VERSION ""

NS_ :

BS_:

BU_: SCM BC1 BC2 ECM PSC ABS Brakes__Drive_Axle_1 EPS IC GPS WCM VCM Seat_Control_1 ISC1 HCU IDT GMRS XM RH AUTON LHC CIM IMU BC3 IC2 EPC1 EPC2 EPC3 EPC4 BMC1 BMC2 APU2 APU1 SRVTOOL RHC RCM

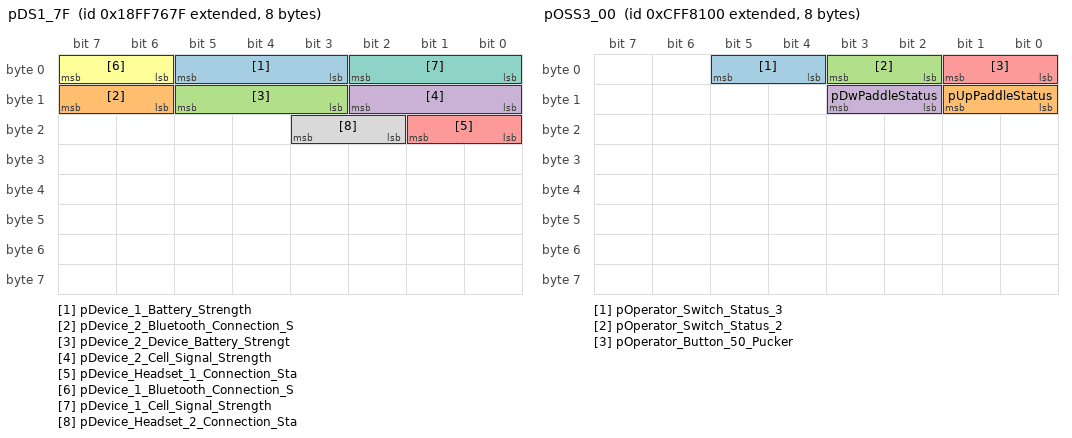
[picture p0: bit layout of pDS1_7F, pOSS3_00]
BO_ 2566878847 pDS1_7F: 8 RH
 SG_ pDevice_1_Battery_Strength : 3|3@1+ (1,0) [0|7] "state" Vector__XXX
 SG_ pDevice_2_Bluetooth_Connection_S : 14|2@1+ (1,0) [0|3] "state" Vector__XXX
 SG_ pDevice_2_Device_Battery_Strengt : 11|3@1+ (1,0) [0|7] "state" Vector__XXX
 SG_ pDevice_2_Cell_Signal_Strength : 8|3@1+ (1,0) [0|7] "state" Vector__XXX
 SG_ pDevice_Headset_1_Connection_Sta : 16|2@1+ (1,0) [0|3] "state" Vector__XXX
 SG_ pDevice_1_Bluetooth_Connection_S : 6|2@1+ (1,0) [0|3] "state" Vector__XXX
 SG_ pDevice_1_Cell_Signal_Strength : 0|3@1+ (1,0) [0|7] "state" Vector__XXX
 SG_ pDevice_Headset_2_Connection_Sta : 18|2@1+ (1,0) [0|3] "state" Vector__XXX

BO_ 2566834815 DM1_7F: 42 RH
 SG_ Flash_Malfunction_Indicator_Lamp : 14|2@1+ (1,0) [0|3] "" Vector__XXX
 SG_ Malfunction_Indicator_Lamp_Statu : 6|2@1+ (1,0) [0|3] "" Vector__XXX
 SG_ Red_Stop_Lamp_Status : 4|2@1+ (1,0) [0|3] "" Vector__XXX
 SG_ Amber_Warning_Lamp_Status : 2|2@1+ (1,0) [0|3] "" Vector__XXX
 SG_ Flash_Red_Stop_Lamp_RSL : 12|2@1+ (1,0) [0|3] "" Vector__XXX
 SG_ Flash_Amber_Warning_Lamp_AWL : 10|2@1+ (1,0) [0|3] "" Vector__XXX
 SG_ Flash_Protect_Lamp : 8|2@1+ (1,0) [0|3] "" Vector__XXX
 SG_ Protect_Lamp_Status : 0|2@1+ (1,0) [0|3] "" Vector__XXX
 SG_ DTC_1 : 16|32@1+ (1,0) [0|4294967295] "value" Vector__XXX
 SG_ DTC_2 : 48|32@1+ (1,0) [0|4294967295] "value" Vector__XXX
 SG_ DTC_3 : 80|32@1+ (1,0) [0|4294967295] "value" Vector__XXX
 SG_ DTC_4 : 112|32@1+ (1,0) [0|4294967295] "value" Vector__XXX
 SG_ DTC_5 : 144|32@1+ (1,0) [0|4294967295] "value" Vector__XXX
 SG_ DTC_6 : 176|32@1+ (1,0) [0|4294967295] "value" Vector__XXX
 SG_ DTC_7 : 208|32@1+ (1,0) [0|4294967295] "value" Vector__XXX
 SG_ DTC_8 : 240|32@1+ (1,0) [0|4294967295] "value" Vector__XXX
 SG_ DTC_9 : 272|32@1+ (1,0) [0|4294967295] "value" Vector__XXX
 SG_ DTC_10 : 304|32@1+ (1,0) [0|4294967295] "value" Vector__XXX

BO_ 2566842495 VDS_7F: 8 RH
 SG_ Compass_Bearing : 0|16@1+ (0.0078125,0) [0|511] "deg" Vector__XXX

BO_ 2561212287 DISP1_7F: 0 RH
 SG_ Text_Display_Character : 24|1@1+ (0,0) [0|-1] "ASCII" Vector__XXX
 SG_ Text_Display_Index : 16|8@1+ (1,0) [0|255] "count" Vector__XXX
 SG_ Text_Display_Instructions : 0|4@1+ (1,0) [0|15] "bit" Vector__XXX

BO_ 2365531268 pVMC_84: 8 AUTON
 SG_ pEPSReqMod : 8|8@1+ (1,0) [0|255] "state" Vector__XXX

BO_ 2365554944 pOSS3_00: 8 ECM
 SG_ pOperator_Switch_Status_3 : 4|2@1+ (1,0) [0|3] "state" RHC
 SG_ pUpPaddleStatus : 8|2@1+ (1,0) [0|3] "state" RHC
 SG_ pOperator_Switch_Status_2 : 2|2@1+ (1,0) [0|3] "state" RHC
 SG_ pDwPaddleStatus : 10|2@1+ (1,0) [0|3] "state" RHC
 SG_ pOperator_Button_50_Pucker : 0|2@1+ (1,0) [0|3] "state" RHC

BO_ 2566834823 DM1_87: 42 LHC
 SG_ Flash_Malfunction_Indicator_Lamp : 14|2@1+ (1,0) [0|3] "" Vector__XXX
 SG_ Malfunction_Indicator_Lamp_Statu : 6|2@1+ (1,0) [0|3] "" Vector__XXX
 SG_ Red_Stop_Lamp_Status : 4|2@1+ (1,0) [0|3] "" Vector__XXX
 SG_ Amber_Warning_Lamp_Status : 2|2@1+ (1,0) [0|3] "" Vector__XXX
 SG_ Flash_Red_Stop_Lamp_RSL : 12|2@1+ (1,0) [0|3] "" Vector__XXX
 SG_ Flash_Amber_Warning_Lamp_AWL : 10|2@1+ (1,0) [0|3] "" Vector__XXX
 SG_ Flash_Protect_Lamp : 8|2@1+ (1,0) [0|3] "" Vector__XXX
 SG_ Protect_Lamp_Status : 0|2@1+ (1,0) [0|3] "" Vector__XXX
 SG_ DTC_1 : 16|32@1+ (1,0) [0|4294967295] "value" Vector__XXX
 SG_ DTC_2 : 48|32@1+ (1,0) [0|4294967295] "value" Vector__XXX
 SG_ DTC_3 : 80|32@1+ (1,0) [0|4294967295] "value" Vector__XXX
 SG_ DTC_4 : 112|32@1+ (1,0) [0|4294967295] "value" Vector__XXX
 SG_ DTC_5 : 144|32@1+ (1,0) [0|4294967295] "value" Vector__XXX
 SG_ DTC_6 : 176|32@1+ (1,0) [0|4294967295] "value" Vector__XXX
 SG_ DTC_7 : 208|32@1+ (1,0) [0|4294967295] "value" Vector__XXX
 SG_ DTC_8 : 240|32@1+ (1,0) [0|4294967295] "value" Vector__XXX
 SG_ DTC_9 : 272|32@1+ (1,0) [0|4294967295] "value" Vector__XXX
 SG_ DTC_10 : 304|32@1+ (1,0) [0|4294967295] "value" Vector__XXX

BO_ 2432656519 pISC_87: 8 LHC
 SG_ Source : 8|2@1+ (1,0) [0|3] "state" Vector__XXX
 SG_ Squelch_SQ_Up : 18|2@1+ (1,0) [0|3] "state" Vector__XXX
 SG_ MutePreset : 10|2@1+ (1,0) [0|3] "state" Vector__XXX
 SG_ Volume_Down : 0|2@1+ (1,0) [0|3] "state" Vector__XXX
 SG_ Volume_Up : 2|2@1+ (1,0) [0|3] "state" Vector__XXX
 SG_ Tune_Up : 6|2@1+ (1,0) [0|3] "state" Vector__XXX
 SG_ Seek_Up : 42|2@1+ (1,0) [0|3] "state" Vector__XXX
 SG_ Tune_Down : 4|2@1+ (1,0) [0|3] "state" Vector__XXX
 SG_ Squelch_SQ_Down : 16|2@1+ (1,0) [0|3] "state" Vector__XXX
 SG_ pInfotainment_Joystick_1 : 24|4@1+ (1,0) [0|15] "state" Vector__XXX
 SG_ Preset : 22|2@1+ (1,0) [0|3] "state" Vector__XXX
 SG_ Seek_Down : 44|2@1+ (1,0) [0|3] "state" Vector__XXX
 SG_ pInfotainment_Joystick_2 : 32|4@1+ (1,0) [0|15] "state" Vector__XXX
 SG_ ICOM : 12|2@1+ (1,0) [0|3] "state" Vector__XXX
 SG_ Push_To_Talk_PTT : 20|2@1+ (1,0) [0|3] "state" Vector__XXX
 SG_ pMultifunction_Infotainment_Inte : 46|2@1+ (1,0) [0|3] "state" Vector__XXX
 SG_ COM : 14|2@1+ (1,0) [0|3] "state" Vector__XXX
 SG_ PlayPause : 40|2@1+ (1,0) [0|3] "state" Vector__XXX

BO_ 2566860167 pISM_87: 8 LHC
 SG_ pSpecial_Msg_12 : 22|2@1+ (1,0) [0|3] "state" Vector__XXX
 SG_ pSpecial_Msg_28 : 54|2@1+ (1,0) [0|3] "state" Vector__XXX
 SG_ pSpecial_Msg_11 : 20|2@1+ (1,0) [0|3] "state" Vector__XXX
 SG_ pSpecial_Msg_26 : 50|2@1+ (1,0) [0|3] "state" Vector__XXX
 SG_ pSpecial_Msg_24 : 46|2@1+ (1,0) [0|3] "state" Vector__XXX
 SG_ pSpecial_Msg_21 : 40|2@1+ (1,0) [0|3] "state" Vector__XXX
 SG_ pSpecial_Msg_18 : 34|2@1+ (1,0) [0|3] "state" Vector__XXX
 SG_ pSpecial_Msg_19 : 36|2@1+ (1,0) [0|3] "state" Vector__XXX
 SG_ pSpecial_Msg_1_Riding_with_Brake : 0|2@1+ (1,0) [0|3] "state" Vector__XXX
 SG_ pSpecial_Msg_2_Regulator_Overhea : 2|2@1+ (1,0) [0|3] "state" Vector__XXX
 SG_ pSpecial_Msg_3_Regulator_Overhea : 4|2@1+ (1,0) [0|3] "state" Vector__XXX
 SG_ pSpecial_Msg_4_Regulator_Overhea : 6|2@1+ (1,0) [0|3] "state" Vector__XXX
 SG_ pSpecial_Msg_5_Engine_Warmup_Com : 8|2@1+ (1,0) [0|3] "state" Vector__XXX
 SG_ pSpecial_Msg_6_Engine_Knock__Mod : 10|2@1+ (1,0) [0|3] "state" Vector__XXX
 SG_ pSpecial_Msg_8_Low_Coolant_Warni : 14|2@1+ (1,0) [0|3] "state" Vector__XXX
 SG_ pSpecial_Msg_7_Engine_Knock__Mos : 12|2@1+ (1,0) [0|3] "state" Vector__XXX
 SG_ pSpecial_Msg_9_Transmission_Temp : 16|2@1+ (1,0) [0|3] "state" Vector__XXX
 SG_ pSpecial_Msg_10_Reverse_Speed_Li : 18|2@1+ (1,0) [0|3] "state" Vector__XXX
 SG_ pSpecial_Msg_13_Belt_Burn_Warnin : 24|2@1+ (1,0) [0|3] "state" Vector__XXX
 SG_ pSpecial_Msg_14_Park_Brake_Warni : 26|2@1+ (1,0) [0|3] "state" Vector__XXX
 SG_ pSpecial_Msg_15_TCM_Comm_Loss : 28|2@1+ (1,0) [0|3] "state" Vector__XXX
 SG_ pSpecial_Msg_16_TCM_Pump_Priming : 30|2@1+ (1,0) [0|3] "state" Vector__XXX
 SG_ pSpecial_Msg_17_Request_User_to_ : 32|2@1+ (1,0) [0|3] "state" Vector__XXX
 SG_ pSpecial_MSG_20_Fuel_Door_Open_E : 38|2@1+ (1,0) [0|3] "state" Vector__XXX
 SG_ pSpecial_MSG_22_Clutch_Overtemp : 42|2@1+ (1,0) [0|3] "state" Vector__XXX
 SG_ pSpecial_MSG_23_Exhaust_Valve_Ch : 44|2@1+ (1,0) [0|3] "state" Vector__XXX
 SG_ pSpecial_MSG_25_Engine_Idle_Shut : 48|2@1+ (1,0) [0|3] "state" Vector__XXX
 SG_ pSpecial_MSG_27_Overboost_Condit : 52|2@1+ (1,0) [0|3] "state" Vector__XXX
 SG_ pSpecial_Msg_31_Engine_Tip_Over_ : 60|2@1+ (1,0) [0|3] "state" Vector__XXX
 SG_ pSpecial_Msg_32_Engine_Tip_Over_ : 62|2@1+ (1,0) [0|3] "state" Vector__XXX

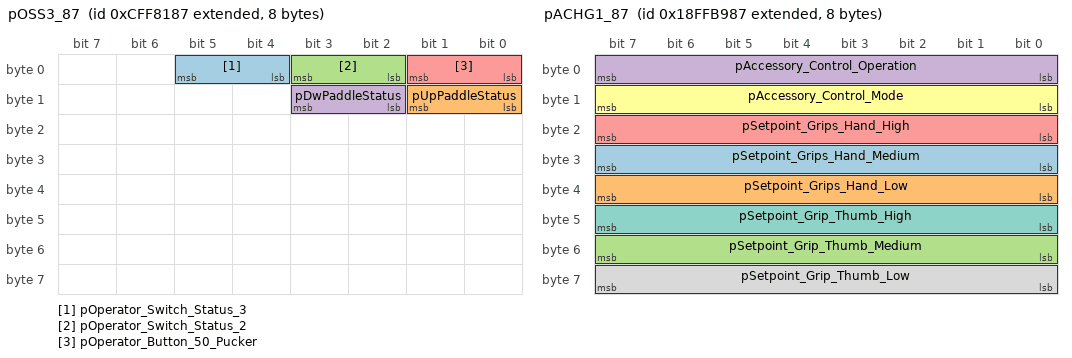
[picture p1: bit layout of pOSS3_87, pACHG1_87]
BO_ 2365555079 pOSS3_87: 8 LHC
 SG_ pOperator_Switch_Status_3 : 4|2@1+ (1,0) [0|3] "state" Vector__XXX
 SG_ pUpPaddleStatus : 8|2@1+ (1,0) [0|3] "state" Vector__XXX
 SG_ pOperator_Switch_Status_2 : 2|2@1+ (1,0) [0|3] "state" Vector__XXX
 SG_ pDwPaddleStatus : 10|2@1+ (1,0) [0|3] "state" Vector__XXX
 SG_ pOperator_Button_50_Pucker : 0|2@1+ (1,0) [0|3] "state" Vector__XXX

BO_ 2566896007 pACHG1_87: 8 LHC
 SG_ pSetpoint_Grips_Hand_Medium : 24|8@1+ (1,0) [0|255] "deg C" Vector__XXX
 SG_ pSetpoint_Grips_Hand_Low : 32|8@1+ (1,0) [0|255] "deg C" Vector__XXX
 SG_ pSetpoint_Grip_Thumb_Medium : 48|8@1+ (1,0) [0|255] "deg C" Vector__XXX
 SG_ pAccessory_Control_Operation : 0|8@1+ (1,0) [0|255] "state" Vector__XXX
 SG_ pSetpoint_Grips_Hand_High : 16|8@1+ (1,0) [0|255] "deg C" Vector__XXX
 SG_ pAccessory_Control_Mode : 8|8@1+ (1,0) [0|255] "state" Vector__XXX
 SG_ pSetpoint_Grip_Thumb_High : 40|8@1+ (1,0) [0|255] "deg C" Vector__XXX
 SG_ pSetpoint_Grip_Thumb_Low : 56|8@1+ (1,0) [0|255] "deg C" Vector__XXX

BO_ 2566844807 CCVS1_87: 8 LHC
 SG_ Cruise_Control_Set_Speed : 40|8@1+ (1,0) [0|255] "km/h" Vector__XXX
 SG_ Cruise_Control_Active : 24|2@1+ (1,0) [0|3] "bit" Vector__XXX
 SG_ Clutch_Switch : 30|2@1+ (1,0) [0|3] "bit" Vector__XXX
 SG_ Brake_Switch : 28|2@1+ (1,0) [0|3] "bit" Vector__XXX
 SG_ pCC_Message_Counter : 52|4@1+ (1,0) [0|15] "count" Vector__XXX
 SG_ Cruise_Control_Pause_Switch : 4|2@1+ (1,0) [0|3] "bit" Vector__XXX
 SG_ Cruise_Control_Set_Switch : 32|2@1+ (1,0) [0|3] "bit" Vector__XXX
 SG_ Two_Speed_Axle_Switch : 0|2@1+ (1,0) [0|3] "bit" Vector__XXX
 SG_ Cruise_Control_Enable_Switch : 26|2@1+ (1,0) [0|3] "bit" Vector__XXX
 SG_ pOdometer_Drive_Bit : 6|2@1+ (1,0) [0|3] "state" Vector__XXX
 SG_ pCC_Checksum : 56|8@1+ (1,0) [0|255] "" Vector__XXX
 SG_ WheelBased_Vehicle_Speed : 8|16@1+ (0.00390625,0) [0|255] "km/h" Vector__XXX
 SG_ Cruise_Control_Resume_Switch : 36|2@1+ (1,0) [0|3] "bit" Vector__XXX
 SG_ Cruise_Control_Accelerate_Switch : 38|2@1+ (1,0) [0|3] "bit" Vector__XXX
 SG_ pCruise_Enable_Status : 48|4@1+ (1,0) [0|15] "state" Vector__XXX
 SG_ Parking_Brake_Switch : 2|2@1+ (1,0) [0|3] "bit" Vector__XXX
 SG_ Cruise_Control_Coast_Decelerate_ : 34|2@1+ (1,0) [0|3] "bit" Vector__XXX

BO_ 2566835079 DM2_87: 42 LHC
 SG_ Protect_Lamp_Status : 0|2@1+ (1,0) [0|3] "" Vector__XXX
 SG_ Amber_Warning_Lamp_Status : 2|2@1+ (1,0) [0|3] "" Vector__XXX
 SG_ Red_Stop_Lamp_Status : 4|2@1+ (1,0) [0|3] "" Vector__XXX
 SG_ Malfunction_Indicator_Lamp_Statu : 6|2@1+ (1,0) [0|3] "" Vector__XXX
 SG_ Flash_Protect_Lamp : 8|2@1+ (1,0) [0|3] "" Vector__XXX
 SG_ Flash_Amber_Warning_Lamp_AWL : 10|2@1+ (1,0) [0|3] "" Vector__XXX
 SG_ Flash_Red_Stop_Lamp_RSL : 12|2@1+ (1,0) [0|3] "" Vector__XXX
 SG_ Flash_Malfunction_Indicator_Lamp : 14|2@1+ (1,0) [0|3] "" Vector__XXX
 SG_ DTC_1 : 16|32@1+ (1,0) [0|4294967295] "value" Vector__XXX
 SG_ DTC_2 : 48|32@1+ (1,0) [0|4294967295] "value" Vector__XXX
 SG_ DTC_3 : 80|32@1+ (1,0) [0|4294967295] "value" Vector__XXX
 SG_ DTC_4 : 112|32@1+ (1,0) [0|4294967295] "value" Vector__XXX
 SG_ DTC_5 : 144|32@1+ (1,0) [0|4294967295] "value" Vector__XXX
 SG_ DTC_6 : 176|32@1+ (1,0) [0|4294967295] "value" Vector__XXX
 SG_ DTC_7 : 208|32@1+ (1,0) [0|4294967295] "value" Vector__XXX
 SG_ DTC_8 : 240|32@1+ (1,0) [0|4294967295] "value" Vector__XXX
 SG_ DTC_9 : 272|32@1+ (1,0) [0|4294967295] "value" Vector__XXX
 SG_ DTC_10 : 304|32@1+ (1,0) [0|4294967295] "value" Vector__XXX

BO_ 2432656775 pOSS1_87: 8 LHC
 SG_ Key_Fob_Unlock_Button_Status : 30|2@1+ (1,0) [0|3] "state" Vector__XXX
 SG_ Homelink_2 : 44|2@1+ (1,0) [0|3] "state" Vector__XXX
 SG_ Side_Stand_Switch : 56|2@1+ (1,0) [0|3] "state" Vector__XXX
 SG_ Key_Fob_Lock_Button_Status : 32|2@1+ (1,0) [0|3] "state" Vector__XXX
 SG_ Windshield__2_Down : 50|2@1+ (1,0) [0|3] "state" Vector__XXX
 SG_ Turn__3_Cancel : 14|2@1+ (1,0) [0|3] "state" Vector__XXX
 SG_ Reverse : 40|2@1+ (1,0) [0|3] "state" Vector__XXX
 SG_ Hazard : 16|2@1+ (1,0) [0|3] "state" Vector__XXX
 SG_ Homelink_1 : 42|2@1+ (1,0) [0|3] "state" Vector__XXX
 SG_ Windshield__1_Up : 48|2@1+ (1,0) [0|3] "state" Vector__XXX
 SG_ Front_Brake_Switch : 52|2@1+ (1,0) [0|3] "state" Vector__XXX
 SG_ Instrument_Cluster_Control__2 : 2|2@1+ (1,0) [0|3] "state" Vector__XXX
 SG_ Chassis_Unlock_Button_Status : 34|2@1+ (1,0) [0|3] "state" Vector__XXX
 SG_ Power_Button : 58|2@1+ (1,0) [0|3] "state" Vector__XXX
 SG_ RunStop_Switch : 38|2@1+ (1,0) [0|3] "state" Vector__XXX
 SG_ Headlamp__2_High : 6|2@1+ (1,0) [0|3] "state" Vector__XXX
 SG_ Instrument_Cluster_Control__1 : 0|2@1+ (1,0) [0|3] "state" Vector__XXX
 SG_ Clutch_Switch : 54|2@1+ (1,0) [0|3] "state" Vector__XXX
 SG_ Start : 26|2@1+ (1,0) [0|3] "state" Vector__XXX
 SG_ Headlamp__3_Driving : 8|2@1+ (1,0) [0|3] "state" Vector__XXX
 SG_ Cruise__2_Set : 20|2@1+ (1,0) [0|3] "state" Vector__XXX
 SG_ Windshield_Wiper : 36|2@1+ (1,0) [0|3] "state" Vector__XXX
 SG_ Fog : 28|2@1+ (1,0) [0|3] "state" Vector__XXX
 SG_ Cruise__3_Accel : 22|2@1+ (1,0) [0|3] "state" Vector__XXX
 SG_ Horn : 24|2@1+ (1,0) [0|3] "state" Vector__XXX
 SG_ Turn__2_Right : 12|2@1+ (1,0) [0|3] "state" Vector__XXX
 SG_ Cruise__1_On : 18|2@1+ (1,0) [0|3] "state" Vector__XXX
 SG_ Turn__1_Left : 10|2@1+ (1,0) [0|3] "state" Vector__XXX
 SG_ Throttle_Safety_Switch__1 : 46|2@1+ (1,0) [0|3] "state" Vector__XXX
 SG_ Headlamp__1_Low : 4|2@1+ (1,0) [0|3] "state" Vector__XXX
 SG_ Chassis_Lock_Switch_Status : 62|2@1+ (1,0) [0|3] "unknown" Vector__XXX
 SG_ Fuel_Door_Unlock_Button_Status : 60|2@1+ (1,0) [0|3] "state" Vector__XXX

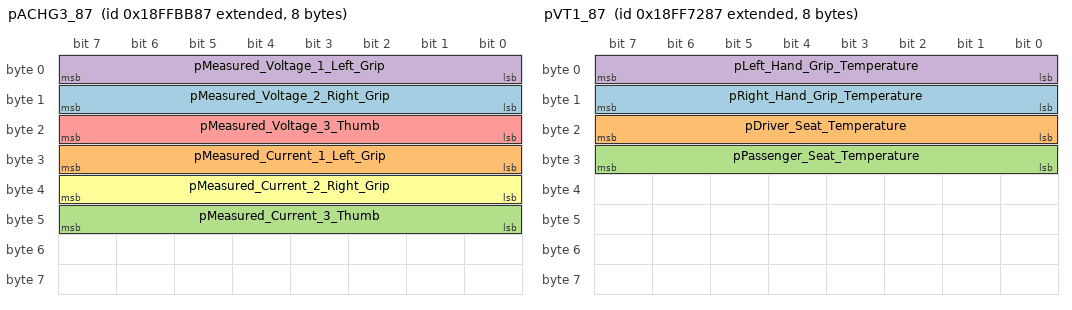
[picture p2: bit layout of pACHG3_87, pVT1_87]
BO_ 2566896519 pACHG3_87: 8 LHC
 SG_ pMeasured_Voltage_2_Right_Grip : 8|8@1+ (0.075,0) [0|18.2] "V" Vector__XXX
 SG_ pMeasured_Current_1_Left_Grip : 24|8@1+ (0.05,0) [0|11.8] "A" Vector__XXX
 SG_ pMeasured_Current_3_Thumb : 40|8@1+ (0.05,0) [0|11.8] "A" Vector__XXX
 SG_ pMeasured_Voltage_1_Left_Grip : 0|8@1+ (0.075,0) [0|18.2] "V" Vector__XXX
 SG_ pMeasured_Voltage_3_Thumb : 16|8@1+ (0.075,0) [0|18.2] "V" Vector__XXX
 SG_ pMeasured_Current_2_Right_Grip : 32|8@1+ (0.05,0) [0|11.8] "A" Vector__XXX

BO_ 2633984647 pDSS_87: 8 LHC
 SG_ pHeated_Grip_Enable : 48|2@1+ (1,0) [0|3] "state" Vector__XXX
 SG_ pUser_PIN_Access_Status : 26|2@1+ (1,0) [0|3] "state" Vector__XXX
 SG_ pActive_Descent_Control_ADC_Stat : 0|2@1+ (1,0) [0|3] "state" Vector__XXX
 SG_ pCruise_Control_Set_Status : 24|2@1+ (1,0) [0|3] "state" Vector__XXX
 SG_ pTether_Switch_Status : 46|2@1+ (1,0) [0|3] "state" Vector__XXX
 SG_ pHigh_Beam_Indicator_Status : 8|2@1+ (1,0) [0|3] "state" Vector__XXX
 SG_ pLow_Fuel_Indicator_Status : 10|2@1+ (1,0) [0|3] "state" Vector__XXX
 SG_ pHeated_Grips_Percentage : 16|8@1+ (0.4,0) [0|101.4] "%" Vector__XXX
 SG_ pSide_Stand_Status : 36|2@1+ (1,0) [0|3] "state" Vector__XXX
 SG_ pTurf_Mode_Requested : 28|2@1+ (1,0) [0|3] "state" Vector__XXX
 SG_ pEngine_Idle_Shutdown_Timer : 54|10@1+ (1,0) [0|1023] "state" Vector__XXX
 SG_ Operator_Not_in_Operating_Statio : 38|2@1+ (1,0) [0|3] "state" Vector__XXX
 SG_ pAWD_Mode_Requested : 32|2@1+ (1,0) [0|3] "state" Vector__XXX
 SG_ pHeated_Grips_Up_Switch_Status : 50|2@1+ (1,0) [0|3] "state" Vector__XXX
 SG_ pTreadle_Neutral_Status : 2|2@1+ (1,0) [0|3] "state" Vector__XXX
 SG_ pHeated_Grips_Down_Switch_Status : 52|2@1+ (1,0) [0|3] "state" Vector__XXX
 SG_ pPark_Brake_Indicator_Status : 40|3@1+ (1,0) [0|7] "state" Vector__XXX
 SG_ pRWD_Mode_Requested : 30|2@1+ (1,0) [0|3] "state" Vector__XXX
 SG_ pSeat_Belt_Indicator_Status : 12|3@1+ (1,0) [0|7] "state" Vector__XXX
 SG_ pSecurity_Light_Immobilizer_Stat : 6|2@1+ (1,0) [0|3] "state" Vector__XXX
 SG_ ECU_Security_Status : 43|3@1+ (1,0) [0|7] "state" Vector__XXX
 SG_ pActive_Decent_Control_ADC_Mode_ : 34|2@1+ (1,0) [0|3] "state" Vector__XXX
 SG_ pTreadle_Reverse_Status : 4|2@1+ (1,0) [0|3] "state" Vector__XXX

BO_ 2566877831 pVT1_87: 8 LHC
 SG_ pRight_Hand_Grip_Temperature : 8|8@1+ (1,-40) [-40|295] "deg C" Vector__XXX
 SG_ pDriver_Seat_Temperature : 16|8@1+ (1,-40) [-40|295] "deg C" Vector__XXX
 SG_ pPassenger_Seat_Temperature : 24|8@1+ (1,-40) [-40|295] "deg C" Vector__XXX
 SG_ pLeft_Hand_Grip_Temperature : 0|8@1+ (1,-40) [-40|295] "deg C" Vector__XXX

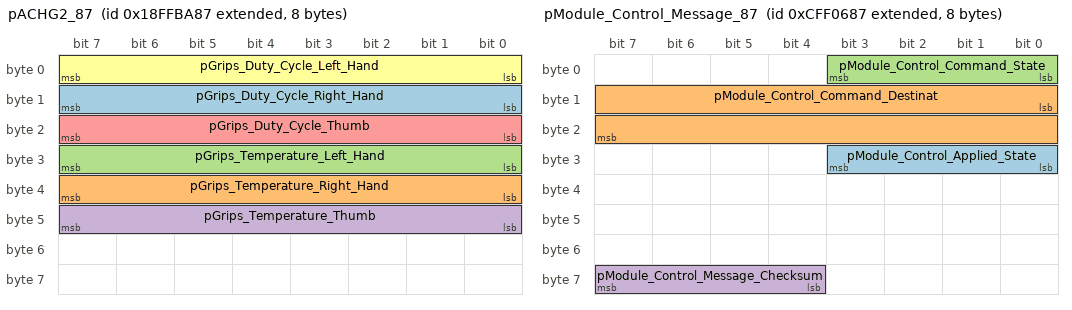
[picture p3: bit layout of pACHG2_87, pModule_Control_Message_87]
BO_ 2566896263 pACHG2_87: 8 LHC
 SG_ pGrips_Duty_Cycle_Right_Hand : 8|8@1+ (1,0) [0|255] "%" Vector__XXX
 SG_ pGrips_Temperature_Right_Hand : 32|8@1+ (1,-40) [-40|295] "deg C" Vector__XXX
 SG_ pGrips_Temperature_Left_Hand : 24|8@1+ (1,-40) [-40|295] "deg C" Vector__XXX
 SG_ pGrips_Temperature_Thumb : 40|8@1+ (1,-40) [-40|295] "deg C" Vector__XXX
 SG_ pGrips_Duty_Cycle_Thumb : 16|8@1+ (1,0) [0|255] "%" Vector__XXX
 SG_ pGrips_Duty_Cycle_Left_Hand : 0|8@1+ (1,0) [0|255] "%" Vector__XXX

BO_ 2365523591 pModule_Control_Message_87: 8 LHC
 SG_ pModule_Control_Applied_State : 24|4@1+ (1,0) [0|15] "state" Vector__XXX
 SG_ pModule_Control_Command_Destinat : 8|16@1+ (1,0) [0|65535] "count" Vector__XXX
 SG_ pModule_Control_Command_State : 0|4@1+ (1,0) [0|15] "state" Vector__XXX
 SG_ pModule_Control_Message_Checksum : 60|4@1+ (1,0) [0|15] "bit" Vector__XXX

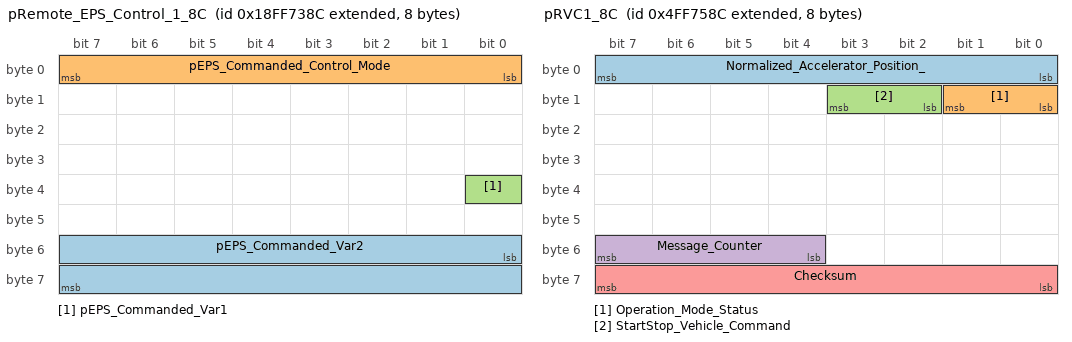
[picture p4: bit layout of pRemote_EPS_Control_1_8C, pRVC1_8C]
BO_ 2566878092 pRemote_EPS_Control_1_8C: 8 CIM
 SG_ pEPS_Commanded_Var2 : 48|16@1+ (1,0) [0|65535] "" Vector__XXX
 SG_ pEPS_Commanded_Control_Mode : 0|8@1+ (1,0) [0|255] "state" Vector__XXX
 SG_ pEPS_Commanded_Var1 : 32|1@1+ (1,0) [0|0] "" Vector__XXX

BO_ 2231334284 pRVC1_8C: 8 CIM
 SG_ Normalized_Accelerator_Position_ : 0|8@1+ (0.4,0) [0|101.4] "" Vector__XXX
 SG_ Operation_Mode_Status : 8|2@1+ (1,0) [0|3] "state" Vector__XXX
 SG_ StartStop_Vehicle_Command : 10|2@1+ (1,0) [0|3] "" Vector__XXX
 SG_ Message_Counter : 52|4@1+ (1,0) [0|15] "" Vector__XXX
 SG_ Checksum : 56|8@1+ (1,0) [0|255] "" Vector__XXX

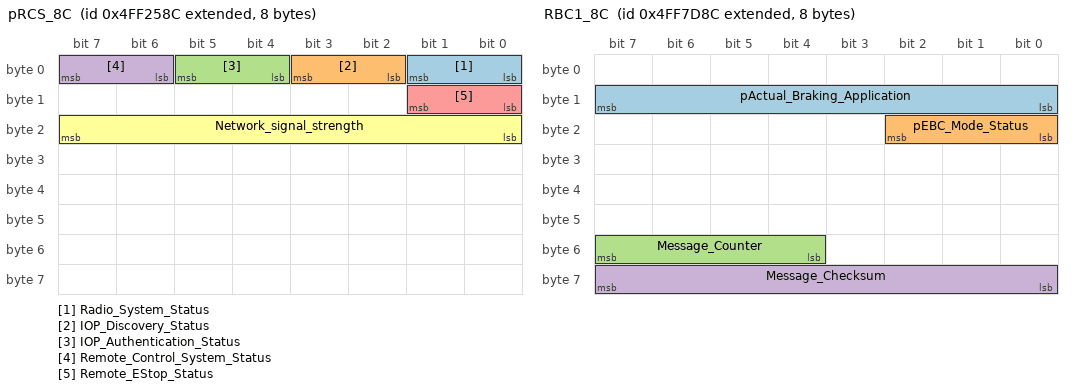
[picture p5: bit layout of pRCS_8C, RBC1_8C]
BO_ 2231313804 pRCS_8C: 8 CIM
 SG_ Radio_System_Status : 0|2@1+ (1,0) [0|3] "state" Vector__XXX
 SG_ IOP_Discovery_Status : 2|2@1+ (1,0) [0|3] "state" Vector__XXX
 SG_ IOP_Authentication_Status : 4|2@1+ (1,0) [0|3] "state" Vector__XXX
 SG_ Remote_Control_System_Status : 6|2@1+ (1,0) [0|3] "state" Vector__XXX
 SG_ Remote_EStop_Status : 8|2@1+ (1,0) [0|3] "state" Vector__XXX
 SG_ Network_signal_strength : 16|8@1+ (1,0) [0|255] "%" Vector__XXX

BO_ 2231336332 RBC1_8C: 8 CIM
 SG_ pActual_Braking_Application : 8|8@1+ (0.4,0) [0|101.4] "" Vector__XXX
 SG_ pEBC_Mode_Status : 16|3@1+ (1,0) [0|7] "state" Vector__XXX
 SG_ Message_Counter : 52|4@1+ (1,0) [0|15] "" Vector__XXX
 SG_ Message_Checksum : 56|8@1+ (1,0) [0|255] "" Vector__XXX

BO_ 2365531276 pVMC_8C: 8 CIM
 SG_ pEPSReqMod : 8|8@1+ (1,0) [0|255] "state" Vector__XXX

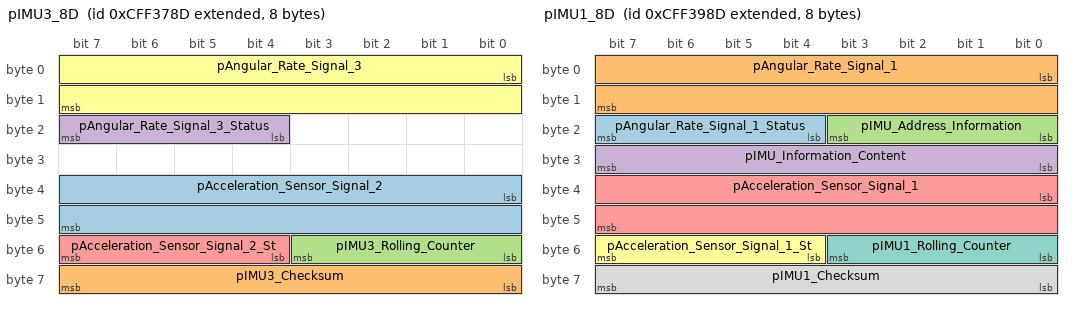
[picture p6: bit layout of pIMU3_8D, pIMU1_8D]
BO_ 2365536141 pIMU3_8D: 8 IMU
 SG_ pAcceleration_Sensor_Signal_2 : 32|16@1+ (0.0001275,-4.1768) [-4.1768|11.53264] "g" Vector__XXX
 SG_ pIMU3_Checksum : 56|8@1+ (1,0) [0|255] "count" Vector__XXX
 SG_ pIMU3_Rolling_Counter : 48|4@1+ (1,0) [0|15] "count" Vector__XXX
 SG_ pAngular_Rate_Signal_3_Status : 20|4@1+ (1,0) [0|15] "state" Vector__XXX
 SG_ pAcceleration_Sensor_Signal_2_St : 52|4@1+ (1,0) [0|15] "count" Vector__XXX
 SG_ pAngular_Rate_Signal_3 : 0|16@1+ (0.005,-163.64) [-163.64|490.32] "" Vector__XXX

BO_ 2365536653 pIMU1_8D: 8 IMU
 SG_ pAngular_Rate_Signal_1_Status : 20|4@1+ (1,0) [0|15] "bit" Vector__XXX
 SG_ pAngular_Rate_Signal_1 : 0|16@1+ (0.005,-163.84) [-163.84|490.52] "" Vector__XXX
 SG_ pIMU_Address_Information : 16|4@1+ (1,0) [0|15] "ASCII" Vector__XXX
 SG_ pIMU_Information_Content : 24|8@1+ (1,0) [0|255] "ASCII" Vector__XXX
 SG_ pAcceleration_Sensor_Signal_1 : 32|16@1+ (0.0001275,-4.1768) [-4.1768|11.53264] "g" Vector__XXX
 SG_ pAcceleration_Sensor_Signal_1_St : 52|4@1+ (1,0) [0|15] "count" Vector__XXX
 SG_ pIMU1_Rolling_Counter : 48|4@1+ (1,0) [0|15] "count" Vector__XXX
 SG_ pIMU1_Checksum : 56|8@1+ (1,0) [0|255] "count" Vector__XXX

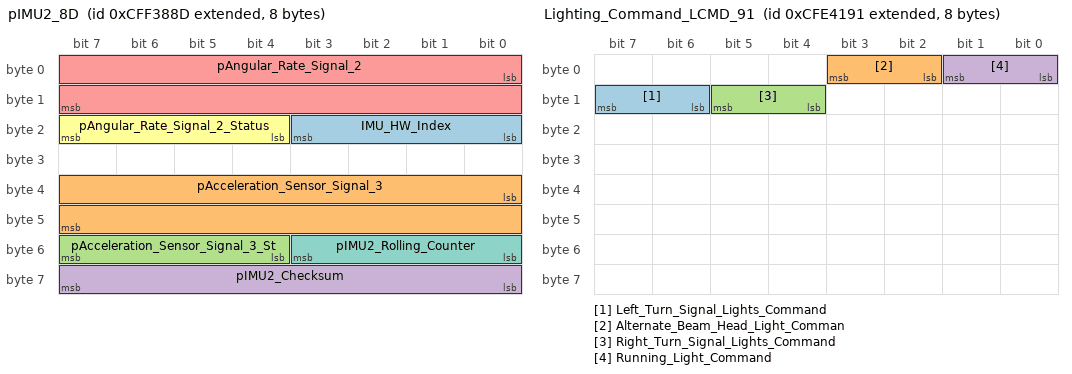
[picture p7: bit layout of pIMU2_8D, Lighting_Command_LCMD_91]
BO_ 2365536397 pIMU2_8D: 8 IMU
 SG_ IMU_HW_Index : 16|4@1+ (1,0) [0|15] "" Vector__XXX
 SG_ pAcceleration_Sensor_Signal_3 : 32|16@1+ (0.0001275,-4.1768) [-4.1768|11.53264] "g" Vector__XXX
 SG_ pAcceleration_Sensor_Signal_3_St : 52|4@1+ (1,0) [0|15] "state" Vector__XXX
 SG_ pIMU2_Checksum : 56|8@1+ (1,0) [0|255] "count" Vector__XXX
 SG_ pAngular_Rate_Signal_2 : 0|16@1+ (0.005,-163.84) [-163.84|490.52] "" Vector__XXX
 SG_ pAngular_Rate_Signal_2_Status : 20|4@1+ (1,0) [0|15] "bit" Vector__XXX
 SG_ pIMU2_Rolling_Counter : 48|4@1+ (1,0) [0|15] "count" Vector__XXX

BO_ 2432656784 pOSS1_90: 8 BC2
 SG_ Key_Fob_Unlock_Button_Status : 30|2@1+ (1,0) [0|3] "state" Vector__XXX
 SG_ Homelink_2 : 44|2@1+ (1,0) [0|3] "state" Vector__XXX
 SG_ Side_Stand_Switch : 56|2@1+ (1,0) [0|3] "state" Vector__XXX
 SG_ Key_Fob_Lock_Button_Status : 32|2@1+ (1,0) [0|3] "state" Vector__XXX
 SG_ Windshield__2_Down : 50|2@1+ (1,0) [0|3] "state" Vector__XXX
 SG_ Turn__3_Cancel : 14|2@1+ (1,0) [0|3] "state" Vector__XXX
 SG_ Reverse : 40|2@1+ (1,0) [0|3] "state" Vector__XXX
 SG_ Hazard : 16|2@1+ (1,0) [0|3] "state" Vector__XXX
 SG_ Homelink_1 : 42|2@1+ (1,0) [0|3] "state" Vector__XXX
 SG_ Windshield__1_Up : 48|2@1+ (1,0) [0|3] "state" Vector__XXX
 SG_ Front_Brake_Switch : 52|2@1+ (1,0) [0|3] "state" Vector__XXX
 SG_ Instrument_Cluster_Control__2 : 2|2@1+ (1,0) [0|3] "state" Vector__XXX
 SG_ Chassis_Unlock_Button_Status : 34|2@1+ (1,0) [0|3] "state" Vector__XXX
 SG_ Power_Button : 58|2@1+ (1,0) [0|3] "state" Vector__XXX
 SG_ RunStop_Switch : 38|2@1+ (1,0) [0|3] "state" Vector__XXX
 SG_ Headlamp__2_High : 6|2@1+ (1,0) [0|3] "state" Vector__XXX
 SG_ Instrument_Cluster_Control__1 : 0|2@1+ (1,0) [0|3] "state" Vector__XXX
 SG_ Clutch_Switch : 54|2@1+ (1,0) [0|3] "state" Vector__XXX
 SG_ Start : 26|2@1+ (1,0) [0|3] "state" Vector__XXX
 SG_ Headlamp__3_Driving : 8|2@1+ (1,0) [0|3] "state" Vector__XXX
 SG_ Cruise__2_Set : 20|2@1+ (1,0) [0|3] "state" Vector__XXX
 SG_ Windshield_Wiper : 36|2@1+ (1,0) [0|3] "state" Vector__XXX
 SG_ Fog : 28|2@1+ (1,0) [0|3] "state" Vector__XXX
 SG_ Cruise__3_Accel : 22|2@1+ (1,0) [0|3] "state" Vector__XXX
 SG_ Horn : 24|2@1+ (1,0) [0|3] "state" Vector__XXX
 SG_ Turn__2_Right : 12|2@1+ (1,0) [0|3] "state" Vector__XXX
 SG_ Cruise__1_On : 18|2@1+ (1,0) [0|3] "state" Vector__XXX
 SG_ Turn__1_Left : 10|2@1+ (1,0) [0|3] "state" Vector__XXX
 SG_ Throttle_Safety_Switch__1 : 46|2@1+ (1,0) [0|3] "state" Vector__XXX
 SG_ Headlamp__1_Low : 4|2@1+ (1,0) [0|3] "state" Vector__XXX
 SG_ Chassis_Lock_Switch_Status : 62|2@1+ (1,0) [0|3] "unknown" Vector__XXX
 SG_ Fuel_Door_Unlock_Button_Status : 60|2@1+ (1,0) [0|3] "state" Vector__XXX

BO_ 2365473169 Lighting_Command_LCMD_91: 8 BC3
 SG_ Left_Turn_Signal_Lights_Command : 14|2@1+ (1,0) [0|3] "bit" Vector__XXX
 SG_ Alternate_Beam_Head_Light_Comman : 2|2@1+ (1,0) [0|3] "bit" Vector__XXX
 SG_ Right_Turn_Signal_Lights_Command : 12|2@1+ (1,0) [0|3] "bit" Vector__XXX
 SG_ Running_Light_Command : 0|2@1+ (1,0) [0|3] "bit" Vector__XXX

BO_ 2563833767 CL_A7: 8 IC2
 SG_ Illumination_Brightness_Percent : 0|8@1+ (0.4,0) [0|101.4] "%" Vector__XXX

BO_ 2566847655 DD_A7: 8 IC2
 SG_ Fuel_Level_1 : 8|8@1+ (0.4,0) [0|101.4] "%" Vector__XXX

BO_ 2566834855 DM1_A7: 42 IC2
 SG_ Flash_Malfunction_Indicator_Lamp : 14|2@1+ (1,0) [0|3] "" Vector__XXX
 SG_ Malfunction_Indicator_Lamp_Statu : 6|2@1+ (1,0) [0|3] "" Vector__XXX
 SG_ Red_Stop_Lamp_Status : 4|2@1+ (1,0) [0|3] "" Vector__XXX
 SG_ Amber_Warning_Lamp_Status : 2|2@1+ (1,0) [0|3] "" Vector__XXX
 SG_ Flash_Red_Stop_Lamp_RSL : 12|2@1+ (1,0) [0|3] "" Vector__XXX
 SG_ Flash_Amber_Warning_Lamp_AWL : 10|2@1+ (1,0) [0|3] "" Vector__XXX
 SG_ Flash_Protect_Lamp : 8|2@1+ (1,0) [0|3] "" Vector__XXX
 SG_ Protect_Lamp_Status : 0|2@1+ (1,0) [0|3] "" Vector__XXX
 SG_ DTC_1 : 16|32@1+ (1,0) [0|4294967295] "value" Vector__XXX
 SG_ DTC_2 : 48|32@1+ (1,0) [0|4294967295] "value" Vector__XXX
 SG_ DTC_3 : 80|32@1+ (1,0) [0|4294967295] "value" Vector__XXX
 SG_ DTC_4 : 112|32@1+ (1,0) [0|4294967295] "value" Vector__XXX
 SG_ DTC_5 : 144|32@1+ (1,0) [0|4294967295] "value" Vector__XXX
 SG_ DTC_6 : 176|32@1+ (1,0) [0|4294967295] "value" Vector__XXX
 SG_ DTC_7 : 208|32@1+ (1,0) [0|4294967295] "value" Vector__XXX
 SG_ DTC_8 : 240|32@1+ (1,0) [0|4294967295] "value" Vector__XXX
 SG_ DTC_9 : 272|32@1+ (1,0) [0|4294967295] "value" Vector__XXX
 SG_ DTC_10 : 304|32@1+ (1,0) [0|4294967295] "value" Vector__XXX

BO_ 2566844839 CCVS1_A7: 8 IC2
 SG_ Cruise_Control_Set_Speed : 40|8@1+ (1,0) [0|255] "km/h" Vector__XXX
 SG_ Cruise_Control_Active : 24|2@1+ (1,0) [0|3] "bit" Vector__XXX
 SG_ Clutch_Switch : 30|2@1+ (1,0) [0|3] "bit" Vector__XXX
 SG_ Brake_Switch : 28|2@1+ (1,0) [0|3] "bit" Vector__XXX
 SG_ pCC_Message_Counter : 52|4@1+ (1,0) [0|15] "count" Vector__XXX
 SG_ Cruise_Control_Pause_Switch : 4|2@1+ (1,0) [0|3] "bit" Vector__XXX
 SG_ Cruise_Control_Set_Switch : 32|2@1+ (1,0) [0|3] "bit" Vector__XXX
 SG_ Two_Speed_Axle_Switch : 0|2@1+ (1,0) [0|3] "bit" Vector__XXX
 SG_ Cruise_Control_Enable_Switch : 26|2@1+ (1,0) [0|3] "bit" Vector__XXX
 SG_ pOdometer_Drive_Bit : 6|2@1+ (1,0) [0|3] "state" Vector__XXX
 SG_ pCC_Checksum : 56|8@1+ (1,0) [0|255] "" Vector__XXX
 SG_ WheelBased_Vehicle_Speed : 8|16@1+ (0.00390625,0) [0|255] "km/h" Vector__XXX
 SG_ Cruise_Control_Resume_Switch : 36|2@1+ (1,0) [0|3] "bit" Vector__XXX
 SG_ Cruise_Control_Accelerate_Switch : 38|2@1+ (1,0) [0|3] "bit" Vector__XXX
 SG_ pCruise_Enable_Status : 48|4@1+ (1,0) [0|15] "state" Vector__XXX
 SG_ Parking_Brake_Switch : 2|2@1+ (1,0) [0|3] "bit" Vector__XXX
 SG_ Cruise_Control_Coast_Decelerate_ : 34|2@1+ (1,0) [0|3] "bit" Vector__XXX

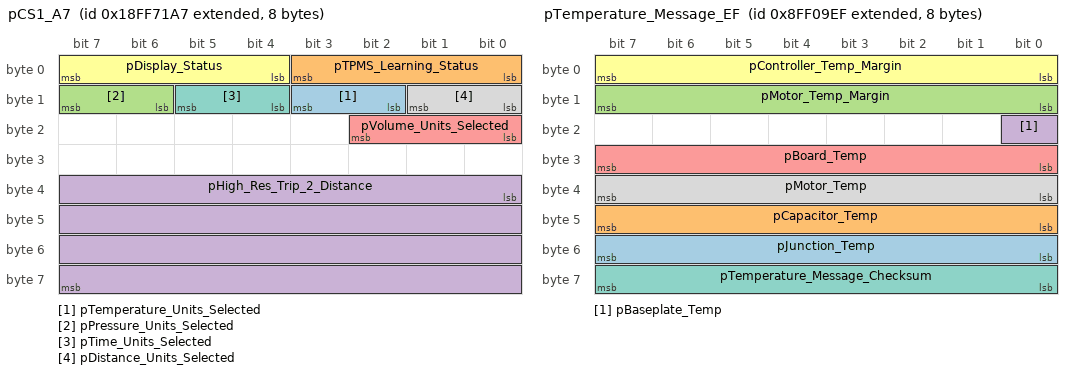
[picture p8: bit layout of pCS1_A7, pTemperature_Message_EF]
BO_ 2566877607 pCS1_A7: 8 IC2
 SG_ pTemperature_Units_Selected : 10|2@1+ (1,0) [0|3] "state" Vector__XXX
 SG_ pTPMS_Learning_Status : 0|4@1+ (1,0) [0|15] "state" Vector__XXX
 SG_ pPressure_Units_Selected : 14|2@1+ (1,0) [0|3] "state" Vector__XXX
 SG_ pHigh_Res_Trip_2_Distance : 32|32@1+ (5,0) [0|21474836479] "km" Vector__XXX
 SG_ pVolume_Units_Selected : 16|3@1+ (1,0) [0|7] "state" Vector__XXX
 SG_ pDisplay_Status : 4|4@1+ (1,0) [0|15] "state" Vector__XXX
 SG_ pTime_Units_Selected : 12|2@1+ (1,0) [0|3] "state" Vector__XXX
 SG_ pDistance_Units_Selected : 8|2@1+ (1,0) [0|3] "state" Vector__XXX

BO_ 2298415599 pTemperature_Message_EF: 8 EPC1
 SG_ pJunction_Temp : 48|8@1+ (1,-40) [-40|295] "deg C" Vector__XXX
 SG_ pCapacitor_Temp : 40|8@1+ (1,-40) [-40|295] "deg C" Vector__XXX
 SG_ pMotor_Temp_Margin : 8|8@1+ (1,0) [0|255] "deg C" Vector__XXX
 SG_ pBaseplate_Temp : 16|1@1+ (1,-40) [-40|40] "deg C" Vector__XXX
 SG_ pBoard_Temp : 24|8@1+ (1,-40) [-40|295] "deg C" Vector__XXX
 SG_ pController_Temp_Margin : 0|8@1+ (1,0) [0|255] "deg C" Vector__XXX
 SG_ pTemperature_Message_Checksum : 56|8@1+ (1,0) [0|255] "" Vector__XXX
 SG_ pMotor_Temp : 32|8@1+ (1,-40) [-40|295] "deg C" Vector__XXX

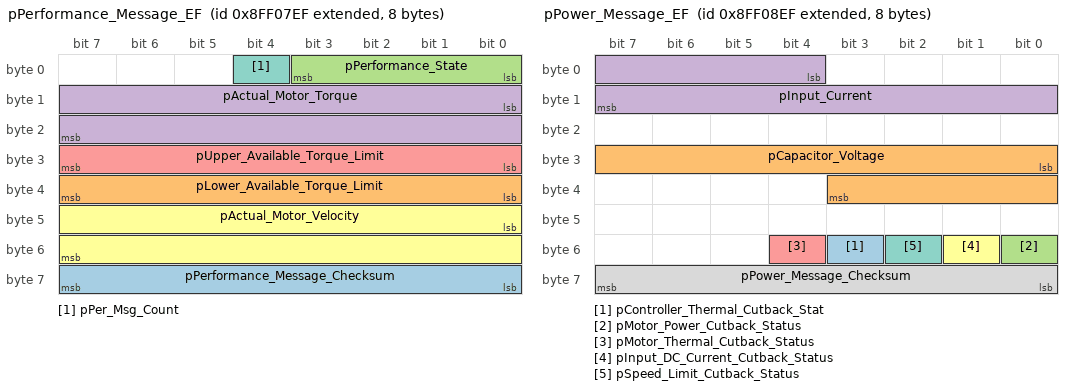
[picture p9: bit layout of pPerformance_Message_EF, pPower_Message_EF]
BO_ 2298415087 pPerformance_Message_EF: 8 EPC1
 SG_ pPerformance_Message_Checksum : 56|8@1+ (1,0) [0|255] "" Vector__XXX
 SG_ pLower_Available_Torque_Limit : 32|8@1+ (2.5,-312.5) [-312.5|951.5] "Nm" Vector__XXX
 SG_ pPerformance_State : 0|4@1+ (1,0) [0|15] "state" Vector__XXX
 SG_ pActual_Motor_Torque : 8|16@1+ (0.1,-3276.8) [-3276.8|9829.4] "Nm" Vector__XXX
 SG_ pUpper_Available_Torque_Limit : 24|8@1+ (2.5,-312.5) [-312.5|951.5] "Nm" Vector__XXX
 SG_ pActual_Motor_Velocity : 40|16@1+ (1,-32768) [-32768|98303] "rpm" Vector__XXX
 SG_ pPer_Msg_Count : 4|1@1+ (1,0) [0|0] "unknown" Vector__XXX

BO_ 2298415343 pPower_Message_EF: 8 EPC1
 SG_ pController_Thermal_Cutback_Stat : 51|1@1+ (1,0) [0|1] "state" Vector__XXX
 SG_ pCapacitor_Voltage : 24|12@1+ (1,0) [0|4095] "V" Vector__XXX
 SG_ pMotor_Power_Cutback_Status : 48|1@1+ (1,0) [0|1] "state" Vector__XXX
 SG_ pInput_Current : 4|12@1+ (1,-2048) [-2048|6143] "A" Vector__XXX
 SG_ pMotor_Thermal_Cutback_Status : 52|1@1+ (1,0) [0|1] "state" Vector__XXX
 SG_ pInput_DC_Current_Cutback_Status : 49|1@1+ (1,0) [0|1] "state" Vector__XXX
 SG_ pSpeed_Limit_Cutback_Status : 50|1@1+ (1,0) [0|1] "state" Vector__XXX
 SG_ pPower_Message_Checksum : 56|8@1+ (1,0) [0|255] "" Vector__XXX

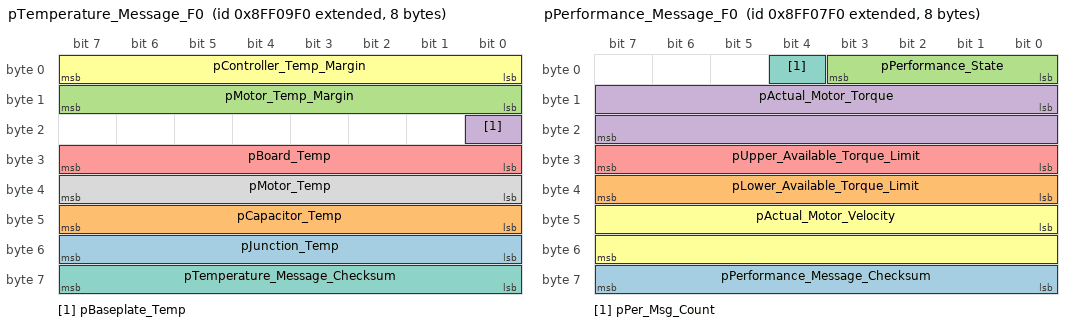
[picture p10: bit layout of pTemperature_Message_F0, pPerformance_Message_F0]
BO_ 2298415600 pTemperature_Message_F0: 8 EPC2
 SG_ pJunction_Temp : 48|8@1+ (1,-40) [-40|295] "deg C" Vector__XXX
 SG_ pCapacitor_Temp : 40|8@1+ (1,-40) [-40|295] "deg C" Vector__XXX
 SG_ pMotor_Temp_Margin : 8|8@1+ (1,0) [0|255] "deg C" Vector__XXX
 SG_ pBaseplate_Temp : 16|1@1+ (1,-40) [-40|40] "deg C" Vector__XXX
 SG_ pBoard_Temp : 24|8@1+ (1,-40) [-40|295] "deg C" Vector__XXX
 SG_ pController_Temp_Margin : 0|8@1+ (1,0) [0|255] "deg C" Vector__XXX
 SG_ pTemperature_Message_Checksum : 56|8@1+ (1,0) [0|255] "" Vector__XXX
 SG_ pMotor_Temp : 32|8@1+ (1,-40) [-40|295] "deg C" Vector__XXX

BO_ 2298415088 pPerformance_Message_F0: 8 EPC2
 SG_ pPerformance_Message_Checksum : 56|8@1+ (1,0) [0|255] "" Vector__XXX
 SG_ pLower_Available_Torque_Limit : 32|8@1+ (2.5,-312.5) [-312.5|951.5] "Nm" Vector__XXX
 SG_ pPerformance_State : 0|4@1+ (1,0) [0|15] "state" Vector__XXX
 SG_ pActual_Motor_Torque : 8|16@1+ (0.1,-3276.8) [-3276.8|9829.4] "Nm" Vector__XXX
 SG_ pUpper_Available_Torque_Limit : 24|8@1+ (2.5,-312.5) [-312.5|951.5] "Nm" Vector__XXX
 SG_ pActual_Motor_Velocity : 40|16@1+ (1,-32768) [-32768|98303] "rpm" Vector__XXX
 SG_ pPer_Msg_Count : 4|1@1+ (1,0) [0|0] "unknown" Vector__XXX

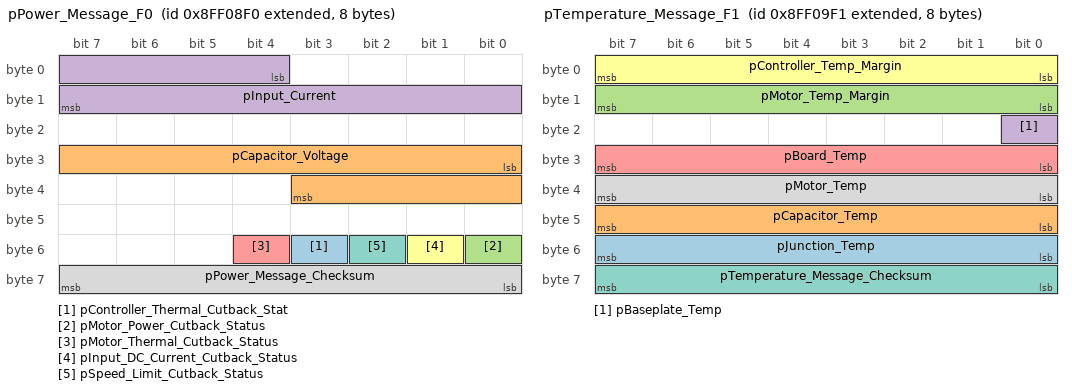
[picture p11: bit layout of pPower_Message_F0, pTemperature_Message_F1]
BO_ 2298415344 pPower_Message_F0: 8 EPC2
 SG_ pController_Thermal_Cutback_Stat : 51|1@1+ (1,0) [0|1] "state" Vector__XXX
 SG_ pCapacitor_Voltage : 24|12@1+ (1,0) [0|4095] "V" Vector__XXX
 SG_ pMotor_Power_Cutback_Status : 48|1@1+ (1,0) [0|1] "state" Vector__XXX
 SG_ pInput_Current : 4|12@1+ (1,-2048) [-2048|6143] "A" Vector__XXX
 SG_ pMotor_Thermal_Cutback_Status : 52|1@1+ (1,0) [0|1] "state" Vector__XXX
 SG_ pInput_DC_Current_Cutback_Status : 49|1@1+ (1,0) [0|1] "state" Vector__XXX
 SG_ pSpeed_Limit_Cutback_Status : 50|1@1+ (1,0) [0|1] "state" Vector__XXX
 SG_ pPower_Message_Checksum : 56|8@1+ (1,0) [0|255] "" Vector__XXX

BO_ 2298415601 pTemperature_Message_F1: 8 EPC3
 SG_ pJunction_Temp : 48|8@1+ (1,-40) [-40|295] "deg C" Vector__XXX
 SG_ pCapacitor_Temp : 40|8@1+ (1,-40) [-40|295] "deg C" Vector__XXX
 SG_ pMotor_Temp_Margin : 8|8@1+ (1,0) [0|255] "deg C" Vector__XXX
 SG_ pBaseplate_Temp : 16|1@1+ (1,-40) [-40|40] "deg C" Vector__XXX
 SG_ pBoard_Temp : 24|8@1+ (1,-40) [-40|295] "deg C" Vector__XXX
 SG_ pController_Temp_Margin : 0|8@1+ (1,0) [0|255] "deg C" Vector__XXX
 SG_ pTemperature_Message_Checksum : 56|8@1+ (1,0) [0|255] "" Vector__XXX
 SG_ pMotor_Temp : 32|8@1+ (1,-40) [-40|295] "deg C" Vector__XXX

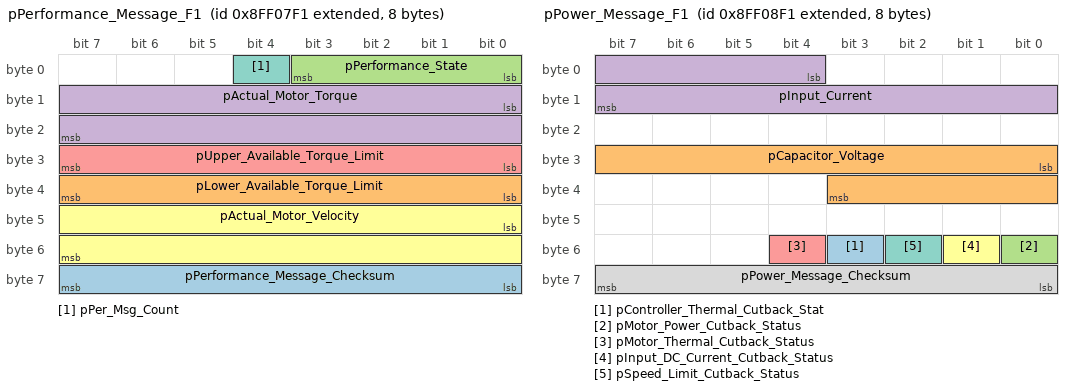
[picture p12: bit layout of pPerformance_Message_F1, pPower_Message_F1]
BO_ 2298415089 pPerformance_Message_F1: 8 EPC3
 SG_ pPerformance_Message_Checksum : 56|8@1+ (1,0) [0|255] "" Vector__XXX
 SG_ pLower_Available_Torque_Limit : 32|8@1+ (2.5,-312.5) [-312.5|951.5] "Nm" Vector__XXX
 SG_ pPerformance_State : 0|4@1+ (1,0) [0|15] "state" Vector__XXX
 SG_ pActual_Motor_Torque : 8|16@1+ (0.1,-3276.8) [-3276.8|9829.4] "Nm" Vector__XXX
 SG_ pUpper_Available_Torque_Limit : 24|8@1+ (2.5,-312.5) [-312.5|951.5] "Nm" Vector__XXX
 SG_ pActual_Motor_Velocity : 40|16@1+ (1,-32768) [-32768|98303] "rpm" Vector__XXX
 SG_ pPer_Msg_Count : 4|1@1+ (1,0) [0|0] "unknown" Vector__XXX

BO_ 2298415345 pPower_Message_F1: 8 EPC3
 SG_ pController_Thermal_Cutback_Stat : 51|1@1+ (1,0) [0|1] "state" Vector__XXX
 SG_ pCapacitor_Voltage : 24|12@1+ (1,0) [0|4095] "V" Vector__XXX
 SG_ pMotor_Power_Cutback_Status : 48|1@1+ (1,0) [0|1] "state" Vector__XXX
 SG_ pInput_Current : 4|12@1+ (1,-2048) [-2048|6143] "A" Vector__XXX
 SG_ pMotor_Thermal_Cutback_Status : 52|1@1+ (1,0) [0|1] "state" Vector__XXX
 SG_ pInput_DC_Current_Cutback_Status : 49|1@1+ (1,0) [0|1] "state" Vector__XXX
 SG_ pSpeed_Limit_Cutback_Status : 50|1@1+ (1,0) [0|1] "state" Vector__XXX
 SG_ pPower_Message_Checksum : 56|8@1+ (1,0) [0|255] "" Vector__XXX

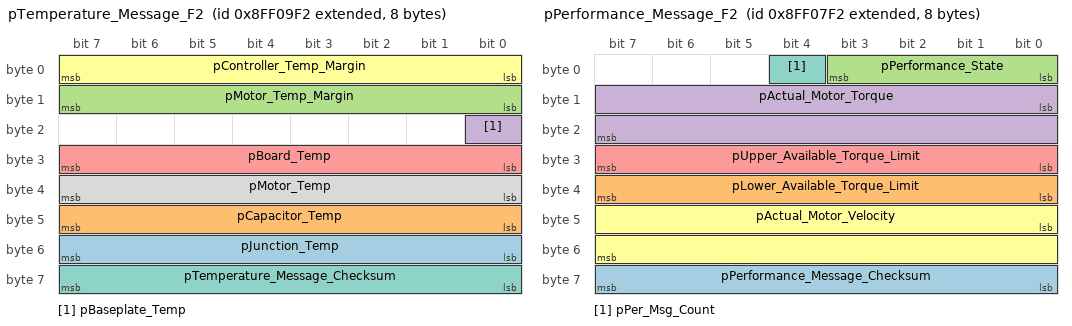
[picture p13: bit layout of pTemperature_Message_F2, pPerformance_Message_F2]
BO_ 2298415602 pTemperature_Message_F2: 8 EPC4
 SG_ pJunction_Temp : 48|8@1+ (1,-40) [-40|295] "deg C" Vector__XXX
 SG_ pCapacitor_Temp : 40|8@1+ (1,-40) [-40|295] "deg C" Vector__XXX
 SG_ pMotor_Temp_Margin : 8|8@1+ (1,0) [0|255] "deg C" Vector__XXX
 SG_ pBaseplate_Temp : 16|1@1+ (1,-40) [-40|40] "deg C" Vector__XXX
 SG_ pBoard_Temp : 24|8@1+ (1,-40) [-40|295] "deg C" Vector__XXX
 SG_ pController_Temp_Margin : 0|8@1+ (1,0) [0|255] "deg C" Vector__XXX
 SG_ pTemperature_Message_Checksum : 56|8@1+ (1,0) [0|255] "" Vector__XXX
 SG_ pMotor_Temp : 32|8@1+ (1,-40) [-40|295] "deg C" Vector__XXX

BO_ 2298415090 pPerformance_Message_F2: 8 EPC4
 SG_ pPerformance_Message_Checksum : 56|8@1+ (1,0) [0|255] "" Vector__XXX
 SG_ pLower_Available_Torque_Limit : 32|8@1+ (2.5,-312.5) [-312.5|951.5] "Nm" Vector__XXX
 SG_ pPerformance_State : 0|4@1+ (1,0) [0|15] "state" Vector__XXX
 SG_ pActual_Motor_Torque : 8|16@1+ (0.1,-3276.8) [-3276.8|9829.4] "Nm" Vector__XXX
 SG_ pUpper_Available_Torque_Limit : 24|8@1+ (2.5,-312.5) [-312.5|951.5] "Nm" Vector__XXX
 SG_ pActual_Motor_Velocity : 40|16@1+ (1,-32768) [-32768|98303] "rpm" Vector__XXX
 SG_ pPer_Msg_Count : 4|1@1+ (1,0) [0|0] "unknown" Vector__XXX

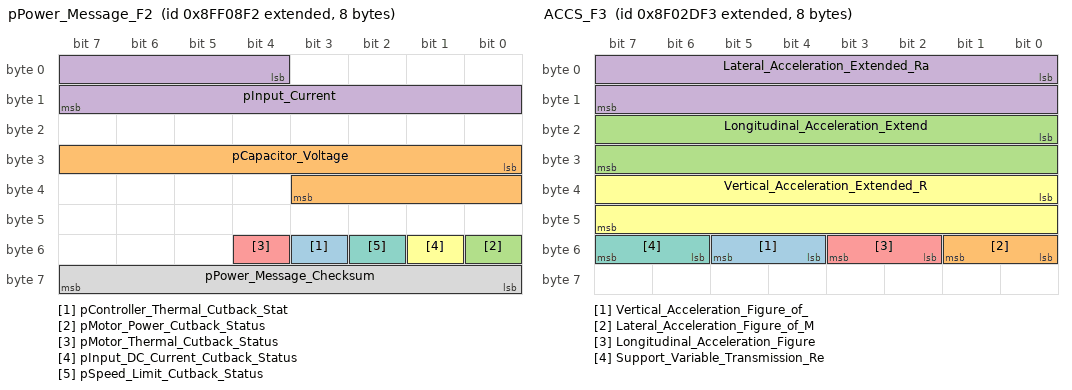
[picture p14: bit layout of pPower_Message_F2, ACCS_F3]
BO_ 2298415346 pPower_Message_F2: 8 EPC4
 SG_ pController_Thermal_Cutback_Stat : 51|1@1+ (1,0) [0|1] "state" Vector__XXX
 SG_ pCapacitor_Voltage : 24|12@1+ (1,0) [0|4095] "V" Vector__XXX
 SG_ pMotor_Power_Cutback_Status : 48|1@1+ (1,0) [0|1] "state" Vector__XXX
 SG_ pInput_Current : 4|12@1+ (1,-2048) [-2048|6143] "A" Vector__XXX
 SG_ pMotor_Thermal_Cutback_Status : 52|1@1+ (1,0) [0|1] "state" Vector__XXX
 SG_ pInput_DC_Current_Cutback_Status : 49|1@1+ (1,0) [0|1] "state" Vector__XXX
 SG_ pSpeed_Limit_Cutback_Status : 50|1@1+ (1,0) [0|1] "state" Vector__XXX
 SG_ pPower_Message_Checksum : 56|8@1+ (1,0) [0|255] "" Vector__XXX

BO_ 2297441779 ACCS_F3: 8 BMC1
 SG_ Vertical_Acceleration_Figure_of_ : 52|2@1+ (1,0) [0|3] "bit" Vector__XXX
 SG_ Lateral_Acceleration_Figure_of_M : 48|2@1+ (1,0) [0|3] "bit" Vector__XXX
 SG_ Longitudinal_Acceleration_Extend : 16|16@1+ (0.01,-320) [-320|974.36] "m/s2" Vector__XXX
 SG_ Lateral_Acceleration_Extended_Ra : 0|16@1+ (0.01,-320) [-320|974.36] "m/s2" Vector__XXX
 SG_ Longitudinal_Acceleration_Figure : 50|2@1+ (1,0) [0|3] "bit" Vector__XXX
 SG_ Vertical_Acceleration_Extended_R : 32|16@1+ (0.01,-320) [-320|974.36] "m/s2" Vector__XXX
 SG_ Support_Variable_Transmission_Re : 54|2@1+ (1,0) [0|3] "bit" Vector__XXX

BO_ 2365525747 pBMC_Power_Message_F3: 8 BMC1
 SG_ pPack_Voltage : 16|16@1+ (0.05,0) [0|3275.8] "V" Vector__XXX
 SG_ pDischarge_Limit : 40|12@1+ (0.5,0) [0|2047] "A" Vector__XXX
 SG_ pPack_Current : 0|16@1+ (0.05,-1600) [-1600|4875.8] "A" Vector__XXX
 SG_ pBMC_Power_Message_Checksum : 56|8@1+ (1,0) [0|255] "" Vector__XXX
 SG_ pCharge_Limit : 44|12@1+ (0.5,0) [0|2047] "A" Vector__XXX

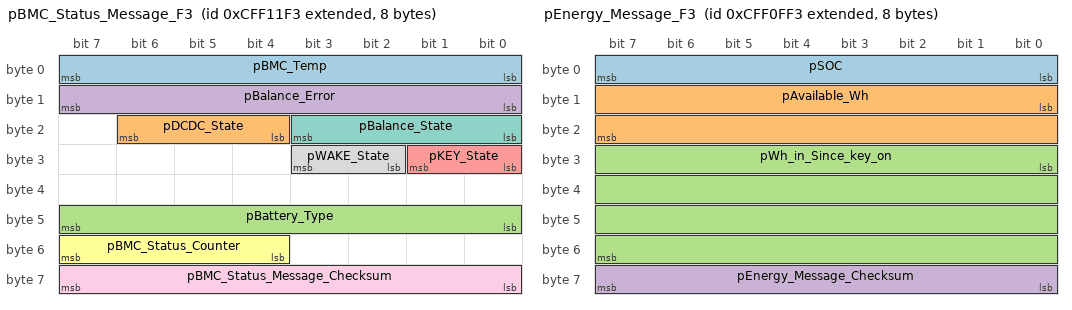
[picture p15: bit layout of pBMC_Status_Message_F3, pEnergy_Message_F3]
BO_ 2365526515 pBMC_Status_Message_F3: 8 BMC1
 SG_ pBMC_Temp : 0|8@1+ (1,-40) [-40|295] "deg C" Vector__XXX
 SG_ pDCDC_State : 20|3@1+ (1,0) [0|7] "state" Vector__XXX
 SG_ pBattery_Type : 40|8@1+ (1,0) [0|255] "state" Vector__XXX
 SG_ pBalance_Error : 8|8@1+ (0.5,-6.4) [-6.4|133.4] "%" Vector__XXX
 SG_ pKEY_State : 24|2@1+ (1,0) [0|3] "state" Vector__XXX
 SG_ pBMC_Status_Counter : 52|4@1+ (1,0) [0|15] "count" Vector__XXX
 SG_ pBalance_State : 16|4@1+ (1,0) [0|15] "state" Vector__XXX
 SG_ pWAKE_State : 26|2@1+ (1,0) [0|3] "state" Vector__XXX
 SG_ pBMC_Status_Message_Checksum : 56|8@1+ (1,0) [0|255] "" Vector__XXX

BO_ 2365526003 pEnergy_Message_F3: 8 BMC1
 SG_ pSOC : 0|8@1+ (0.5,0) [0|127] "%" Vector__XXX
 SG_ pAvailable_Wh : 8|16@1+ (4,0) [0|262143] "kWh" Vector__XXX
 SG_ pWh_in_Since_key_on : 24|32@1+ (1,-131.072) [-131.072|4294967426.072] "Watt-hour" Vector__XXX
 SG_ pEnergy_Message_Checksum : 56|8@1+ (1,0) [0|255] "" Vector__XXX

CM_ BO_ 2566878847 "Name: pDevice Status1
Description: Parsed from -014. ";
CM_ SG_ 2566878847 pDevice_1_Battery_Strength "Description: Used to send the battery strength of a connected device to the infotainment display. This typically will be the driver device. ";
CM_ SG_ 2566878847 pDevice_2_Bluetooth_Connection_S "Description: Used to send the connection status of a connected Bluetooth device. This typically will be the driver device. ";
CM_ SG_ 2566878847 pDevice_2_Device_Battery_Strengt "Description: Used to send the battery strength of a connected device to the infotainment display. This typically will be the driver device. ";
CM_ SG_ 2566878847 pDevice_2_Cell_Signal_Strength "Description: Used to send the cell signal strength of a cell device to the infotainment display. This typically will be the driver device. ";
CM_ SG_ 2566878847 pDevice_Headset_1_Connection_Sta "Description: Used to send the connection status of a connected Bluetooth headset. This typically will be the driver headset. ";
CM_ SG_ 2566878847 pDevice_1_Bluetooth_Connection_S "Description: Used to send the connection status of a connected Bluetooth device. This typically will be the driver device. ";
CM_ SG_ 2566878847 pDevice_1_Cell_Signal_Strength "Description: Used to send the cell signal strength of a cell device to the infotainment display. This typically will be the driver device. ";
CM_ SG_ 2566878847 pDevice_Headset_2_Connection_Sta "Description: Used to send the connection status of a connected Bluetooth headset. This typically will be the driver headset. ";
CM_ BO_ 2566834815 "Name: Active Diagnostic Trouble Codes
Description:DM1 provides diagnostic lamp status and Diagnostic Trouble Codes (DTCs). Together, the lamp and DTC information
convey the diagnostic condition of the transmitting electronic component to other componen";
CM_ SG_ 2566834815 Flash_Malfunction_Indicator_Lamp "Description:This parameter provides the capability to flash the MIL. For OBD systems which are required to flash the SPN for specific malfunctions shall use the “slow flash” rate. 
See J1939-73 for complete reference
Pa";
CM_ SG_ 2566834815 Malfunction_Indicator_Lamp_Statu "Description:Used to relay only emissions-related trouble code information. This lamp is only illuminated when there is an emission-related trouble code active.
See J1939-71 for complete reference

Parsed from -014.";
CM_ SG_ 2566834815 Red_Stop_Lamp_Status "Description:Used to relay trouble code information that is of a severe enough condition that it warrants stopping the vehicle.
See J1939-71 for complete reference

Parsed from -014.";
CM_ SG_ 2566834815 Amber_Warning_Lamp_Status "Description:Used to relay trouble code information that is reporting a problem with the vehicle system but the vehicle need not be immediately stopped.
See J1939-71 for complete reference

Parsed from -014.";
CM_ SG_ 2566834815 Flash_Red_Stop_Lamp_RSL "Description:This parameter provides the capability to flash the RSL.
See J1939-73 for complete reference
Parsed from -014.";
CM_ SG_ 2566834815 Flash_Amber_Warning_Lamp_AWL "Description:This parameter provides the capability to flash the AWL. 
See J1939-73 for complete reference
Parsed from -014.";
CM_ SG_ 2566834815 Flash_Protect_Lamp "Description:This parameter provides the capability to flash the protect lamp. 
See J1939-73 for complete reference
Parsed from -014.";
CM_ SG_ 2566834815 Protect_Lamp_Status "Description:Used to relay trouble code information that is reporting a problem with a vehicle system that is most probably not electronic subsystem related. For instance, engine coolant temperature is exceeding its prescribed temperat";
CM_ SG_ 2566834815 DTC_1 "Description:This signal is a combination of 4 SPNs. To decode this signal, navigate to MCS tools.
Byte: 1 bits 8-1 SPN, 8 least significant bits of SPN (most significant at bit 8, SPN 1214)
Byte: 2 bits 8-1 SPN, second byte of SPN (most significa";
CM_ SG_ 2566834815 DTC_2 "Description:This signal is a combination of 4 SPNs. To decode this signal, navigate to MCS tools.
Byte: 1 bits 8-1 SPN, 8 least significant bits of SPN (most significant at bit 8, SPN 1214)
Byte: 2 bits 8-1 SPN, second byte of SPN (most significa";
CM_ SG_ 2566834815 DTC_3 "Description:This signal is a combination of 4 SPNs. To decode this signal, navigate to MCS tools.
Byte: 1 bits 8-1 SPN, 8 least significant bits of SPN (most significant at bit 8, SPN 1214)
Byte: 2 bits 8-1 SPN, second byte of SPN (most significa";
CM_ SG_ 2566834815 DTC_4 "Description:This signal is a combination of 4 SPNs. To decode this signal, navigate to MCS tools.
Byte: 1 bits 8-1 SPN, 8 least significant bits of SPN (most significant at bit 8, SPN 1214)
Byte: 2 bits 8-1 SPN, second byte of SPN (most significa";
CM_ SG_ 2566834815 DTC_5 "Description:This signal is a combination of 4 SPNs. To decode this signal, navigate to MCS tools.
Byte: 1 bits 8-1 SPN, 8 least significant bits of SPN (most significant at bit 8, SPN 1214)
Byte: 2 bits 8-1 SPN, second byte of SPN (most significa";
CM_ SG_ 2566834815 DTC_6 "Description:This signal is a combination of 4 SPNs. To decode this signal, navigate to MCS tools.
Byte: 1 bits 8-1 SPN, 8 least significant bits of SPN (most significant at bit 8, SPN 1214)
Byte: 2 bits 8-1 SPN, second byte of SPN (most significa";
CM_ SG_ 2566834815 DTC_7 "Description:This signal is a combination of 4 SPNs. To decode this signal, navigate to MCS tools.
Byte: 1 bits 8-1 SPN, 8 least significant bits of SPN (most significant at bit 8, SPN 1214)
Byte: 2 bits 8-1 SPN, second byte of SPN (most significa";
CM_ SG_ 2566834815 DTC_8 "Description:This signal is a combination of 4 SPNs. To decode this signal, navigate to MCS tools.
Byte: 1 bits 8-1 SPN, 8 least significant bits of SPN (most significant at bit 8, SPN 1214)
Byte: 2 bits 8-1 SPN, second byte of SPN (most significa";
CM_ SG_ 2566834815 DTC_9 "Description:This signal is a combination of 4 SPNs. To decode this signal, navigate to MCS tools.
Byte: 1 bits 8-1 SPN, 8 least significant bits of SPN (most significant at bit 8, SPN 1214)
Byte: 2 bits 8-1 SPN, second byte of SPN (most significa";
CM_ SG_ 2566834815 DTC_10 "Description:This signal is a combination of 4 SPNs. To decode this signal, navigate to MCS tools.
Byte: 1 bits 8-1 SPN, 8 least significant bits of SPN (most significant at bit 8, SPN 1214)
Byte: 2 bits 8-1 SPN, second byte of SPN (most signific";
CM_ BO_ 2566842495 "Name: Vehicle Direction/Speed
Description: Parsed from -014. ";
CM_ SG_ 2566842495 Compass_Bearing "Description:Present compass bearing of vehicle.
Note: Parsed from J1939DA.";
CM_ BO_ 2561212287 "Name: Text Display
Description: Could not parse data length. Please add to field:Data Length: Variable � up to 200 characters
Parsed from -014. ";
CM_ SG_ 2561212287 Text_Display_Character "Description:From 1 up to 200 characters to be presented on a display. Up to 4 characters can be displayed without using Transport Protocol. The Display Text characters will follow the standard J1939-71 display method. Control chara";
CM_ SG_ 2561212287 Text_Display_Index "Description:Used for overwriting consecutive bytes of a displayed string when byte 1 Text Display Instructions state is set for overwrite substring mode. When used, this byte declares where in the text string that the new text will sta";
CM_ SG_ 2561212287 Text_Display_Instructions "Description:This parameter describes the status for the display how to show the information. 0000b = Clear display - The displayed information should be deleted or not displayed any more. 0001b = Hold display - The presently dis";
CM_ BO_ 2365531268 "Name: pVehModCmd
Description:Vehicle Mode Command";
CM_ SG_ 2365531268 pEPSReqMod "Description: Used to set the EPAS assist mode. ";
CM_ BO_ 2365554944 "Name: pOperator Switch Status 3
Description: Parsed from -014. ";
CM_ SG_ 2365554944 pOperator_Switch_Status_3 "Description: Broadcasting the status of the operator switch. ";
CM_ SG_ 2365554944 pUpPaddleStatus "Description: Used to broadcast status of RHC steering wheel shift paddle for Up shifting. ";
CM_ SG_ 2365554944 pOperator_Switch_Status_2 "Description: Broadcasting the status of the operator switch.  ";
CM_ SG_ 2365554944 pDwPaddleStatus "Description: Used to broadcast status of LHC steering wheel shift paddle for Down shifting. ";
CM_ SG_ 2365554944 pOperator_Button_50_Pucker "Description: Broadcasting the status of the operator switch.  ";
CM_ BO_ 2566834823 "Name: Active Diagnostic Trouble Codes
Description:DM1 provides diagnostic lamp status and Diagnostic Trouble Codes (DTCs). Together, the lamp and DTC information
convey the diagnostic condition of the transmitting electronic component to other componen";
CM_ SG_ 2566834823 Flash_Malfunction_Indicator_Lamp "Description:This parameter provides the capability to flash the MIL. For OBD systems which are required to flash the SPN for specific malfunctions shall use the “slow flash” rate. 
See J1939-73 for complete reference
Pa";
CM_ SG_ 2566834823 Malfunction_Indicator_Lamp_Statu "Description:Used to relay only emissions-related trouble code information. This lamp is only illuminated when there is an emission-related trouble code active.
See J1939-71 for complete reference

Parsed from -014.";
CM_ SG_ 2566834823 Red_Stop_Lamp_Status "Description:Used to relay trouble code information that is of a severe enough condition that it warrants stopping the vehicle.
See J1939-71 for complete reference

Parsed from -014.";
CM_ SG_ 2566834823 Amber_Warning_Lamp_Status "Description:Used to relay trouble code information that is reporting a problem with the vehicle system but the vehicle need not be immediately stopped.
See J1939-71 for complete reference

Parsed from -014.";
CM_ SG_ 2566834823 Flash_Red_Stop_Lamp_RSL "Description:This parameter provides the capability to flash the RSL.
See J1939-73 for complete reference
Parsed from -014.";
CM_ SG_ 2566834823 Flash_Amber_Warning_Lamp_AWL "Description:This parameter provides the capability to flash the AWL. 
See J1939-73 for complete reference
Parsed from -014.";
CM_ SG_ 2566834823 Flash_Protect_Lamp "Description:This parameter provides the capability to flash the protect lamp. 
See J1939-73 for complete reference
Parsed from -014.";
CM_ SG_ 2566834823 Protect_Lamp_Status "Description:Used to relay trouble code information that is reporting a problem with a vehicle system that is most probably not electronic subsystem related. For instance, engine coolant temperature is exceeding its prescribed temperat";
CM_ SG_ 2566834823 DTC_1 "Description:This signal is a combination of 4 SPNs. To decode this signal, navigate to MCS tools.
Byte: 1 bits 8-1 SPN, 8 least significant bits of SPN (most significant at bit 8, SPN 1214)
Byte: 2 bits 8-1 SPN, second byte of SPN (most significa";
CM_ SG_ 2566834823 DTC_2 "Description:This signal is a combination of 4 SPNs. To decode this signal, navigate to MCS tools.
Byte: 1 bits 8-1 SPN, 8 least significant bits of SPN (most significant at bit 8, SPN 1214)
Byte: 2 bits 8-1 SPN, second byte of SPN (most significa";
CM_ SG_ 2566834823 DTC_3 "Description:This signal is a combination of 4 SPNs. To decode this signal, navigate to MCS tools.
Byte: 1 bits 8-1 SPN, 8 least significant bits of SPN (most significant at bit 8, SPN 1214)
Byte: 2 bits 8-1 SPN, second byte of SPN (most significa";
CM_ SG_ 2566834823 DTC_4 "Description:This signal is a combination of 4 SPNs. To decode this signal, navigate to MCS tools.
Byte: 1 bits 8-1 SPN, 8 least significant bits of SPN (most significant at bit 8, SPN 1214)
Byte: 2 bits 8-1 SPN, second byte of SPN (most significa";
CM_ SG_ 2566834823 DTC_5 "Description:This signal is a combination of 4 SPNs. To decode this signal, navigate to MCS tools.
Byte: 1 bits 8-1 SPN, 8 least significant bits of SPN (most significant at bit 8, SPN 1214)
Byte: 2 bits 8-1 SPN, second byte of SPN (most significa";
CM_ SG_ 2566834823 DTC_6 "Description:This signal is a combination of 4 SPNs. To decode this signal, navigate to MCS tools.
Byte: 1 bits 8-1 SPN, 8 least significant bits of SPN (most significant at bit 8, SPN 1214)
Byte: 2 bits 8-1 SPN, second byte of SPN (most significa";
CM_ SG_ 2566834823 DTC_7 "Description:This signal is a combination of 4 SPNs. To decode this signal, navigate to MCS tools.
Byte: 1 bits 8-1 SPN, 8 least significant bits of SPN (most significant at bit 8, SPN 1214)
Byte: 2 bits 8-1 SPN, second byte of SPN (most significa";
CM_ SG_ 2566834823 DTC_8 "Description:This signal is a combination of 4 SPNs. To decode this signal, navigate to MCS tools.
Byte: 1 bits 8-1 SPN, 8 least significant bits of SPN (most significant at bit 8, SPN 1214)
Byte: 2 bits 8-1 SPN, second byte of SPN (most significa";
CM_ SG_ 2566834823 DTC_9 "Description:This signal is a combination of 4 SPNs. To decode this signal, navigate to MCS tools.
Byte: 1 bits 8-1 SPN, 8 least significant bits of SPN (most significant at bit 8, SPN 1214)
Byte: 2 bits 8-1 SPN, second byte of SPN (most significa";
CM_ SG_ 2566834823 DTC_10 "Description:This signal is a combination of 4 SPNs. To decode this signal, navigate to MCS tools.
Byte: 1 bits 8-1 SPN, 8 least significant bits of SPN (most significant at bit 8, SPN 1214)
Byte: 2 bits 8-1 SPN, second byte of SPN (most signific";
CM_ BO_ 2432656519 "Name: pInfotainment System Control
Description: Parsed from -014. ";
CM_ SG_ 2432656519 Source "Description: This group of SPN&rsquo;s contain the information for the Infotainment System Control. See PGN 65380 breakdown for definition of each button. ";
CM_ SG_ 2432656519 Squelch_SQ_Up "Description: This group of SPN&rsquo;s contain the information for the Infotainment System Control. See PGN 65380 breakdown for definition of each button. ";
CM_ SG_ 2432656519 MutePreset "Description: This group of SPN&rsquo;s contain the information for the Infotainment System Control. See PGN 65380 breakdown for definition of each button. ";
CM_ SG_ 2432656519 Volume_Down "Description: This group of SPN&rsquo;s contain the information for the Infotainment System Control. See PGN 65380 breakdown for definition of each button. ";
CM_ SG_ 2432656519 Volume_Up "Description: This group of SPN&rsquo;s contain the information for the Infotainment System Control. See PGN 65380 breakdown for definition of each button. ";
CM_ SG_ 2432656519 Tune_Up "Description: This group of SPN&rsquo;s contain the information for the Infotainment System Control. See PGN 65380 breakdown for definition of each button. ";
CM_ SG_ 2432656519 Seek_Up "Description: This group of SPN&rsquo;s contain the information for the Infotainment System Control. See PGN 65380 breakdown for definition of each button. ";
CM_ SG_ 2432656519 Tune_Down "Description: This group of SPN&rsquo;s contain the information for the Infotainment System Control. See PGN 65380 breakdown for definition of each button. ";
CM_ SG_ 2432656519 Squelch_SQ_Down "Description: This group of SPN&rsquo;s contain the information for the Infotainment System Control. See PGN 65380 breakdown for definition of each button. ";
CM_ SG_ 2432656519 pInfotainment_Joystick_1 "Description: Switch signal indicating status of infotainment joystick 1 buttons. ";
CM_ SG_ 2432656519 Preset "Description: This group of SPN&rsquo;s contain the information for the Infotainment System Control. See PGN 65380 breakdown for definition of each button. ";
CM_ SG_ 2432656519 Seek_Down "Description: This group of SPN&rsquo;s contain the information for the Infotainment System Control. See PGN 65380 breakdown for definition of each button. ";
CM_ SG_ 2432656519 pInfotainment_Joystick_2 "Description: Switch signal indicating status of infotainment joystick 2 buttons. ";
CM_ SG_ 2432656519 ICOM "Description: This group of SPN&rsquo;s contain the information for the Infotainment System Control. See PGN 65380 breakdown for definition of each button. ";
CM_ SG_ 2432656519 Push_To_Talk_PTT "Description: This group of SPN&rsquo;s contain the information for the Infotainment System Control. See PGN 65380 breakdown for definition of each button. ";
CM_ SG_ 2432656519 pMultifunction_Infotainment_Inte "Description: Switch status indicating the state of the multi-function infotainment button.

 ";
CM_ SG_ 2432656519 COM "Description: This group of SPN&rsquo;s contain the information for the Infotainment System Control. See PGN 65380 breakdown for definition of each button. ";
CM_ SG_ 2432656519 PlayPause "Description: This group of SPN&rsquo;s contain the information for the Infotainment System Control. See PGN 65380 breakdown for definition of each button. ";
CM_ BO_ 2566860167 "Name: pInstrument Special Message
Description: Used to command special messages for the specific LCD Display using 2 bit status SPN�s only. The intention is to command specific warnings to the user when the vehicle is in specific states determined by th";
CM_ SG_ 2566860167 pSpecial_Msg_12 "Description: SPN Grouping contain Special Instruction Messages for LCD Display. See breakdown of PGN 65325 for further definition. ";
CM_ SG_ 2566860167 pSpecial_Msg_28 "Description: SPN Grouping contain Special Instruction Messages for LCD Display. See breakdown of PGN 65325 for further definition. ";
CM_ SG_ 2566860167 pSpecial_Msg_11 "Description: SPN Grouping contain Special Instruction Messages for LCD Display. See breakdown of PGN 65325 for further definition. ";
CM_ SG_ 2566860167 pSpecial_Msg_26 "Description: SPN Grouping contain Special Instruction Messages for LCD Display. See breakdown of PGN 65325 for further definition. ";
CM_ SG_ 2566860167 pSpecial_Msg_24 "Description: SPN Grouping contain Special Instruction Messages for LCD Display. See breakdown of PGN 65325 for further definition. ";
CM_ SG_ 2566860167 pSpecial_Msg_21 "Description: SPN Grouping contain Special Instruction Messages for LCD Display. See breakdown of PGN 65325 for further definition. ";
CM_ SG_ 2566860167 pSpecial_Msg_18 "Description: SPN Grouping contain Special Instruction Messages for LCD Display. See breakdown of PGN 65325 for further definition. ";
CM_ SG_ 2566860167 pSpecial_Msg_19 "Description: SPN Grouping contain Special Instruction Messages for LCD Display. See breakdown of PGN 65325 for further definition. ";
CM_ SG_ 2566860167 pSpecial_Msg_1_Riding_with_Brake "Description: SPN Grouping contain Special Instruction Messages for LCD Display. See breakdown of PGN 65325 for further definition. ";
CM_ SG_ 2566860167 pSpecial_Msg_2_Regulator_Overhea "Description: SPN Grouping contain Special Instruction Messages for LCD Display. See breakdown of PGN 65325 for further definition. ";
CM_ SG_ 2566860167 pSpecial_Msg_3_Regulator_Overhea "Description: SPN Grouping contain Special Instruction Messages for LCD Display. See breakdown of PGN 65325 for further definition. ";
CM_ SG_ 2566860167 pSpecial_Msg_4_Regulator_Overhea "Description: SPN Grouping contain Special Instruction Messages for LCD Display. See breakdown of PGN 65325 for further definition. ";
CM_ SG_ 2566860167 pSpecial_Msg_5_Engine_Warmup_Com "Description: SPN Grouping contain Special Instruction Messages for LCD Display. See breakdown of PGN 65325 for further definition. ";
CM_ SG_ 2566860167 pSpecial_Msg_6_Engine_Knock__Mod "Description: SPN Grouping contain Special Instruction Messages for LCD Display. See breakdown of PGN 65325 for further definition. ";
CM_ SG_ 2566860167 pSpecial_Msg_8_Low_Coolant_Warni "Description: SPN Grouping contain Special Instruction Messages for LCD Display. See breakdown of PGN 65325 for further definition. ";
CM_ SG_ 2566860167 pSpecial_Msg_7_Engine_Knock__Mos "Description: SPN Grouping contain Special Instruction Messages for LCD Display. See breakdown of PGN 65325 for further definition. ";
CM_ SG_ 2566860167 pSpecial_Msg_9_Transmission_Temp "Description: SPN Grouping contain Special Instruction Messages for LCD Display. See breakdown of PGN 65325 for further definition. ";
CM_ SG_ 2566860167 pSpecial_Msg_10_Reverse_Speed_Li "Description: SPN Grouping contain Special Instruction Messages for LCD Display. See breakdown of PGN 65325 for further definition. ";
CM_ SG_ 2566860167 pSpecial_Msg_13_Belt_Burn_Warnin "Description: SPN Grouping contain Special Instruction Messages for LCD Display. See breakdown of PGN 65325 for further definition. ";
CM_ SG_ 2566860167 pSpecial_Msg_14_Park_Brake_Warni "Description: SPN Grouping contain Special Instruction Messages for LCD Display. See breakdown of PGN 65325 for further definition. ";
CM_ SG_ 2566860167 pSpecial_Msg_15_TCM_Comm_Loss "Description: SPN Grouping contain Special Instruction Messages for LCD Display. See breakdown of PGN 65325 for further definition. ";
CM_ SG_ 2566860167 pSpecial_Msg_16_TCM_Pump_Priming "Description: SPN Grouping contain Special Instruction Messages for LCD Display. See breakdown of PGN 65325 for further definition. ";
CM_ SG_ 2566860167 pSpecial_Msg_17_Request_User_to_ "Description: SPN Grouping contain Special Instruction Messages for LCD Display. See breakdown of PGN 65325 for further definition. ";
CM_ SG_ 2566860167 pSpecial_MSG_20_Fuel_Door_Open_E "Description: SPN Grouping contain Special Instruction Messages for LCD Display. See breakdown of PGN 65325 for further definition. ";
CM_ SG_ 2566860167 pSpecial_MSG_22_Clutch_Overtemp "Description: SPN Grouping contain Special Instruction Messages for LCD Display. See breakdown of PGN 65325 for further definition. ";
CM_ SG_ 2566860167 pSpecial_MSG_23_Exhaust_Valve_Ch "Description: SPN Grouping contain Special Instruction Messages for LCD Display. See breakdown of PGN 65325 for further definition. ";
CM_ SG_ 2566860167 pSpecial_MSG_25_Engine_Idle_Shut "Description: SPN Grouping contain Special Instruction Messages for LCD Display. See breakdown of PGN 65325 for further definition. ";
CM_ SG_ 2566860167 pSpecial_MSG_27_Overboost_Condit "Description: SPN Grouping contain Special Instruction Messages for LCD Display. See breakdown of PGN 65325 for further definition. ";
CM_ SG_ 2566860167 pSpecial_Msg_31_Engine_Tip_Over_ "Description: Engine Tip Over Lockout Special Message designed to indicate to the instrument cluster that an engine tip over condition is present and that the engine is currently preventing the user from starting the engin";
CM_ SG_ 2566860167 pSpecial_Msg_32_Engine_Tip_Over_ "Description: Engine Tip Over Lockout - Heal State Special Message designed to communicate to the instrument cluster that the vehicle is still currently in a engine tip over condition but is in the process of it being heal";
CM_ BO_ 2365555079 "Name: pOperator Switch Status 3
Description: Parsed from -014. ";
CM_ SG_ 2365555079 pOperator_Switch_Status_3 "Description: Broadcasting the status of the operator switch. ";
CM_ SG_ 2365555079 pUpPaddleStatus "Description: Used to broadcast status of RHC steering wheel shift paddle for Up shifting. ";
CM_ SG_ 2365555079 pOperator_Switch_Status_2 "Description: Broadcasting the status of the operator switch.  ";
CM_ SG_ 2365555079 pDwPaddleStatus "Description: Used to broadcast status of LHC steering wheel shift paddle for Down shifting. ";
CM_ SG_ 2365555079 pOperator_Button_50_Pucker "Description: Broadcasting the status of the operator switch.  ";
CM_ BO_ 2566896007 "Name: pAccessory Control Heated Grips 1
Description: Parsed from -014. ";
CM_ SG_ 2566896007 pSetpoint_Grips_Hand_Medium "Description: Medium temperature setpoint of thermistor in the hand grips.
Could not parse SPN data type, please add:Type: Measured
Parsed from -014. ";
CM_ SG_ 2566896007 pSetpoint_Grips_Hand_Low "Description: Low temperature setpoint of thermistor in the hand grips.
Could not parse SPN data type, please add:Type: Measured
Parsed from -014. ";
CM_ SG_ 2566896007 pSetpoint_Grip_Thumb_Medium "Description: Medium temperature setpoint of thermistor in the thumb grip.
Could not parse SPN data type, please add:Type: Measured
Parsed from -014. ";
CM_ SG_ 2566896007 pAccessory_Control_Operation "Description: Intended to identify the accessory control operation under discussion ";
CM_ SG_ 2566896007 pSetpoint_Grips_Hand_High "Description: High temperature setpoint of thermistor in the hand grips.
Could not parse SPN data type, please add:Type: Measured
Parsed from -014. ";
CM_ SG_ 2566896007 pAccessory_Control_Mode "Description: Intended to identify the accessory control mode under discussion ";
CM_ SG_ 2566896007 pSetpoint_Grip_Thumb_High "Description: High temperature setpoint of thermistor in the thumb grip.
Could not parse SPN data type, please add:Type: Measured
Parsed from -014. ";
CM_ SG_ 2566896007 pSetpoint_Grip_Thumb_Low "Description: Low temperature setpoint of thermistor in the thumb grip.
Could not parse SPN data type, please add:Type: Measured
Parsed from -014. ";
CM_ BO_ 2566844807 "Name: Cruise Control Vehicle Speed 1
Description: Parsed from -014. ";
CM_ SG_ 2566844807 Cruise_Control_Set_Speed "Description:Value of set (chosen) velocity of velocity control system. See SPN 6809 for an alternate resolution. If an algorithm that can modify the cruise control set point exists in the system, such as Predictive Cruise Control";
CM_ SG_ 2566844807 Cruise_Control_Active "Description:Cruise control is switched on. It is not ensured that the engine is controlled by cruise control, as in the case of a large driver's demand the engine is controlled by the driver while cruise control is active (maximum s";
CM_ SG_ 2566844807 Clutch_Switch "Description:Switch signal which indicates that the clutch pedal is being pressed. It is necessary for a safe drivetrain behavior that the clutch switch is set before the clutch is opened (cruise control function). 00b = Clutch pedal release";
CM_ SG_ 2566844807 Brake_Switch "Description:Switch signal which indicates that the driver operated brake foot pedal is being pressed. This brake foot pedal is controlling the vehicles' service brake (total vehicle braking application, not park brakes). It is necessary for ";
CM_ SG_ 2566844807 pCC_Message_Counter "Description: Rolling Counter (ensures updated message is used).
Could not parse SPN data type, please add:Type: Status
Parsed from -014. ";
CM_ SG_ 2566844807 Cruise_Control_Pause_Switch "Description:Switch signal which indicates the position of the Cruise Control Pause Switch used on Remote Cruise Control applications. The Cruise Control Pause Switch signal temporarily disables the Cruise Control function. 00b";
CM_ SG_ 2566844807 Cruise_Control_Set_Switch "Description:Switch signal of the cruise control activator which indicates that the activator is in the position set. 00b = Cruise control activator not in the position set 01b = Cruise control activator in position set 10b = Err";
CM_ SG_ 2566844807 Two_Speed_Axle_Switch "Description:Switch signal which indicates the current axle range. 00b = Low speed range 01b = High speed range 10b = Error 11b = Not available
Note: Parsed from J1939DA.";
CM_ SG_ 2566844807 Cruise_Control_Enable_Switch "Description:Switch signal which indicates that it is possible to manage the cruise control function. 00b = Cruise control disabled 01b = Cruise control enabled 10b = Error 11b = Not available
Note: Parsed from J1939DA.";
CM_ SG_ 2566844807 pOdometer_Drive_Bit "Description: Each State A->B or B->A change indicates the vehicle has moved 40 m since the previous one. However, since the message is sent at regular 100 ms intervals, State A and B each occur multiple times consecutively (a minimum ";
CM_ SG_ 2566844807 pCC_Checksum "Description: XOR of bytes 0-6 (ensures data is valid before use). 
Could not parse SPN data type, please add:Type: Status
Parsed from -014. ";
CM_ SG_ 2566844807 WheelBased_Vehicle_Speed "Description:Speed of the vehicle as calculated from wheel or tailshaft speed.
Note: Parsed from J1939DA.";
CM_ SG_ 2566844807 Cruise_Control_Resume_Switch "Description:Switch signal of the cruise control activator which indicates that the activator is in the position resume. 00b = Cruise control activator not in the position resume 01b = Cruise control activator in position resu";
CM_ SG_ 2566844807 Cruise_Control_Accelerate_Switch "Description:Switch signal of the cruise control activator which indicates that the activator is in the position accelerate. 00b = Cruise control activator not in the position accelerate 01b = Cruise control activator in p";
CM_ SG_ 2566844807 pCruise_Enable_Status "Description: The Cruise Control System has been enabled by the operator. (Amber Light) ";
CM_ SG_ 2566844807 Parking_Brake_Switch "Description:Switch signal which indicates when the parking brake is set. In general the switch actuated by the operator's park brake control, whether a pedal, lever or other control mechanism (see also SPN 619 and 5275). 00b = Parkin";
CM_ SG_ 2566844807 Cruise_Control_Coast_Decelerate_ "Description:Switch signal of the cruise control activator which indicates that the activator is in the position coast (decelerate). 00b = Cruise control activator not in the position coast 01b = Cruise control activator i";
CM_ BO_ 2566835079 "Name: Previously Active Diagnostic Trouble Codes
Description:When supported, DM2 provides a list of all previously active (previously detected) DTCs. The list of DTCs must include
all the emissions-related previously active DTCs provided in the device’";
CM_ SG_ 2566835079 Protect_Lamp_Status "Description:Used to relay trouble code information that is reporting a problem with a vehicle system that is most probably not electronic subsystem related. For instance, engine coolant temperature is exceeding its prescribed temperat";
CM_ SG_ 2566835079 Amber_Warning_Lamp_Status "Description:Used to relay trouble code information that is reporting a problem with the vehicle system but the vehicle need not be immediately stopped.
See J1939-71 for complete reference

Parsed from -014.";
CM_ SG_ 2566835079 Red_Stop_Lamp_Status "Description:Used to relay trouble code information that is of a severe enough condition that it warrants stopping the vehicle.
See J1939-71 for complete reference

Parsed from -014.";
CM_ SG_ 2566835079 Malfunction_Indicator_Lamp_Statu "Description:Used to relay only emissions-related trouble code information. This lamp is only illuminated when there is an emission-related trouble code active.
See J1939-71 for complete reference

Parsed from -014.";
CM_ SG_ 2566835079 Flash_Protect_Lamp "Description:This parameter provides the capability to flash the protect lamp. 
See J1939-73 for complete reference
Parsed from -014.";
CM_ SG_ 2566835079 Flash_Amber_Warning_Lamp_AWL "Description:This parameter provides the capability to flash the AWL. 
See J1939-73 for complete reference
Parsed from -014.";
CM_ SG_ 2566835079 Flash_Red_Stop_Lamp_RSL "Description:This parameter provides the capability to flash the RSL.
See J1939-73 for complete reference
Parsed from -014.";
CM_ SG_ 2566835079 Flash_Malfunction_Indicator_Lamp "Description:This parameter provides the capability to flash the MIL. For OBD systems which are required to flash the SPN for specific malfunctions shall use the “slow flash” rate. 
See J1939-73 for complete reference
Pa";
CM_ SG_ 2566835079 DTC_1 "Description:This signal is a combination of 4 SPNs. To decode this signal, navigate to MCS tools.
Byte: 1 bits 8-1 SPN, 8 least significant bits of SPN (most significant at bit 8, SPN 1214)
Byte: 2 bits 8-1 SPN, second byte of SPN (most significa";
CM_ SG_ 2566835079 DTC_2 "Description:This signal is a combination of 4 SPNs. To decode this signal, navigate to MCS tools.
Byte: 1 bits 8-1 SPN, 8 least significant bits of SPN (most significant at bit 8, SPN 1214)
Byte: 2 bits 8-1 SPN, second byte of SPN (most significa";
CM_ SG_ 2566835079 DTC_3 "Description:This signal is a combination of 4 SPNs. To decode this signal, navigate to MCS tools.
Byte: 1 bits 8-1 SPN, 8 least significant bits of SPN (most significant at bit 8, SPN 1214)
Byte: 2 bits 8-1 SPN, second byte of SPN (most significa";
CM_ SG_ 2566835079 DTC_4 "Description:This signal is a combination of 4 SPNs. To decode this signal, navigate to MCS tools.
Byte: 1 bits 8-1 SPN, 8 least significant bits of SPN (most significant at bit 8, SPN 1214)
Byte: 2 bits 8-1 SPN, second byte of SPN (most significa";
CM_ SG_ 2566835079 DTC_5 "Description:This signal is a combination of 4 SPNs. To decode this signal, navigate to MCS tools.
Byte: 1 bits 8-1 SPN, 8 least significant bits of SPN (most significant at bit 8, SPN 1214)
Byte: 2 bits 8-1 SPN, second byte of SPN (most significa";
CM_ SG_ 2566835079 DTC_6 "Description:This signal is a combination of 4 SPNs. To decode this signal, navigate to MCS tools.
Byte: 1 bits 8-1 SPN, 8 least significant bits of SPN (most significant at bit 8, SPN 1214)
Byte: 2 bits 8-1 SPN, second byte of SPN (most significa";
CM_ SG_ 2566835079 DTC_7 "Description:This signal is a combination of 4 SPNs. To decode this signal, navigate to MCS tools.
Byte: 1 bits 8-1 SPN, 8 least significant bits of SPN (most significant at bit 8, SPN 1214)
Byte: 2 bits 8-1 SPN, second byte of SPN (most significa";
CM_ SG_ 2566835079 DTC_8 "Description:This signal is a combination of 4 SPNs. To decode this signal, navigate to MCS tools.
Byte: 1 bits 8-1 SPN, 8 least significant bits of SPN (most significant at bit 8, SPN 1214)
Byte: 2 bits 8-1 SPN, second byte of SPN (most significa";
CM_ SG_ 2566835079 DTC_9 "Description:This signal is a combination of 4 SPNs. To decode this signal, navigate to MCS tools.
Byte: 1 bits 8-1 SPN, 8 least significant bits of SPN (most significant at bit 8, SPN 1214)
Byte: 2 bits 8-1 SPN, second byte of SPN (most significa";
CM_ SG_ 2566835079 DTC_10 "Description:This signal is a combination of 4 SPNs. To decode this signal, navigate to MCS tools.
Byte: 1 bits 8-1 SPN, 8 least significant bits of SPN (most significant at bit 8, SPN 1214)
Byte: 2 bits 8-1 SPN, second byte of SPN (most signific";
CM_ BO_ 2432656775 "Name: pOperator Switch Status
Description: Parsed from -014. ";
CM_ SG_ 2432656775 Key_Fob_Unlock_Button_Status "Description: These group of SPN&rsquo;s contain the information for the Operator Switches. See PGN 65380 breakdown for definition of each button. ";
CM_ SG_ 2432656775 Homelink_2 "Description: These group of SPN&rsquo;s contain the information for the Operator Switches. See PGN 65380 breakdown for definition of each button. ";
CM_ SG_ 2432656775 Side_Stand_Switch "Description: ";
CM_ SG_ 2432656775 Key_Fob_Lock_Button_Status "Description: These group of SPN&rsquo;s contain the information for the Operator Switches. See PGN 65380 breakdown for definition of each button. ";
CM_ SG_ 2432656775 Windshield__2_Down "Description: These group of SPN&rsquo;s contain the information for the Operator Switches. See PGN 65380 breakdown for definition of each button. ";
CM_ SG_ 2432656775 Turn__3_Cancel "Description: These group of SPN&rsquo;s contain the information for the Operator Switches. See PGN 65380 breakdown for definition of each button. ";
CM_ SG_ 2432656775 Reverse "Description: These group of SPN&rsquo;s contain the information for the Operator Switches. See PGN 65380 breakdown for definition of each button. ";
CM_ SG_ 2432656775 Hazard "Description: These group of SPN&rsquo;s contain the information for the Operator Switches. See PGN 65380 breakdown for definition of each button. ";
CM_ SG_ 2432656775 Homelink_1 "Description: These group of SPN&rsquo;s contain the information for the Operator Switches. See PGN 65380 breakdown for definition of each button. ";
CM_ SG_ 2432656775 Windshield__1_Up "Description: These group of SPN&rsquo;s contain the information for the Operator Switches. See PGN 65380 breakdown for definition of each button. ";
CM_ SG_ 2432656775 Front_Brake_Switch "Description: Indicates the status of the front brake switch ";
CM_ SG_ 2432656775 Instrument_Cluster_Control__2 "Description: These group of SPN&rsquo;s contain the information for the Operator Switches. See PGN 65380 breakdown for definition of each button. ";
CM_ SG_ 2432656775 Chassis_Unlock_Button_Status "Description: These group of SPN&rsquo;s contain the information for the Operator Switches. See PGN 65380 breakdown for definition of each button. ";
CM_ SG_ 2432656775 Power_Button "Description: These group of SPN&rsquo;s contain the information for the Operator Switches. See PGN 65380 breakdown for definition of each button. ";
CM_ SG_ 2432656775 RunStop_Switch "Description: These group of SPN&rsquo;s contain the information for the Operator Switches. See PGN 65380 breakdown for definition of each button. ";
CM_ SG_ 2432656775 Headlamp__2_High "Description: These group of SPN&rsquo;s contain the information for the Operator Switches. See PGN 65380 breakdown for definition of each button. ";
CM_ SG_ 2432656775 Instrument_Cluster_Control__1 "Description: These group of SPN&rsquo;s contain the information for the Operator Switches. See PGN 65380 breakdown for definition of each button. ";
CM_ SG_ 2432656775 Clutch_Switch "Description: These group of SPN&rsquo;s contain the information for the Operator Switches. See PGN 65380 breakdown for definition of each button. ";
CM_ SG_ 2432656775 Start "Description: These group of SPN&rsquo;s contain the information for the Operator Switches. See PGN 65380 breakdown for definition of each button. ";
CM_ SG_ 2432656775 Headlamp__3_Driving "Description: These group of SPN&rsquo;s contain the information for the Operator Switches. See PGN 65380 breakdown for definition of each button. ";
CM_ SG_ 2432656775 Cruise__2_Set "Description: These group of SPN&rsquo;s contain the information for the Operator Switches. See PGN 65380 breakdown for definition of each button. ";
CM_ SG_ 2432656775 Windshield_Wiper "Description: These group of SPN&rsquo;s contain the information for the Operator Switches. See PGN 65380 breakdown for definition of each button. ";
CM_ SG_ 2432656775 Fog "Description: These group of SPN&rsquo;s contain the information for the Operator Switches. See PGN 65380 breakdown for definition of each button. ";
CM_ SG_ 2432656775 Cruise__3_Accel "Description: These group of SPN&rsquo;s contain the information for the Operator Switches. See PGN 65380 breakdown for definition of each button. ";
CM_ SG_ 2432656775 Horn "Description: These group of SPN&rsquo;s contain the information for the Operator Switches. See PGN 65380 breakdown for definition of each button. ";
CM_ SG_ 2432656775 Turn__2_Right "Description: These group of SPN&rsquo;s contain the information for the Operator Switches. See PGN 65380 breakdown for definition of each button. ";
CM_ SG_ 2432656775 Cruise__1_On "Description: These group of SPN&rsquo;s contain the information for the Operator Switches. See PGN 65380 breakdown for definition of each button. ";
CM_ SG_ 2432656775 Turn__1_Left "Description: These group of SPN&rsquo;s contain the information for the Operator Switches. See PGN 65380 breakdown for definition of each button. ";
CM_ SG_ 2432656775 Throttle_Safety_Switch__1 "Description: These group of SPN&rsquo;s contain the information for the Operator Switches. See PGN 65380 breakdown for definition of each button. ";
CM_ SG_ 2432656775 Headlamp__1_Low "Description: These group of SPN&rsquo;s contain the information for the Operator Switches. See PGN 65380 breakdown for definition of each button. ";
CM_ SG_ 2432656775 Chassis_Lock_Switch_Status "Description:Created due to CMS fault code using this SPN";
CM_ SG_ 2432656775 Fuel_Door_Unlock_Button_Status "Description:Displays the status of the Fuel Door Unlock button. See PGN 65380 breakdown for the definition of each button.";
CM_ BO_ 2566896519 "Name: pAccessory Control Heated Grips 3
Description: Parsed from -014. ";
CM_ SG_ 2566896519 pMeasured_Voltage_2_Right_Grip "Description: Voltage at the Right Hand Grip Heater Driver
Start Position : 2.1
Type: Measured
PGN: 65467
Parsed from -014. ";
CM_ SG_ 2566896519 pMeasured_Current_1_Left_Grip "Description: Current at the Left Hand Grip Heater Driver
Start Position : 4.1
Type: Measured
PGN: 65467
Parsed from -014. ";
CM_ SG_ 2566896519 pMeasured_Current_3_Thumb "Description: Current at the Thumb Heater Driver
Start Position : 6.1
Type: Measured
PGN: 65467
Parsed from -014. ";
CM_ SG_ 2566896519 pMeasured_Voltage_1_Left_Grip "Description: Voltage at the Left Hand Grip Heater Driver
Start Position : 1.1
Type: Measured
PGN: 65467
Parsed from -014. ";
CM_ SG_ 2566896519 pMeasured_Voltage_3_Thumb "Description: Voltage at the Thumb Heater Driver
Start Position : 3.1
Type: Measured
PGN: 65467
Parsed from -014. ";
CM_ SG_ 2566896519 pMeasured_Current_2_Right_Grip "Description: Current at the Right Hand Grip Heater Driver
Start Position : 5.1
Type: Measured
PGN: 65467
Parsed from -014. ";
CM_ BO_ 2633984647 "Name: pDrive System Status
Description: Parsed from -014. ";
CM_ SG_ 2633984647 pHeated_Grip_Enable "Description: This signal indicates the status of the Heated Grip Enable switch. ";
CM_ SG_ 2633984647 pUser_PIN_Access_Status "Description: This signal indicates if the display/gauge should show the User PIN screen, which allows the user the option of unlocking the vehicle security through the PIN code entry function.  ";
CM_ SG_ 2633984647 pActive_Descent_Control_ADC_Stat "Description: Broadcasting the status of the ADC (active indicates the solenoid is powered). ";
CM_ SG_ 2633984647 pCruise_Control_Set_Status "Description: Broadcasting the status of the Cruise Control Set Status for user indication  ";
CM_ SG_ 2633984647 pTether_Switch_Status "Description: Status of the Tether Switch ";
CM_ SG_ 2633984647 pHigh_Beam_Indicator_Status "Description: Broadcasting the status of the high beam headlight for user indication. ";
CM_ SG_ 2633984647 pLow_Fuel_Indicator_Status "Description: Broadcasting the status of the fuel level for user indication. ";
CM_ SG_ 2633984647 pHeated_Grips_Percentage "Description: Heated Grips Percent On, 0% is Off and 100% is the maximum heat
Could not parse SPN data type, please add:Type: Status
Parsed from -014. ";
CM_ SG_ 2633984647 pSide_Stand_Status "Description: Position of the side stand position when installed on a vehicle. ";
CM_ SG_ 2633984647 pTurf_Mode_Requested "Description: Broadcasting the status of the users request for TURF mode ";
CM_ SG_ 2633984647 pEngine_Idle_Shutdown_Timer "Description: This signal indicates the the amount of time left before the engine is shutdown due to the unattended vehicle engine idle shutdown function.
10-bit Timer:
0 &ndash; 1021 seconds
1022 - Error
1023 - Not Availab";
CM_ SG_ 2633984647 Operator_Not_in_Operating_Statio "Description: The Operator Presence Detection System indicates the operator is not in the correct operating station. ";
CM_ SG_ 2633984647 pAWD_Mode_Requested "Description: Broadcasting the status of the users request for AWD mode ";
CM_ SG_ 2633984647 pHeated_Grips_Up_Switch_Status "Description: This signal indicates the status of the Heated Grip Up switch. ";
CM_ SG_ 2633984647 pTreadle_Neutral_Status "Description: Broadcasting the status of the switch indicating the treadle is/is not in the Neutral position.  ";
CM_ SG_ 2633984647 pHeated_Grips_Down_Switch_Status "Description: This signal indicates the status of the Heated Grip Down switch. ";
CM_ SG_ 2633984647 pPark_Brake_Indicator_Status "Description: Broadcasting the status of the park brake for user indication ";
CM_ SG_ 2633984647 pRWD_Mode_Requested "Description: Broadcasting the status of the users request for RWD mode ";
CM_ SG_ 2633984647 pSeat_Belt_Indicator_Status "Description: Broadcasting the status of the seat belt for user indication ";
CM_ SG_ 2633984647 pSecurity_Light_Immobilizer_Stat "Description: Broadcasting the status of the security system for user indication.  ";
CM_ SG_ 2633984647 ECU_Security_Status "Description: Security Status of an ECU. ";
CM_ SG_ 2633984647 pActive_Decent_Control_ADC_Mode_ "Description: Broadcasting the status of the users request for ADC mode ";
CM_ SG_ 2633984647 pTreadle_Reverse_Status "Description: Broadcasting the status of the switch indicating the treadle is/is not in the Reverse position.  ";
CM_ BO_ 2566877831 "Name: pVehicle Temperature
Description: Parsed from -014. ";
CM_ SG_ 2566877831 pRight_Hand_Grip_Temperature "Description: Temperature of thermistor in the right hand grip.
Could not parse SPN data type, please add:Type: Measured
Parsed from -014. ";
CM_ SG_ 2566877831 pDriver_Seat_Temperature "Description: Temperature of thermistor in the Driver Seat.
Could not parse SPN data type, please add:Type: Measured
Parsed from -014. ";
CM_ SG_ 2566877831 pPassenger_Seat_Temperature "Description: Temperature of thermistor in the Passenger Seat.
Could not parse SPN data type, please add:Type: Measured
Parsed from -014. ";
CM_ SG_ 2566877831 pLeft_Hand_Grip_Temperature "Description: Temperature of thermistor in the left hand grip.
Could not parse SPN data type, please add:Type: Measured
Parsed from -014. ";
CM_ BO_ 2566896263 "Name: pAccessory Control Heated Grips 2
Description: Parsed from -014. ";
CM_ SG_ 2566896263 pGrips_Duty_Cycle_Right_Hand "Description: Duty cycle output for PWM control of right hand heated grip
Could not parse SPN data type, please add:Type: Measured
Parsed from -014. ";
CM_ SG_ 2566896263 pGrips_Temperature_Right_Hand "Description: Operating temperature of Right Hand Grip
Could not parse SPN data type, please add:Type: Measured
Parsed from -014. ";
CM_ SG_ 2566896263 pGrips_Temperature_Left_Hand "Description: Operating temperature of Left Hand Grip
Could not parse SPN data type, please add:Type: Measured
Parsed from -014. ";
CM_ SG_ 2566896263 pGrips_Temperature_Thumb "Description: Operating temperature of Thumb Warmer
Could not parse SPN data type, please add:Type: Measured
Parsed from -014. ";
CM_ SG_ 2566896263 pGrips_Duty_Cycle_Thumb "Description: Duty cycle output for PWM control of thumb warmer
Could not parse SPN data type, please add:Type: Measured
Parsed from -014. ";
CM_ SG_ 2566896263 pGrips_Duty_Cycle_Left_Hand "Description: Duty cycle output for PWM control of left hand heated grip
Could not parse SPN data type, please add:Type: Measured
Parsed from -014. ";
CM_ BO_ 2365523591 "Name: pModule Control Message
Description: Parsed from -014. ";
CM_ SG_ 2365523591 pModule_Control_Applied_State "Description: Indicates the requester&rsquo;s command to control wake state of other modules. Partial Wakeup and Full Wakeup are to be defined per each module.

 ";
CM_ SG_ 2365523591 pModule_Control_Command_Destinat "Description: Indicates which source address the requester is commanding. Destination address FFh is used to indicate that all source addresses should obey the Module Control Command State signal. FFFFh indicates &ldquo;no";
CM_ SG_ 2365523591 pModule_Control_Command_State "Description: Indicates the requester&rsquo;s command to control wake state of other modules. Each state to be defined per each module. ";
CM_ SG_ 2365523591 pModule_Control_Message_Checksum "Description: Message checksum that is calculated as follows:
Intermediate Checksum =
Byte1 + Byte2 + Byte3 + Byte4 + Byte5 + Byte6 + Byte7 + (8.1 Nibble & 0x0F) + Message ID Low Byte + Message ID Mid Low Byte + Message ";
CM_ BO_ 2566878092 "Name: pRemote EPS Control 1
Description: Information regarding the command mode of an Electric Power Steering Unit (EPS). This contains the mode in which the EPS is commanded as well as two variables pertaining to each individual commanded mode.
Parsed";
CM_ SG_ 2566878092 pEPS_Commanded_Var2 "Description: This is the power steering command variable 2. **Note &ndash; The interpretation of this variable changes based on the EPS commanded control mode, SPN 524111.

For all interpretations:
Could not parse SPN data type, pl";
CM_ SG_ 2566878092 pEPS_Commanded_Control_Mode "Description: The commanded control mode that the EPS unit will operate in. ";
CM_ SG_ 2566878092 pEPS_Commanded_Var1 "Description: This is the power steering command variable 1. **Note &ndash; The interpretation of this variable changes based on the EPS commanded control mode, SPN 524111.

Parsed from -014. SPN 524111 - Mode 3(0x03) Variable Descri";
CM_ BO_ 2231334284 "Name: pRemote Vehicle Control 1
Description:";
CM_ SG_ 2231334284 Normalized_Accelerator_Position_ "Description:Commanded accelerator position as a percent of maximum accelerator position. Could not parse SPN data type, please add:Type: Measured
Parsed from Confidential -014.";
CM_ SG_ 2231334284 Operation_Mode_Status "Description:States defined are as follows:
00 - Manned
01 - Remote
10 - Error Indicator
11 - Not Available
Could not parse SPN data type, please add:Type: Measured
Parsed from Confidential -014.";
CM_ SG_ 2231334284 StartStop_Vehicle_Command "Description:Start or stop command to the vehicle's primary controller. The primary controller could be a hybrid controller or engine controller.  The message acts as a start/stop request for an engine controller.
00 - Not Press";
CM_ SG_ 2231334284 Message_Counter "Description:The message counter is used to detect situations where the transmitting ECU malfunction repeats the same frame all the timeCould not parse SPN data type, please add:Type: Measured
Parsed from Confidential -014.";
CM_ SG_ 2231334284 Checksum "Description:Used to verify the signal path from the transmitting device to the receiving device. The message checksum is calculated using the first 7 data bytes, the message counter and the bytes of the message identifier.Could not parse SPN dat";
CM_ BO_ 2231313804 "Name: pRemote Control Status
Description:Contains status information on connection to the remote control system.";
CM_ SG_ 2231313804 Radio_System_Status "Description:Status of the off vehicle remote control radio connection.
States defined as follows: 
00b â€“ Off
01b â€“ On
10b â€“ Error
11b â€“ Not availableCould not parse SPN data type, please add:Type: Status 
Parsed from Confident";
CM_ SG_ 2231313804 IOP_Discovery_Status "Description:Status of the remote control radio to vehicle IOP discovery.
States defined as follows: 
00b â€“ Not Discovered
01b â€“ Discovered
10b â€“ Error
11b â€“ Not availableCould not parse SPN data type, please add:Type: Status ";
CM_ SG_ 2231313804 IOP_Authentication_Status "Description:Status of the remote control radio to vehicle IOP authentication.
States defined as follows: 
00b â€“ Not Authenticated
01b â€“ Authenticated
10b â€“ Error
11b â€“ Not availableCould not parse SPN data type, please a";
CM_ SG_ 2231313804 Remote_Control_System_Status "Description:Status of the remote control radio system.
States defined as follows: 
00b â€“ Not Enabled
01b â€“ Enabled
10b â€“ Error
11b â€“ Not availableCould not parse SPN data type, please add:Type: Status 
Parsed from Con";
CM_ SG_ 2231313804 Remote_EStop_Status "Description:Status of the remote E-stop. 
States defined as follows: 
00b â€“ Not Enabled
01b â€“ Enabled
10b â€“ Error
11b â€“ Not availableCould not parse SPN data type, please add:Type: Status 
Parsed from Confidential -014.";
CM_ SG_ 2231313804 Network_signal_strength "Description:Indicates the strength of the remote control radio to vehicle signal strength. Could not parse SPN data type, please add:Type: Measured 
Parsed from Confidential -014.";
CM_ BO_ 2231336332 "Name: Remote Brake Control 1
Description:Communicated on the vehicle communication bus.  Contains signals to command the vehicle’s braking system.";
CM_ SG_ 2231336332 pActual_Braking_Application "Description:Signal to provide information about the current applied braking. 0% is no braking; 100% is full braking.
Units:			%Could not parse offset, please add:Offset:		0
Could not parse SPN data type, please add:Type:			Mea";
CM_ SG_ 2231336332 pEBC_Mode_Status "Description:Signal to provide the current state of the EBC Controller. Parsed from Confidential 014.";
CM_ SG_ 2231336332 Message_Counter "Description:Input Description: The message counter is used to detect situations where the transmitting ECU malfunction repeats the same frame all the time.Could not parse offset, please add:Offset:		0
Could not parse SPN data type, please";
CM_ SG_ 2231336332 Message_Checksum "Description:Used to verify the signal path from Transmitter up to the Application Software layer of the Receiver.
Calculated using the following formula:
<INSERT FORMULA>Could not parse offset, please add:Offset:		0
Could not parse SPN d";
CM_ BO_ 2365531276 "Name: pVehModCmd
Description:Vehicle Mode Command";
CM_ SG_ 2365531276 pEPSReqMod "Description: Used to set the EPAS assist mode. ";
CM_ BO_ 2365536141 "Name: pIMU3
Description: Inertial Momentum Unit Information used for ABS/TC/MSC functionality.
Parsed from -014. ";
CM_ SG_ 2365536141 pAcceleration_Sensor_Signal_2 "Description: Acceleration Sensor Data (Please see specifc controller for which acceleration direction)
Units: G&rsquo;s
Data Range: -4.1768 &ndash; 4.1768
Data Length: 2 bytes
Start Position: 5.1
Type: Measured
PGN: 65";
CM_ SG_ 2365536141 pIMU3_Checksum "Description: Could not parse SPN data type, please add:Type: Status
Parsed from -014. ";
CM_ SG_ 2365536141 pIMU3_Rolling_Counter "Description: Message counter that increments by one for each transmission from 0 to 15 and then rolls over.
Could not parse SPN data type, please add:Type: Status
Parsed from -014. ";
CM_ SG_ 2365536141 pAngular_Rate_Signal_3_Status "Description: Status Bits for Angular Sensor 3 Information ";
CM_ SG_ 2365536141 pAcceleration_Sensor_Signal_2_St "Description: Acceleration Sensor Signal 2 Status Information (See specific controller for which direction) ";
CM_ SG_ 2365536141 pAngular_Rate_Signal_3 "Description: Angular Data for ABS Calculations (See specific controller for which axys)
Could not parse offset, please add:Offset: -163.64
Could not parse SPN data type, please add:Type: Measured
Parsed from -014. ";
CM_ BO_ 2365536653 "Name: pIMU1
Description: Inertial Momentum Unit Information used for ABS/TC/MSC functionality.
Parsed from -014. ";
CM_ SG_ 2365536653 pAngular_Rate_Signal_1_Status "Description: Status Bits for Angular Sensor 1 Information ";
CM_ SG_ 2365536653 pAngular_Rate_Signal_1 "Description: Angular Data for ABS Calculations (See specific controller for which axys)
Could not parse offset, please add:Offset: -163.64
Could not parse SPN data type, please add:Type: Measured
Parsed from -014. ";
CM_ SG_ 2365536653 pIMU_Address_Information "Description: ASCII Representation of Addressing for IMU information content.
Could not parse SPN data type, please add:Type: Measured
Parsed from -014. ";
CM_ SG_ 2365536653 pIMU_Information_Content "Description: Serial ASCII code that will populate an ID block for the IMU representing information about the part. 
Could not parse SPN data type, please add:Type: Measured
Parsed from -014. ";
CM_ SG_ 2365536653 pAcceleration_Sensor_Signal_1 "Description: Acceleration Sensor Data (Please see specifc controller for which acceleration direction)
Units: G&rsquo;s
Data Range: -4.1768 &ndash; 4.1768
Data Length: 2 bytes
Start Position: 5.1
Type: Measured
PGN: 65";
CM_ SG_ 2365536653 pAcceleration_Sensor_Signal_1_St "Description: Acceleration Sensor Signal 1 Status Information (See specific controller for which direction) ";
CM_ SG_ 2365536653 pIMU1_Rolling_Counter "Description: Message counter that increments by one for each transmission from 0 to 15 and then rolls over.
Could not parse SPN data type, please add:Type: Status
Parsed from -014. ";
CM_ SG_ 2365536653 pIMU1_Checksum "Description: Could not parse SPN data type, please add:Type: Status
Parsed from -014. ";
CM_ BO_ 2365536397 "Name: pIMU2
Description: Inertial Momentum Unit Information used for ABS/TC/MSC functionality.
Parsed from -014. ";
CM_ SG_ 2365536397 IMU_HW_Index "Description:Bits used to identify difference between 2 different Momentum Units.
Could not parse offset, please add:Offset: N/A
Could not parse SPN data type, please add:Type: Measured
Parsed from -014.";
CM_ SG_ 2365536397 pAcceleration_Sensor_Signal_3 "Description: Acceleration Sensor Data (Please see specifc controller for which acceleration direction)
Units: G&rsquo;s
Data Range: -4.1768 &ndash; 4.1768
Data Length: 2 bytes
Start Position: 5.1
Type: Measured
PGN: 65";
CM_ SG_ 2365536397 pAcceleration_Sensor_Signal_3_St "Description: Acceleration Sensor Signal 1 Status Information (See specific controller for which direction) ";
CM_ SG_ 2365536397 pIMU2_Checksum "Description: Could not parse SPN data type, please add:Type: Status
Parsed from -014. ";
CM_ SG_ 2365536397 pAngular_Rate_Signal_2 "Description: Angular Data for ABS Calculations (See specific controller for which axys)
Could not parse offset, please add:Offset: -163.64
Could not parse SPN data type, please add:Type: Measured
Parsed from -014. ";
CM_ SG_ 2365536397 pAngular_Rate_Signal_2_Status "Description: Status Bits for Angular Sensor 2 Information ";
CM_ SG_ 2365536397 pIMU2_Rolling_Counter "Description: Message counter that increments by one for each transmission from 0 to 15 and then rolls over.
Could not parse SPN data type, please add:Type: Status
Parsed from -014. ";
CM_ BO_ 2432656784 "Name: pOperator Switch Status
Description: Parsed from -014. ";
CM_ SG_ 2432656784 Key_Fob_Unlock_Button_Status "Description: These group of SPN&rsquo;s contain the information for the Operator Switches. See PGN 65380 breakdown for definition of each button. ";
CM_ SG_ 2432656784 Homelink_2 "Description: These group of SPN&rsquo;s contain the information for the Operator Switches. See PGN 65380 breakdown for definition of each button. ";
CM_ SG_ 2432656784 Side_Stand_Switch "Description: ";
CM_ SG_ 2432656784 Key_Fob_Lock_Button_Status "Description: These group of SPN&rsquo;s contain the information for the Operator Switches. See PGN 65380 breakdown for definition of each button. ";
CM_ SG_ 2432656784 Windshield__2_Down "Description: These group of SPN&rsquo;s contain the information for the Operator Switches. See PGN 65380 breakdown for definition of each button. ";
CM_ SG_ 2432656784 Turn__3_Cancel "Description: These group of SPN&rsquo;s contain the information for the Operator Switches. See PGN 65380 breakdown for definition of each button. ";
CM_ SG_ 2432656784 Reverse "Description: These group of SPN&rsquo;s contain the information for the Operator Switches. See PGN 65380 breakdown for definition of each button. ";
CM_ SG_ 2432656784 Hazard "Description: These group of SPN&rsquo;s contain the information for the Operator Switches. See PGN 65380 breakdown for definition of each button. ";
CM_ SG_ 2432656784 Homelink_1 "Description: These group of SPN&rsquo;s contain the information for the Operator Switches. See PGN 65380 breakdown for definition of each button. ";
CM_ SG_ 2432656784 Windshield__1_Up "Description: These group of SPN&rsquo;s contain the information for the Operator Switches. See PGN 65380 breakdown for definition of each button. ";
CM_ SG_ 2432656784 Front_Brake_Switch "Description: Indicates the status of the front brake switch ";
CM_ SG_ 2432656784 Instrument_Cluster_Control__2 "Description: These group of SPN&rsquo;s contain the information for the Operator Switches. See PGN 65380 breakdown for definition of each button. ";
CM_ SG_ 2432656784 Chassis_Unlock_Button_Status "Description: These group of SPN&rsquo;s contain the information for the Operator Switches. See PGN 65380 breakdown for definition of each button. ";
CM_ SG_ 2432656784 Power_Button "Description: These group of SPN&rsquo;s contain the information for the Operator Switches. See PGN 65380 breakdown for definition of each button. ";
CM_ SG_ 2432656784 RunStop_Switch "Description: These group of SPN&rsquo;s contain the information for the Operator Switches. See PGN 65380 breakdown for definition of each button. ";
CM_ SG_ 2432656784 Headlamp__2_High "Description: These group of SPN&rsquo;s contain the information for the Operator Switches. See PGN 65380 breakdown for definition of each button. ";
CM_ SG_ 2432656784 Instrument_Cluster_Control__1 "Description: These group of SPN&rsquo;s contain the information for the Operator Switches. See PGN 65380 breakdown for definition of each button. ";
CM_ SG_ 2432656784 Clutch_Switch "Description: These group of SPN&rsquo;s contain the information for the Operator Switches. See PGN 65380 breakdown for definition of each button. ";
CM_ SG_ 2432656784 Start "Description: These group of SPN&rsquo;s contain the information for the Operator Switches. See PGN 65380 breakdown for definition of each button. ";
CM_ SG_ 2432656784 Headlamp__3_Driving "Description: These group of SPN&rsquo;s contain the information for the Operator Switches. See PGN 65380 breakdown for definition of each button. ";
CM_ SG_ 2432656784 Cruise__2_Set "Description: These group of SPN&rsquo;s contain the information for the Operator Switches. See PGN 65380 breakdown for definition of each button. ";
CM_ SG_ 2432656784 Windshield_Wiper "Description: These group of SPN&rsquo;s contain the information for the Operator Switches. See PGN 65380 breakdown for definition of each button. ";
CM_ SG_ 2432656784 Fog "Description: These group of SPN&rsquo;s contain the information for the Operator Switches. See PGN 65380 breakdown for definition of each button. ";
CM_ SG_ 2432656784 Cruise__3_Accel "Description: These group of SPN&rsquo;s contain the information for the Operator Switches. See PGN 65380 breakdown for definition of each button. ";
CM_ SG_ 2432656784 Horn "Description: These group of SPN&rsquo;s contain the information for the Operator Switches. See PGN 65380 breakdown for definition of each button. ";
CM_ SG_ 2432656784 Turn__2_Right "Description: These group of SPN&rsquo;s contain the information for the Operator Switches. See PGN 65380 breakdown for definition of each button. ";
CM_ SG_ 2432656784 Cruise__1_On "Description: These group of SPN&rsquo;s contain the information for the Operator Switches. See PGN 65380 breakdown for definition of each button. ";
CM_ SG_ 2432656784 Turn__1_Left "Description: These group of SPN&rsquo;s contain the information for the Operator Switches. See PGN 65380 breakdown for definition of each button. ";
CM_ SG_ 2432656784 Throttle_Safety_Switch__1 "Description: These group of SPN&rsquo;s contain the information for the Operator Switches. See PGN 65380 breakdown for definition of each button. ";
CM_ SG_ 2432656784 Headlamp__1_Low "Description: These group of SPN&rsquo;s contain the information for the Operator Switches. See PGN 65380 breakdown for definition of each button. ";
CM_ SG_ 2432656784 Chassis_Lock_Switch_Status "Description:Created due to CMS fault code using this SPN";
CM_ SG_ 2432656784 Fuel_Door_Unlock_Button_Status "Description:Displays the status of the Fuel Door Unlock button. See PGN 65380 breakdown for the definition of each button.";
CM_ BO_ 2365473169 "Name: Lighting Command LCMD
Description: Parsed from -014. ";
CM_ SG_ 2365473169 Left_Turn_Signal_Lights_Command "Description:Command to activate or de-activate left turn signal lights on the tractor and all connected implements 00b = De-activate 01b = Activate 10b = Reserved 11b = Don't Care
Note: Parsed from J1939DA.";
CM_ SG_ 2365473169 Alternate_Beam_Head_Light_Comman "Description:Command to activate or de-activate the tractor alternate head lights (only low beam is available on alternate head lights). The alternate position lights are intended for use with loader and snow plows that te";
CM_ SG_ 2365473169 Right_Turn_Signal_Lights_Command "Description:Command to activate or de-activate right turn signal lights on the tractor and all connected implements 00b = De-activate 01b = Activate 10b = Reserved 11b = Don't Care
Note: Parsed from J1939DA.";
CM_ SG_ 2365473169 Running_Light_Command "Description:Command to activate or de-activate the tractor or powered vehicle running lights. Usually only used for on road vehicles. 00b = De-activate 01b = Activate 10b = Reserved 11b = Don't Care
Note: Parsed from J1939DA.";
CM_ BO_ 2563833767 "Name: Cab Illumination Message
Description: Parsed from -014. ";
CM_ SG_ 2563833767 Illumination_Brightness_Percent "Description:Commanded backlight brightness level for all cab displays. Note: If a separate device is used to independently control the switch backlight brightness level, see SPN 5532.
Note: Parsed from J1939DA.";
CM_ BO_ 2566847655 "Name: Dash Display
Description: Parsed from -014. ";
CM_ SG_ 2566847655 Fuel_Level_1 "Description:Ratio of volume of fuel to the total volume of fuel storage container. When Fuel Level 2 (SPN 38) is not used, Fuel Level 1 represents the total fuel in all fuel storage containers. When Fuel Level 2 is used, Fuel Level 1 represe";
CM_ BO_ 2566834855 "Name: Active Diagnostic Trouble Codes
Description:DM1 provides diagnostic lamp status and Diagnostic Trouble Codes (DTCs). Together, the lamp and DTC information
convey the diagnostic condition of the transmitting electronic component to other componen";
CM_ SG_ 2566834855 Flash_Malfunction_Indicator_Lamp "Description:This parameter provides the capability to flash the MIL. For OBD systems which are required to flash the SPN for specific malfunctions shall use the “slow flash” rate. 
See J1939-73 for complete reference
Pa";
CM_ SG_ 2566834855 Malfunction_Indicator_Lamp_Statu "Description:Used to relay only emissions-related trouble code information. This lamp is only illuminated when there is an emission-related trouble code active.
See J1939-71 for complete reference

Parsed from -014.";
CM_ SG_ 2566834855 Red_Stop_Lamp_Status "Description:Used to relay trouble code information that is of a severe enough condition that it warrants stopping the vehicle.
See J1939-71 for complete reference

Parsed from -014.";
CM_ SG_ 2566834855 Amber_Warning_Lamp_Status "Description:Used to relay trouble code information that is reporting a problem with the vehicle system but the vehicle need not be immediately stopped.
See J1939-71 for complete reference

Parsed from -014.";
CM_ SG_ 2566834855 Flash_Red_Stop_Lamp_RSL "Description:This parameter provides the capability to flash the RSL.
See J1939-73 for complete reference
Parsed from -014.";
CM_ SG_ 2566834855 Flash_Amber_Warning_Lamp_AWL "Description:This parameter provides the capability to flash the AWL. 
See J1939-73 for complete reference
Parsed from -014.";
CM_ SG_ 2566834855 Flash_Protect_Lamp "Description:This parameter provides the capability to flash the protect lamp. 
See J1939-73 for complete reference
Parsed from -014.";
CM_ SG_ 2566834855 Protect_Lamp_Status "Description:Used to relay trouble code information that is reporting a problem with a vehicle system that is most probably not electronic subsystem related. For instance, engine coolant temperature is exceeding its prescribed temperat";
CM_ SG_ 2566834855 DTC_1 "Description:This signal is a combination of 4 SPNs. To decode this signal, navigate to MCS tools.
Byte: 1 bits 8-1 SPN, 8 least significant bits of SPN (most significant at bit 8, SPN 1214)
Byte: 2 bits 8-1 SPN, second byte of SPN (most significa";
CM_ SG_ 2566834855 DTC_2 "Description:This signal is a combination of 4 SPNs. To decode this signal, navigate to MCS tools.
Byte: 1 bits 8-1 SPN, 8 least significant bits of SPN (most significant at bit 8, SPN 1214)
Byte: 2 bits 8-1 SPN, second byte of SPN (most significa";
CM_ SG_ 2566834855 DTC_3 "Description:This signal is a combination of 4 SPNs. To decode this signal, navigate to MCS tools.
Byte: 1 bits 8-1 SPN, 8 least significant bits of SPN (most significant at bit 8, SPN 1214)
Byte: 2 bits 8-1 SPN, second byte of SPN (most significa";
CM_ SG_ 2566834855 DTC_4 "Description:This signal is a combination of 4 SPNs. To decode this signal, navigate to MCS tools.
Byte: 1 bits 8-1 SPN, 8 least significant bits of SPN (most significant at bit 8, SPN 1214)
Byte: 2 bits 8-1 SPN, second byte of SPN (most significa";
CM_ SG_ 2566834855 DTC_5 "Description:This signal is a combination of 4 SPNs. To decode this signal, navigate to MCS tools.
Byte: 1 bits 8-1 SPN, 8 least significant bits of SPN (most significant at bit 8, SPN 1214)
Byte: 2 bits 8-1 SPN, second byte of SPN (most significa";
CM_ SG_ 2566834855 DTC_6 "Description:This signal is a combination of 4 SPNs. To decode this signal, navigate to MCS tools.
Byte: 1 bits 8-1 SPN, 8 least significant bits of SPN (most significant at bit 8, SPN 1214)
Byte: 2 bits 8-1 SPN, second byte of SPN (most significa";
CM_ SG_ 2566834855 DTC_7 "Description:This signal is a combination of 4 SPNs. To decode this signal, navigate to MCS tools.
Byte: 1 bits 8-1 SPN, 8 least significant bits of SPN (most significant at bit 8, SPN 1214)
Byte: 2 bits 8-1 SPN, second byte of SPN (most significa";
CM_ SG_ 2566834855 DTC_8 "Description:This signal is a combination of 4 SPNs. To decode this signal, navigate to MCS tools.
Byte: 1 bits 8-1 SPN, 8 least significant bits of SPN (most significant at bit 8, SPN 1214)
Byte: 2 bits 8-1 SPN, second byte of SPN (most significa";
CM_ SG_ 2566834855 DTC_9 "Description:This signal is a combination of 4 SPNs. To decode this signal, navigate to MCS tools.
Byte: 1 bits 8-1 SPN, 8 least significant bits of SPN (most significant at bit 8, SPN 1214)
Byte: 2 bits 8-1 SPN, second byte of SPN (most significa";
CM_ SG_ 2566834855 DTC_10 "Description:This signal is a combination of 4 SPNs. To decode this signal, navigate to MCS tools.
Byte: 1 bits 8-1 SPN, 8 least significant bits of SPN (most significant at bit 8, SPN 1214)
Byte: 2 bits 8-1 SPN, second byte of SPN (most signific";
CM_ BO_ 2566844839 "Name: Cruise Control Vehicle Speed 1
Description: Parsed from -014. ";
CM_ SG_ 2566844839 Cruise_Control_Set_Speed "Description:Value of set (chosen) velocity of velocity control system. See SPN 6809 for an alternate resolution. If an algorithm that can modify the cruise control set point exists in the system, such as Predictive Cruise Control";
CM_ SG_ 2566844839 Cruise_Control_Active "Description:Cruise control is switched on. It is not ensured that the engine is controlled by cruise control, as in the case of a large driver's demand the engine is controlled by the driver while cruise control is active (maximum s";
CM_ SG_ 2566844839 Clutch_Switch "Description:Switch signal which indicates that the clutch pedal is being pressed. It is necessary for a safe drivetrain behavior that the clutch switch is set before the clutch is opened (cruise control function). 00b = Clutch pedal release";
CM_ SG_ 2566844839 Brake_Switch "Description:Switch signal which indicates that the driver operated brake foot pedal is being pressed. This brake foot pedal is controlling the vehicles' service brake (total vehicle braking application, not park brakes). It is necessary for ";
CM_ SG_ 2566844839 pCC_Message_Counter "Description: Rolling Counter (ensures updated message is used).
Could not parse SPN data type, please add:Type: Status
Parsed from -014. ";
CM_ SG_ 2566844839 Cruise_Control_Pause_Switch "Description:Switch signal which indicates the position of the Cruise Control Pause Switch used on Remote Cruise Control applications. The Cruise Control Pause Switch signal temporarily disables the Cruise Control function. 00b";
CM_ SG_ 2566844839 Cruise_Control_Set_Switch "Description:Switch signal of the cruise control activator which indicates that the activator is in the position set. 00b = Cruise control activator not in the position set 01b = Cruise control activator in position set 10b = Err";
CM_ SG_ 2566844839 Two_Speed_Axle_Switch "Description:Switch signal which indicates the current axle range. 00b = Low speed range 01b = High speed range 10b = Error 11b = Not available
Note: Parsed from J1939DA.";
CM_ SG_ 2566844839 Cruise_Control_Enable_Switch "Description:Switch signal which indicates that it is possible to manage the cruise control function. 00b = Cruise control disabled 01b = Cruise control enabled 10b = Error 11b = Not available
Note: Parsed from J1939DA.";
CM_ SG_ 2566844839 pOdometer_Drive_Bit "Description: Each State A->B or B->A change indicates the vehicle has moved 40 m since the previous one. However, since the message is sent at regular 100 ms intervals, State A and B each occur multiple times consecutively (a minimum ";
CM_ SG_ 2566844839 pCC_Checksum "Description: XOR of bytes 0-6 (ensures data is valid before use). 
Could not parse SPN data type, please add:Type: Status
Parsed from -014. ";
CM_ SG_ 2566844839 WheelBased_Vehicle_Speed "Description:Speed of the vehicle as calculated from wheel or tailshaft speed.
Note: Parsed from J1939DA.";
CM_ SG_ 2566844839 Cruise_Control_Resume_Switch "Description:Switch signal of the cruise control activator which indicates that the activator is in the position resume. 00b = Cruise control activator not in the position resume 01b = Cruise control activator in position resu";
CM_ SG_ 2566844839 Cruise_Control_Accelerate_Switch "Description:Switch signal of the cruise control activator which indicates that the activator is in the position accelerate. 00b = Cruise control activator not in the position accelerate 01b = Cruise control activator in p";
CM_ SG_ 2566844839 pCruise_Enable_Status "Description: The Cruise Control System has been enabled by the operator. (Amber Light) ";
CM_ SG_ 2566844839 Parking_Brake_Switch "Description:Switch signal which indicates when the parking brake is set. In general the switch actuated by the operator's park brake control, whether a pedal, lever or other control mechanism (see also SPN 619 and 5275). 00b = Parkin";
CM_ SG_ 2566844839 Cruise_Control_Coast_Decelerate_ "Description:Switch signal of the cruise control activator which indicates that the activator is in the position coast (decelerate). 00b = Cruise control activator not in the position coast 01b = Cruise control activator i";
CM_ BO_ 2566877607 "Name: pCluster Status 1
Description: Parsed from -014. ";
CM_ SG_ 2566877607 pTemperature_Units_Selected "Description: Active display temperature units beased on user selection or auto-configuration. ";
CM_ SG_ 2566877607 pTPMS_Learning_Status "Description: Indicates the status of the tire pressure monitoring sensor learning process. ";
CM_ SG_ 2566877607 pPressure_Units_Selected "Description: Active display pressure units beased on user selection or auto-configuration. ";
CM_ SG_ 2566877607 pHigh_Res_Trip_2_Distance "Description: Secondary distance travled during all or part of a journey.
Could not parse SPN data type, please add:Type: Measured
Parsed from -014. ";
CM_ SG_ 2566877607 pVolume_Units_Selected "Description: Active display volume units beased on user selection or auto-configuration. ";
CM_ SG_ 2566877607 pDisplay_Status "Description: Status of display. ";
CM_ SG_ 2566877607 pTime_Units_Selected "Description: Active display time units beased on user selection or auto-configuration. ";
CM_ SG_ 2566877607 pDistance_Units_Selected "Description: Active display distance units beased on user selection or auto-configuration. ";
CM_ BO_ 2298415599 "Name: pTemperature Message
Description: Parsed from -014. ";
CM_ SG_ 2298415599 pJunction_Temp "Description: Actual junction temperature of the Electric Propulsion Control Unit or Auxiliary Power Unit from which the message is sent

Could not parse SPN data type, please add:Type: Measured
Parsed from -014. ";
CM_ SG_ 2298415599 pCapacitor_Temp "Description: Actual capacitor temperature of the Electric Propulsion Control Unit or Auxiliary Power Unit from which the message is sent

Could not parse SPN data type, please add:Type: Measured
Parsed from -014. ";
CM_ SG_ 2298415599 pMotor_Temp_Margin "Description: The smallest difference between an internal motor component and its thermal limit for the Electric Propulsion Control Unit or Auxiliary Power Control Unit from which the message is sent

Could not parse SPN data type, pl";
CM_ SG_ 2298415599 pBaseplate_Temp "Description: Actual baseplate temperature of the Electric Propulsion Control Unit or Auxiliary Power Unit from which the message is sent

Data Length: 1 byte 
Start Position: 3.1
Type: Measured
PGN: 65289
Parsed from -014. ";
CM_ SG_ 2298415599 pBoard_Temp "Description: Board temperature of the Electric Propulsion Control Unit or Auxiliary Power Unit from which the message is sent

Could not parse SPN data type, please add:Type: Measured
Parsed from -014. ";
CM_ SG_ 2298415599 pController_Temp_Margin "Description: The smallest difference between an internal component and its thermal limit for the Electric Propulsion Control Unit or Auxiliary Power Control Unit from which the message is sent

Could not parse SPN data type, ple";
CM_ SG_ 2298415599 pTemperature_Message_Checksum "Description: Checksum is calculated by taking XOR of bytes from 1 to 7.
Could not parse SPN data type, please add:Type: Status
Parsed from -014. ";
CM_ SG_ 2298415599 pMotor_Temp "Description: Actual motor temperature of the Electric Propulsion Unit or Auxiliary Power Unit from which the message is sent

Could not parse SPN data type, please add:Type: Measured
Parsed from -014. ";
CM_ BO_ 2298415087 "Name: pPerformance Message
Description: Parsed from -014. ";
CM_ SG_ 2298415087 pPerformance_Message_Checksum "Description: Checksum is calculated by taking XOR of bytes from 1 to 7.
Could not parse SPN data type, please add:Type: Status
Parsed from -014. ";
CM_ SG_ 2298415087 pLower_Available_Torque_Limit "Description: The maximum torque available in the reverse direction. Lower available torque is normally negative but can be positive in a negative overspeed condition.

Could not parse SPN data type, please add:Type: Status";
CM_ SG_ 2298415087 pPerformance_State "Description: Bits dictating the state of the Electric Propulsion Control Unit or Auxiliary Power Unit from which the message is sent. ";
CM_ SG_ 2298415087 pActual_Motor_Torque "Description: Actual generated torque from Electronic Propulsion unit

Could not parse SPN data type, please add:Type: Status
Parsed from -014. ";
CM_ SG_ 2298415087 pUpper_Available_Torque_Limit "Description: The maximum torque available in the positive direction. Upper available torque is normally negative but can be positive in a negative overspeed condition.

Could not parse SPN data type, please add:Type: Statu";
CM_ SG_ 2298415087 pActual_Motor_Velocity "Description: Actual RPM of the Electric Propulsion Control Unit or Auxiliary Power Unit from which the message is sent.

Could not parse SPN data type, please add:Type: Measured
Parsed from -014. ";
CM_ SG_ 2298415087 pPer_Msg_Count "Description:Created due to CMS fault code using this SPN";
CM_ BO_ 2298415343 "Name: pPower Message
Description: Parsed from -014. ";
CM_ SG_ 2298415343 pController_Thermal_Cutback_Stat "Description: Status bit indicating the ramp down of motor control output and subsequent vehicle performance due to the temperature of the motor controller exceeding a predefined value. ";
CM_ SG_ 2298415343 pCapacitor_Voltage "Description: Capacitor Voltage of the Electric Propulsion Control Unit or Auxiliary Power Control Unit from which the message is sent.

Could not parse SPN data type, please add:Type: Measured
Parsed from -014. ";
CM_ SG_ 2298415343 pMotor_Power_Cutback_Status "Description: Status bit indicating the ramp down of motor control output and subsequent vehicle performance due to low power availability. ";
CM_ SG_ 2298415343 pInput_Current "Description: Input DC Current of the Electric Propulsion Control Unit or Auxiliary Power Control Unit from which the message is sent.

Could not parse SPN data type, please add:Type: Measured
Parsed from -014. ";
CM_ SG_ 2298415343 pMotor_Thermal_Cutback_Status "Description: Status bit indicating the ramp down of motor control output and subsequent vehicle performance due to the temperature of the motor exceeding a predefined value. ";
CM_ SG_ 2298415343 pInput_DC_Current_Cutback_Status "Description: Status bit indicating the ramp down of motor control output and subsequent vehicle performance due to low Input Current. ";
CM_ SG_ 2298415343 pSpeed_Limit_Cutback_Status "Description: Status bit indicating the ramp down of motor control output and subsequent vehicle performance due to the motor speed exceeding the limits set for the motor.  ";
CM_ SG_ 2298415343 pPower_Message_Checksum "Description: Checksum is calculated by taking XOR of bytes from 1 to 7.
Could not parse SPN data type, please add:Type: Status
Parsed from -014. ";
CM_ BO_ 2298415600 "Name: pTemperature Message
Description: Parsed from -014. ";
CM_ SG_ 2298415600 pJunction_Temp "Description: Actual junction temperature of the Electric Propulsion Control Unit or Auxiliary Power Unit from which the message is sent

Could not parse SPN data type, please add:Type: Measured
Parsed from -014. ";
CM_ SG_ 2298415600 pCapacitor_Temp "Description: Actual capacitor temperature of the Electric Propulsion Control Unit or Auxiliary Power Unit from which the message is sent

Could not parse SPN data type, please add:Type: Measured
Parsed from -014. ";
CM_ SG_ 2298415600 pMotor_Temp_Margin "Description: The smallest difference between an internal motor component and its thermal limit for the Electric Propulsion Control Unit or Auxiliary Power Control Unit from which the message is sent

Could not parse SPN data type, pl";
CM_ SG_ 2298415600 pBaseplate_Temp "Description: Actual baseplate temperature of the Electric Propulsion Control Unit or Auxiliary Power Unit from which the message is sent

Data Length: 1 byte 
Start Position: 3.1
Type: Measured
PGN: 65289
Parsed from -014. ";
CM_ SG_ 2298415600 pBoard_Temp "Description: Board temperature of the Electric Propulsion Control Unit or Auxiliary Power Unit from which the message is sent

Could not parse SPN data type, please add:Type: Measured
Parsed from -014. ";
CM_ SG_ 2298415600 pController_Temp_Margin "Description: The smallest difference between an internal component and its thermal limit for the Electric Propulsion Control Unit or Auxiliary Power Control Unit from which the message is sent

Could not parse SPN data type, ple";
CM_ SG_ 2298415600 pTemperature_Message_Checksum "Description: Checksum is calculated by taking XOR of bytes from 1 to 7.
Could not parse SPN data type, please add:Type: Status
Parsed from -014. ";
CM_ SG_ 2298415600 pMotor_Temp "Description: Actual motor temperature of the Electric Propulsion Unit or Auxiliary Power Unit from which the message is sent

Could not parse SPN data type, please add:Type: Measured
Parsed from -014. ";
CM_ BO_ 2298415088 "Name: pPerformance Message
Description: Parsed from -014. ";
CM_ SG_ 2298415088 pPerformance_Message_Checksum "Description: Checksum is calculated by taking XOR of bytes from 1 to 7.
Could not parse SPN data type, please add:Type: Status
Parsed from -014. ";
CM_ SG_ 2298415088 pLower_Available_Torque_Limit "Description: The maximum torque available in the reverse direction. Lower available torque is normally negative but can be positive in a negative overspeed condition.

Could not parse SPN data type, please add:Type: Status";
CM_ SG_ 2298415088 pPerformance_State "Description: Bits dictating the state of the Electric Propulsion Control Unit or Auxiliary Power Unit from which the message is sent. ";
CM_ SG_ 2298415088 pActual_Motor_Torque "Description: Actual generated torque from Electronic Propulsion unit

Could not parse SPN data type, please add:Type: Status
Parsed from -014. ";
CM_ SG_ 2298415088 pUpper_Available_Torque_Limit "Description: The maximum torque available in the positive direction. Upper available torque is normally negative but can be positive in a negative overspeed condition.

Could not parse SPN data type, please add:Type: Statu";
CM_ SG_ 2298415088 pActual_Motor_Velocity "Description: Actual RPM of the Electric Propulsion Control Unit or Auxiliary Power Unit from which the message is sent.

Could not parse SPN data type, please add:Type: Measured
Parsed from -014. ";
CM_ SG_ 2298415088 pPer_Msg_Count "Description:Created due to CMS fault code using this SPN";
CM_ BO_ 2298415344 "Name: pPower Message
Description: Parsed from -014. ";
CM_ SG_ 2298415344 pController_Thermal_Cutback_Stat "Description: Status bit indicating the ramp down of motor control output and subsequent vehicle performance due to the temperature of the motor controller exceeding a predefined value. ";
CM_ SG_ 2298415344 pCapacitor_Voltage "Description: Capacitor Voltage of the Electric Propulsion Control Unit or Auxiliary Power Control Unit from which the message is sent.

Could not parse SPN data type, please add:Type: Measured
Parsed from -014. ";
CM_ SG_ 2298415344 pMotor_Power_Cutback_Status "Description: Status bit indicating the ramp down of motor control output and subsequent vehicle performance due to low power availability. ";
CM_ SG_ 2298415344 pInput_Current "Description: Input DC Current of the Electric Propulsion Control Unit or Auxiliary Power Control Unit from which the message is sent.

Could not parse SPN data type, please add:Type: Measured
Parsed from -014. ";
CM_ SG_ 2298415344 pMotor_Thermal_Cutback_Status "Description: Status bit indicating the ramp down of motor control output and subsequent vehicle performance due to the temperature of the motor exceeding a predefined value. ";
CM_ SG_ 2298415344 pInput_DC_Current_Cutback_Status "Description: Status bit indicating the ramp down of motor control output and subsequent vehicle performance due to low Input Current. ";
CM_ SG_ 2298415344 pSpeed_Limit_Cutback_Status "Description: Status bit indicating the ramp down of motor control output and subsequent vehicle performance due to the motor speed exceeding the limits set for the motor.  ";
CM_ SG_ 2298415344 pPower_Message_Checksum "Description: Checksum is calculated by taking XOR of bytes from 1 to 7.
Could not parse SPN data type, please add:Type: Status
Parsed from -014. ";
CM_ BO_ 2298415601 "Name: pTemperature Message
Description: Parsed from -014. ";
CM_ SG_ 2298415601 pJunction_Temp "Description: Actual junction temperature of the Electric Propulsion Control Unit or Auxiliary Power Unit from which the message is sent

Could not parse SPN data type, please add:Type: Measured
Parsed from -014. ";
CM_ SG_ 2298415601 pCapacitor_Temp "Description: Actual capacitor temperature of the Electric Propulsion Control Unit or Auxiliary Power Unit from which the message is sent

Could not parse SPN data type, please add:Type: Measured
Parsed from -014. ";
CM_ SG_ 2298415601 pMotor_Temp_Margin "Description: The smallest difference between an internal motor component and its thermal limit for the Electric Propulsion Control Unit or Auxiliary Power Control Unit from which the message is sent

Could not parse SPN data type, pl";
CM_ SG_ 2298415601 pBaseplate_Temp "Description: Actual baseplate temperature of the Electric Propulsion Control Unit or Auxiliary Power Unit from which the message is sent

Data Length: 1 byte 
Start Position: 3.1
Type: Measured
PGN: 65289
Parsed from -014. ";
CM_ SG_ 2298415601 pBoard_Temp "Description: Board temperature of the Electric Propulsion Control Unit or Auxiliary Power Unit from which the message is sent

Could not parse SPN data type, please add:Type: Measured
Parsed from -014. ";
CM_ SG_ 2298415601 pController_Temp_Margin "Description: The smallest difference between an internal component and its thermal limit for the Electric Propulsion Control Unit or Auxiliary Power Control Unit from which the message is sent

Could not parse SPN data type, ple";
CM_ SG_ 2298415601 pTemperature_Message_Checksum "Description: Checksum is calculated by taking XOR of bytes from 1 to 7.
Could not parse SPN data type, please add:Type: Status
Parsed from -014. ";
CM_ SG_ 2298415601 pMotor_Temp "Description: Actual motor temperature of the Electric Propulsion Unit or Auxiliary Power Unit from which the message is sent

Could not parse SPN data type, please add:Type: Measured
Parsed from -014. ";
CM_ BO_ 2298415089 "Name: pPerformance Message
Description: Parsed from -014. ";
CM_ SG_ 2298415089 pPerformance_Message_Checksum "Description: Checksum is calculated by taking XOR of bytes from 1 to 7.
Could not parse SPN data type, please add:Type: Status
Parsed from -014. ";
CM_ SG_ 2298415089 pLower_Available_Torque_Limit "Description: The maximum torque available in the reverse direction. Lower available torque is normally negative but can be positive in a negative overspeed condition.

Could not parse SPN data type, please add:Type: Status";
CM_ SG_ 2298415089 pPerformance_State "Description: Bits dictating the state of the Electric Propulsion Control Unit or Auxiliary Power Unit from which the message is sent. ";
CM_ SG_ 2298415089 pActual_Motor_Torque "Description: Actual generated torque from Electronic Propulsion unit

Could not parse SPN data type, please add:Type: Status
Parsed from -014. ";
CM_ SG_ 2298415089 pUpper_Available_Torque_Limit "Description: The maximum torque available in the positive direction. Upper available torque is normally negative but can be positive in a negative overspeed condition.

Could not parse SPN data type, please add:Type: Statu";
CM_ SG_ 2298415089 pActual_Motor_Velocity "Description: Actual RPM of the Electric Propulsion Control Unit or Auxiliary Power Unit from which the message is sent.

Could not parse SPN data type, please add:Type: Measured
Parsed from -014. ";
CM_ SG_ 2298415089 pPer_Msg_Count "Description:Created due to CMS fault code using this SPN";
CM_ BO_ 2298415345 "Name: pPower Message
Description: Parsed from -014. ";
CM_ SG_ 2298415345 pController_Thermal_Cutback_Stat "Description: Status bit indicating the ramp down of motor control output and subsequent vehicle performance due to the temperature of the motor controller exceeding a predefined value. ";
CM_ SG_ 2298415345 pCapacitor_Voltage "Description: Capacitor Voltage of the Electric Propulsion Control Unit or Auxiliary Power Control Unit from which the message is sent.

Could not parse SPN data type, please add:Type: Measured
Parsed from -014. ";
CM_ SG_ 2298415345 pMotor_Power_Cutback_Status "Description: Status bit indicating the ramp down of motor control output and subsequent vehicle performance due to low power availability. ";
CM_ SG_ 2298415345 pInput_Current "Description: Input DC Current of the Electric Propulsion Control Unit or Auxiliary Power Control Unit from which the message is sent.

Could not parse SPN data type, please add:Type: Measured
Parsed from -014. ";
CM_ SG_ 2298415345 pMotor_Thermal_Cutback_Status "Description: Status bit indicating the ramp down of motor control output and subsequent vehicle performance due to the temperature of the motor exceeding a predefined value. ";
CM_ SG_ 2298415345 pInput_DC_Current_Cutback_Status "Description: Status bit indicating the ramp down of motor control output and subsequent vehicle performance due to low Input Current. ";
CM_ SG_ 2298415345 pSpeed_Limit_Cutback_Status "Description: Status bit indicating the ramp down of motor control output and subsequent vehicle performance due to the motor speed exceeding the limits set for the motor.  ";
CM_ SG_ 2298415345 pPower_Message_Checksum "Description: Checksum is calculated by taking XOR of bytes from 1 to 7.
Could not parse SPN data type, please add:Type: Status
Parsed from -014. ";
CM_ BO_ 2298415602 "Name: pTemperature Message
Description: Parsed from -014. ";
CM_ SG_ 2298415602 pJunction_Temp "Description: Actual junction temperature of the Electric Propulsion Control Unit or Auxiliary Power Unit from which the message is sent

Could not parse SPN data type, please add:Type: Measured
Parsed from -014. ";
CM_ SG_ 2298415602 pCapacitor_Temp "Description: Actual capacitor temperature of the Electric Propulsion Control Unit or Auxiliary Power Unit from which the message is sent

Could not parse SPN data type, please add:Type: Measured
Parsed from -014. ";
CM_ SG_ 2298415602 pMotor_Temp_Margin "Description: The smallest difference between an internal motor component and its thermal limit for the Electric Propulsion Control Unit or Auxiliary Power Control Unit from which the message is sent

Could not parse SPN data type, pl";
CM_ SG_ 2298415602 pBaseplate_Temp "Description: Actual baseplate temperature of the Electric Propulsion Control Unit or Auxiliary Power Unit from which the message is sent

Data Length: 1 byte 
Start Position: 3.1
Type: Measured
PGN: 65289
Parsed from -014. ";
CM_ SG_ 2298415602 pBoard_Temp "Description: Board temperature of the Electric Propulsion Control Unit or Auxiliary Power Unit from which the message is sent

Could not parse SPN data type, please add:Type: Measured
Parsed from -014. ";
CM_ SG_ 2298415602 pController_Temp_Margin "Description: The smallest difference between an internal component and its thermal limit for the Electric Propulsion Control Unit or Auxiliary Power Control Unit from which the message is sent

Could not parse SPN data type, ple";
CM_ SG_ 2298415602 pTemperature_Message_Checksum "Description: Checksum is calculated by taking XOR of bytes from 1 to 7.
Could not parse SPN data type, please add:Type: Status
Parsed from -014. ";
CM_ SG_ 2298415602 pMotor_Temp "Description: Actual motor temperature of the Electric Propulsion Unit or Auxiliary Power Unit from which the message is sent

Could not parse SPN data type, please add:Type: Measured
Parsed from -014. ";
CM_ BO_ 2298415090 "Name: pPerformance Message
Description: Parsed from -014. ";
CM_ SG_ 2298415090 pPerformance_Message_Checksum "Description: Checksum is calculated by taking XOR of bytes from 1 to 7.
Could not parse SPN data type, please add:Type: Status
Parsed from -014. ";
CM_ SG_ 2298415090 pLower_Available_Torque_Limit "Description: The maximum torque available in the reverse direction. Lower available torque is normally negative but can be positive in a negative overspeed condition.

Could not parse SPN data type, please add:Type: Status";
CM_ SG_ 2298415090 pPerformance_State "Description: Bits dictating the state of the Electric Propulsion Control Unit or Auxiliary Power Unit from which the message is sent. ";
CM_ SG_ 2298415090 pActual_Motor_Torque "Description: Actual generated torque from Electronic Propulsion unit

Could not parse SPN data type, please add:Type: Status
Parsed from -014. ";
CM_ SG_ 2298415090 pUpper_Available_Torque_Limit "Description: The maximum torque available in the positive direction. Upper available torque is normally negative but can be positive in a negative overspeed condition.

Could not parse SPN data type, please add:Type: Statu";
CM_ SG_ 2298415090 pActual_Motor_Velocity "Description: Actual RPM of the Electric Propulsion Control Unit or Auxiliary Power Unit from which the message is sent.

Could not parse SPN data type, please add:Type: Measured
Parsed from -014. ";
CM_ SG_ 2298415090 pPer_Msg_Count "Description:Created due to CMS fault code using this SPN";
CM_ BO_ 2298415346 "Name: pPower Message
Description: Parsed from -014. ";
CM_ SG_ 2298415346 pController_Thermal_Cutback_Stat "Description: Status bit indicating the ramp down of motor control output and subsequent vehicle performance due to the temperature of the motor controller exceeding a predefined value. ";
CM_ SG_ 2298415346 pCapacitor_Voltage "Description: Capacitor Voltage of the Electric Propulsion Control Unit or Auxiliary Power Control Unit from which the message is sent.

Could not parse SPN data type, please add:Type: Measured
Parsed from -014. ";
CM_ SG_ 2298415346 pMotor_Power_Cutback_Status "Description: Status bit indicating the ramp down of motor control output and subsequent vehicle performance due to low power availability. ";
CM_ SG_ 2298415346 pInput_Current "Description: Input DC Current of the Electric Propulsion Control Unit or Auxiliary Power Control Unit from which the message is sent.

Could not parse SPN data type, please add:Type: Measured
Parsed from -014. ";
CM_ SG_ 2298415346 pMotor_Thermal_Cutback_Status "Description: Status bit indicating the ramp down of motor control output and subsequent vehicle performance due to the temperature of the motor exceeding a predefined value. ";
CM_ SG_ 2298415346 pInput_DC_Current_Cutback_Status "Description: Status bit indicating the ramp down of motor control output and subsequent vehicle performance due to low Input Current. ";
CM_ SG_ 2298415346 pSpeed_Limit_Cutback_Status "Description: Status bit indicating the ramp down of motor control output and subsequent vehicle performance due to the motor speed exceeding the limits set for the motor.  ";
CM_ SG_ 2298415346 pPower_Message_Checksum "Description: Checksum is calculated by taking XOR of bytes from 1 to 7.
Could not parse SPN data type, please add:Type: Status
Parsed from -014. ";
CM_ BO_ 2297441779 "Name: Acceleration Sensor
Description: The acceleration sensor message shall provide a measurement of the vehicle�s acceleration in the lateral, longitudinal, and vertical axes. The vehicle dynamics and measurements in this message shall be according to";
CM_ SG_ 2297441779 Vertical_Acceleration_Figure_of_ "Description:Figure of merit for vertical acceleration measurement. 00b = vertical acceleration is fully functional. Data is within sensor specification 01b = verticalacceleration is degraded. Data is suspect due to enviro";
CM_ SG_ 2297441779 Lateral_Acceleration_Figure_of_M "Description:Figure of merit for lateral acceleration measurement. 00b = lateral acceleration is fully functional. Data is within sensor specification 01b = lateral acceleration is degraded. Data is suspect due to envirome";
CM_ SG_ 2297441779 Longitudinal_Acceleration_Extend "Description:Indicates longitudinal acceleration of the vehicle (the component of vehicle acceleration vector along the X-axis). A positive longitudinal acceleration signal results when the vehicle speed increases in the f";
CM_ SG_ 2297441779 Lateral_Acceleration_Extended_Ra "Description:Indicates lateral acceleration of the vehicle (the component of vehicle acceleration vector along the Y-axis). A positive lateral acceleration signal results when the vehicle is accelerated to the left. This p";
CM_ SG_ 2297441779 Longitudinal_Acceleration_Figure "Description:Figure of merit for longitudinal acceleration measurement. 00b = longitudinal acceleration is fully functional. Data is within sensor specification 01b = longitudinal acceleration is degraded. Data is suspect ";
CM_ SG_ 2297441779 Vertical_Acceleration_Extended_R "Description:Indicates vertical acceleration of the vehicle and the effect of gravity (the component of vehicle acceleration vector along the Z-axis). A positive vertical acceleration signal of 1 gravity results when the v";
CM_ SG_ 2297441779 Support_Variable_Transmission_Re "Description:Indicates which acceleration transmission rate are supported by the ECU in addition to the required 10 ms transmission rate. 00 = Reserve for SAE assignment 01 = Reserved for SAE assignment 10 to 20 = ms rate ";
CM_ BO_ 2365525747 "Name: pBMC Power Message
Description: Parsed from -014. ";
CM_ SG_ 2365525747 pPack_Voltage "Description: The voltage of the battery pack monitored by the Battery Management Controller (BMC).

Could not parse SPN data type, please add:Type: Measured
Parsed from -014. ";
CM_ SG_ 2365525747 pDischarge_Limit "Description: The discharge limit of the battery pack monitored by the Battery Management Controller (BMC).

Could not parse SPN data type, please add:Type: Status
Parsed from -014. ";
CM_ SG_ 2365525747 pPack_Current "Description: The current of the battery pack monitored by the Battery Management Controller (BMC).

Could not parse SPN data type, please add:Type: Measured
Parsed from -014. ";
CM_ SG_ 2365525747 pBMC_Power_Message_Checksum "Description: Checksum is calculated by taking XOR of bytes from 1 to 7.
Could not parse SPN data type, please add:Type: Status
Parsed from -014. ";
CM_ SG_ 2365525747 pCharge_Limit "Description: The Charge limit of the battery pack monitored by the Battery Management Controller (BMC).

Could not parse SPN data type, please add:Type: Status
Parsed from -014. ";
CM_ BO_ 2365526515 "Name: pBMC Status Message
Description: Parsed from -014. ";
CM_ SG_ 2365526515 pBMC_Temp "Description: The temperature of the Battery Management Controller (BMC).

Could not parse SPN data type, please add:Type: Measured
Parsed from -014. ";
CM_ SG_ 2365526515 pDCDC_State "Description: Operating state of the DC-DC converter controlled by the Battery Management Controller (BMC).  ";
CM_ SG_ 2365526515 pBattery_Type "Description: Type of traction battery pack installed on the vehicle
Type defined as follows:
Flooded Lead Acid 12V:       04h
Flooded Lead Acid 6V:         06h 
AGM Lead Acid 12V:           44h
AGM Lead Acid 6V:             46h
Li-Ion";
CM_ SG_ 2365526515 pBalance_Error "Description: The error in state of charge existing between the bottom battery and the top battery balanced by the Battery Management Controller (BMC). Positive error corresponds to the lower battery being at a higher state of charge.

Co";
CM_ SG_ 2365526515 pKEY_State "Description: State signifying the presence of an activated Key switch.  ";
CM_ SG_ 2365526515 pBMC_Status_Counter "Description: Counter to verify latest message, counts 0-15

Could not parse SPN data type, please add:Type: Measured
Parsed from -014. ";
CM_ SG_ 2365526515 pBalance_State "Description: The state of the BMC in terms of balancing the state of charge of the bottom battery and the top battery.  ";
CM_ SG_ 2365526515 pWAKE_State "Description: The state of the BMC&rsquo;s WAKE input.  ";
CM_ SG_ 2365526515 pBMC_Status_Message_Checksum "Description: Checksum is calculated by taking XOR of bytes from 1 to 7.
Could not parse SPN data type, please add:Type: Status
Parsed from -014. ";
CM_ BO_ 2365526003 "Name: pEnergy Message
Description: Parsed from -014. ";
CM_ SG_ 2365526003 pSOC "Description: The State of Charge (SOC) &ndash; percent of battery capacity available at current battery health and temperature &ndash; of the battery pack monitored by the Battery Management Controller (BMC).

Could not parse SPN data type, please";
CM_ SG_ 2365526003 pAvailable_Wh "Description: The capacity, in Watt hours, of the battery pack monitored by the Battery Management Controller (BMC).

Could not parse SPN data type, please add:Type: Status
Parsed from -014. ";
CM_ SG_ 2365526003 pWh_in_Since_key_on "Description: The capacity in Watt hours delivered to the battery pack monitored by the Battery Management Controller (BMC), negative for net energy removed from the battery pack.

Could not parse SPN data type, please add:Type: Meas";
CM_ SG_ 2365526003 pEnergy_Message_Checksum "Description: Checksum is calculated by taking XOR of bytes from 1 to 7.
Could not parse SPN data type, please add:Type: Status
Parsed from -014. ";
BA_DEF_ SG_  "SigType" ENUM  "Default","Range","RangeSigned","ASCII","Discrete","Control","ReferencePGN","DTC","StringDelimiter","StringLength","StringLengthControl";
BA_DEF_ SG_  "GenSigEVName" STRING ;
BA_DEF_ SG_  "GenSigILSupport" ENUM  "No","Yes";
BA_DEF_ SG_  "GenSigSendType" ENUM  "Cyclic","OnWrite","OnWriteWithRepetition","OnChange","OnChangeWithRepetition","IfActive","IfActiveWithRepetition","NoSigSendType";
BA_DEF_ BO_  "GenMsgCycleTimeFast" INT 0 3600000;
BA_DEF_ BO_  "GenMsgILSupport" ENUM  "No","Yes";
BA_DEF_ BO_  "GenMsgSendType" ENUM  "cyclic","spontaneous","cyclicIfActive","spontaneousWithDelay","cyclicAndSpontaneous","cyclicAndSpontaneousWithDelay","spontaneousWithRepetition","cyclicIfActiveAndSpontaneousWD","OnRequest";
BA_DEF_ BO_  "GenMsgRequestable" INT 0 1;
BA_DEF_ BO_  "GenMsgCycleTime" INT 0 3600000;
BA_DEF_ SG_  "SPN" INT 0 524287;
BA_DEF_ BO_  "VFrameFormat" ENUM  "StandardCAN","ExtendedCAN","reserved","J1939PG";
BA_DEF_DEF_  "SigType" "Default";
BA_DEF_DEF_  "GenSigEVName" "Env@Nodename_@Signame";
BA_DEF_DEF_  "GenSigILSupport" "Yes";
BA_DEF_DEF_  "GenSigSendType" "NoSigSendType";
BA_DEF_DEF_  "GenMsgCycleTimeFast" 0;
BA_DEF_DEF_  "GenMsgILSupport" "Yes";
BA_DEF_DEF_  "GenMsgSendType" "noMsgSendType";
BA_DEF_DEF_  "GenMsgRequestable" 1;
BA_DEF_DEF_  "GenMsgCycleTime" 0;
BA_DEF_DEF_  "SPN" 0;
BA_DEF_DEF_  "VFrameFormat" "J1939PG";
BA_ "SPN" SG_ 2566878847 pDevice_1_Battery_Strength 524125;
BA_ "SPN" SG_ 2566878847 pDevice_2_Bluetooth_Connection_S 524129;
BA_ "SPN" SG_ 2566878847 pDevice_2_Device_Battery_Strengt 524128;
BA_ "SPN" SG_ 2566878847 pDevice_2_Cell_Signal_Strength 524127;
BA_ "SPN" SG_ 2566878847 pDevice_Headset_1_Connection_Sta 524130;
BA_ "SPN" SG_ 2566878847 pDevice_1_Bluetooth_Connection_S 524126;
BA_ "SPN" SG_ 2566878847 pDevice_1_Cell_Signal_Strength 524124;
BA_ "SPN" SG_ 2566878847 pDevice_Headset_2_Connection_Sta 524131;
BA_ "SPN" SG_ 2566834815 Flash_Malfunction_Indicator_Lamp 3038;
BA_ "SPN" SG_ 2566834815 Malfunction_Indicator_Lamp_Statu 1213;
BA_ "SPN" SG_ 2566834815 Red_Stop_Lamp_Status 623;
BA_ "SPN" SG_ 2566834815 Amber_Warning_Lamp_Status 624;
BA_ "SPN" SG_ 2566834815 Flash_Red_Stop_Lamp_RSL 3039;
BA_ "SPN" SG_ 2566834815 Flash_Amber_Warning_Lamp_AWL 3040;
BA_ "SPN" SG_ 2566834815 Flash_Protect_Lamp 3041;
BA_ "SPN" SG_ 2566834815 Protect_Lamp_Status 987;
BA_ "SPN" SG_ 2566834815 DTC_1 999990;
BA_ "SPN" SG_ 2566834815 DTC_2 999991;
BA_ "SPN" SG_ 2566834815 DTC_3 999992;
BA_ "SPN" SG_ 2566834815 DTC_4 999993;
BA_ "SPN" SG_ 2566834815 DTC_5 999994;
BA_ "SPN" SG_ 2566834815 DTC_6 999995;
BA_ "SPN" SG_ 2566834815 DTC_7 999996;
BA_ "SPN" SG_ 2566834815 DTC_8 999997;
BA_ "SPN" SG_ 2566834815 DTC_9 999998;
BA_ "SPN" SG_ 2566834815 DTC_10 999999;
BA_ "SPN" SG_ 2566842495 Compass_Bearing 165;
BA_ "SPN" SG_ 2561212287 Text_Display_Character 3615;
BA_ "SPN" SG_ 2561212287 Text_Display_Index 3614;
BA_ "SPN" SG_ 2561212287 Text_Display_Instructions 3613;
BA_ "SPN" SG_ 2365531268 pEPSReqMod 516147;
BA_ "SPN" SG_ 2365554944 pOperator_Switch_Status_3 523964;
BA_ "SPN" SG_ 2365554944 pUpPaddleStatus 520405;
BA_ "SPN" SG_ 2365554944 pOperator_Switch_Status_2 523963;
BA_ "SPN" SG_ 2365554944 pDwPaddleStatus 520406;
BA_ "SPN" SG_ 2365554944 pOperator_Button_50_Pucker 523962;
BA_ "SPN" SG_ 2566834823 Flash_Malfunction_Indicator_Lamp 3038;
BA_ "SPN" SG_ 2566834823 Malfunction_Indicator_Lamp_Statu 1213;
BA_ "SPN" SG_ 2566834823 Red_Stop_Lamp_Status 623;
BA_ "SPN" SG_ 2566834823 Amber_Warning_Lamp_Status 624;
BA_ "SPN" SG_ 2566834823 Flash_Red_Stop_Lamp_RSL 3039;
BA_ "SPN" SG_ 2566834823 Flash_Amber_Warning_Lamp_AWL 3040;
BA_ "SPN" SG_ 2566834823 Flash_Protect_Lamp 3041;
BA_ "SPN" SG_ 2566834823 Protect_Lamp_Status 987;
BA_ "SPN" SG_ 2566834823 DTC_1 999990;
BA_ "SPN" SG_ 2566834823 DTC_2 999991;
BA_ "SPN" SG_ 2566834823 DTC_3 999992;
BA_ "SPN" SG_ 2566834823 DTC_4 999993;
BA_ "SPN" SG_ 2566834823 DTC_5 999994;
BA_ "SPN" SG_ 2566834823 DTC_6 999995;
BA_ "SPN" SG_ 2566834823 DTC_7 999996;
BA_ "SPN" SG_ 2566834823 DTC_8 999997;
BA_ "SPN" SG_ 2566834823 DTC_9 999998;
BA_ "SPN" SG_ 2566834823 DTC_10 999999;
BA_ "SPN" SG_ 2432656519 Source 524027;
BA_ "SPN" SG_ 2432656519 Squelch_SQ_Up 524022;
BA_ "SPN" SG_ 2432656519 MutePreset 524026;
BA_ "SPN" SG_ 2432656519 Volume_Down 524031;
BA_ "SPN" SG_ 2432656519 Volume_Up 524030;
BA_ "SPN" SG_ 2432656519 Tune_Up 524028;
BA_ "SPN" SG_ 2432656519 Seek_Up 516341;
BA_ "SPN" SG_ 2432656519 Tune_Down 524029;
BA_ "SPN" SG_ 2432656519 Squelch_SQ_Down 524023;
BA_ "SPN" SG_ 2432656519 pInfotainment_Joystick_1 520363;
BA_ "SPN" SG_ 2432656519 Preset 524020;
BA_ "SPN" SG_ 2432656519 Seek_Down 516342;
BA_ "SPN" SG_ 2432656519 pInfotainment_Joystick_2 520364;
BA_ "SPN" SG_ 2432656519 ICOM 524025;
BA_ "SPN" SG_ 2432656519 Push_To_Talk_PTT 524021;
BA_ "SPN" SG_ 2432656519 pMultifunction_Infotainment_Inte 520380;
BA_ "SPN" SG_ 2432656519 COM 524024;
BA_ "SPN" SG_ 2432656519 PlayPause 516340;
BA_ "SPN" SG_ 2566860167 pSpecial_Msg_12 516427;
BA_ "SPN" SG_ 2566860167 pSpecial_Msg_28 516373;
BA_ "SPN" SG_ 2566860167 pSpecial_Msg_11 516393;
BA_ "SPN" SG_ 2566860167 pSpecial_Msg_26 516465;
BA_ "SPN" SG_ 2566860167 pSpecial_Msg_24 516463;
BA_ "SPN" SG_ 2566860167 pSpecial_Msg_21 516444;
BA_ "SPN" SG_ 2566860167 pSpecial_Msg_18 516376;
BA_ "SPN" SG_ 2566860167 pSpecial_Msg_19 516442;
BA_ "SPN" SG_ 2566860167 pSpecial_Msg_1_Riding_with_Brake 516382;
BA_ "SPN" SG_ 2566860167 pSpecial_Msg_2_Regulator_Overhea 516384;
BA_ "SPN" SG_ 2566860167 pSpecial_Msg_3_Regulator_Overhea 516385;
BA_ "SPN" SG_ 2566860167 pSpecial_Msg_4_Regulator_Overhea 516386;
BA_ "SPN" SG_ 2566860167 pSpecial_Msg_5_Engine_Warmup_Com 516387;
BA_ "SPN" SG_ 2566860167 pSpecial_Msg_6_Engine_Knock__Mod 516388;
BA_ "SPN" SG_ 2566860167 pSpecial_Msg_8_Low_Coolant_Warni 516390;
BA_ "SPN" SG_ 2566860167 pSpecial_Msg_7_Engine_Knock__Mos 516389;
BA_ "SPN" SG_ 2566860167 pSpecial_Msg_9_Transmission_Temp 516391;
BA_ "SPN" SG_ 2566860167 pSpecial_Msg_10_Reverse_Speed_Li 516392;
BA_ "SPN" SG_ 2566860167 pSpecial_Msg_13_Belt_Burn_Warnin 516381;
BA_ "SPN" SG_ 2566860167 pSpecial_Msg_14_Park_Brake_Warni 516380;
BA_ "SPN" SG_ 2566860167 pSpecial_Msg_15_TCM_Comm_Loss 516379;
BA_ "SPN" SG_ 2566860167 pSpecial_Msg_16_TCM_Pump_Priming 516378;
BA_ "SPN" SG_ 2566860167 pSpecial_Msg_17_Request_User_to_ 516377;
BA_ "SPN" SG_ 2566860167 pSpecial_MSG_20_Fuel_Door_Open_E 516443;
BA_ "SPN" SG_ 2566860167 pSpecial_MSG_22_Clutch_Overtemp 516383;
BA_ "SPN" SG_ 2566860167 pSpecial_MSG_23_Exhaust_Valve_Ch 516375;
BA_ "SPN" SG_ 2566860167 pSpecial_MSG_25_Engine_Idle_Shut 516464;
BA_ "SPN" SG_ 2566860167 pSpecial_MSG_27_Overboost_Condit 516374;
BA_ "SPN" SG_ 2566860167 pSpecial_Msg_31_Engine_Tip_Over_ 516372;
BA_ "SPN" SG_ 2566860167 pSpecial_Msg_32_Engine_Tip_Over_ 516394;
BA_ "SPN" SG_ 2365555079 pOperator_Switch_Status_3 523964;
BA_ "SPN" SG_ 2365555079 pUpPaddleStatus 520405;
BA_ "SPN" SG_ 2365555079 pOperator_Switch_Status_2 523963;
BA_ "SPN" SG_ 2365555079 pDwPaddleStatus 520406;
BA_ "SPN" SG_ 2365555079 pOperator_Button_50_Pucker 523962;
BA_ "SPN" SG_ 2566896007 pSetpoint_Grips_Hand_Medium 516352;
BA_ "SPN" SG_ 2566896007 pSetpoint_Grips_Hand_Low 516353;
BA_ "SPN" SG_ 2566896007 pSetpoint_Grip_Thumb_Medium 516355;
BA_ "SPN" SG_ 2566896007 pAccessory_Control_Operation 516349;
BA_ "SPN" SG_ 2566896007 pSetpoint_Grips_Hand_High 516351;
BA_ "SPN" SG_ 2566896007 pAccessory_Control_Mode 516350;
BA_ "SPN" SG_ 2566896007 pSetpoint_Grip_Thumb_High 516354;
BA_ "SPN" SG_ 2566896007 pSetpoint_Grip_Thumb_Low 516356;
BA_ "SPN" SG_ 2566844807 Cruise_Control_Set_Speed 86;
BA_ "SPN" SG_ 2566844807 Cruise_Control_Active 595;
BA_ "SPN" SG_ 2566844807 Clutch_Switch 598;
BA_ "SPN" SG_ 2566844807 Brake_Switch 597;
BA_ "SPN" SG_ 2566844807 pCC_Message_Counter 524080;
BA_ "SPN" SG_ 2566844807 Cruise_Control_Pause_Switch 1633;
BA_ "SPN" SG_ 2566844807 Cruise_Control_Set_Switch 599;
BA_ "SPN" SG_ 2566844807 Two_Speed_Axle_Switch 69;
BA_ "SPN" SG_ 2566844807 Cruise_Control_Enable_Switch 596;
BA_ "SPN" SG_ 2566844807 pOdometer_Drive_Bit 523994;
BA_ "SPN" SG_ 2566844807 pCC_Checksum 524079;
BA_ "SPN" SG_ 2566844807 WheelBased_Vehicle_Speed 84;
BA_ "SPN" SG_ 2566844807 Cruise_Control_Resume_Switch 601;
BA_ "SPN" SG_ 2566844807 Cruise_Control_Accelerate_Switch 602;
BA_ "SPN" SG_ 2566844807 pCruise_Enable_Status 524108;
BA_ "SPN" SG_ 2566844807 Parking_Brake_Switch 70;
BA_ "SPN" SG_ 2566844807 Cruise_Control_Coast_Decelerate_ 600;
BA_ "SPN" SG_ 2566835079 Protect_Lamp_Status 987;
BA_ "SPN" SG_ 2566835079 Amber_Warning_Lamp_Status 624;
BA_ "SPN" SG_ 2566835079 Red_Stop_Lamp_Status 623;
BA_ "SPN" SG_ 2566835079 Malfunction_Indicator_Lamp_Statu 1213;
BA_ "SPN" SG_ 2566835079 Flash_Protect_Lamp 3041;
BA_ "SPN" SG_ 2566835079 Flash_Amber_Warning_Lamp_AWL 3040;
BA_ "SPN" SG_ 2566835079 Flash_Red_Stop_Lamp_RSL 3039;
BA_ "SPN" SG_ 2566835079 Flash_Malfunction_Indicator_Lamp 3038;
BA_ "SPN" SG_ 2566835079 DTC_1 999990;
BA_ "SPN" SG_ 2566835079 DTC_2 999991;
BA_ "SPN" SG_ 2566835079 DTC_3 999992;
BA_ "SPN" SG_ 2566835079 DTC_4 999993;
BA_ "SPN" SG_ 2566835079 DTC_5 999994;
BA_ "SPN" SG_ 2566835079 DTC_6 999995;
BA_ "SPN" SG_ 2566835079 DTC_7 999996;
BA_ "SPN" SG_ 2566835079 DTC_8 999997;
BA_ "SPN" SG_ 2566835079 DTC_9 999998;
BA_ "SPN" SG_ 2566835079 DTC_10 999999;
BA_ "SPN" SG_ 2432656775 Key_Fob_Unlock_Button_Status 524044;
BA_ "SPN" SG_ 2432656775 Homelink_2 524037;
BA_ "SPN" SG_ 2432656775 Side_Stand_Switch 524098;
BA_ "SPN" SG_ 2432656775 Key_Fob_Lock_Button_Status 524043;
BA_ "SPN" SG_ 2432656775 Windshield__2_Down 524034;
BA_ "SPN" SG_ 2432656775 Turn__3_Cancel 524052;
BA_ "SPN" SG_ 2432656775 Reverse 524039;
BA_ "SPN" SG_ 2432656775 Hazard 524051;
BA_ "SPN" SG_ 2432656775 Homelink_1 524038;
BA_ "SPN" SG_ 2432656775 Windshield__1_Up 524035;
BA_ "SPN" SG_ 2432656775 Front_Brake_Switch 520322;
BA_ "SPN" SG_ 2432656775 Instrument_Cluster_Control__2 524058;
BA_ "SPN" SG_ 2432656775 Chassis_Unlock_Button_Status 524042;
BA_ "SPN" SG_ 2432656775 Power_Button 520362;
BA_ "SPN" SG_ 2432656775 RunStop_Switch 524040;
BA_ "SPN" SG_ 2432656775 Headlamp__2_High 524056;
BA_ "SPN" SG_ 2432656775 Instrument_Cluster_Control__1 524059;
BA_ "SPN" SG_ 2432656775 Clutch_Switch 524032;
BA_ "SPN" SG_ 2432656775 Start 524046;
BA_ "SPN" SG_ 2432656775 Headlamp__3_Driving 524055;
BA_ "SPN" SG_ 2432656775 Cruise__2_Set 524049;
BA_ "SPN" SG_ 2432656775 Windshield_Wiper 524041;
BA_ "SPN" SG_ 2432656775 Fog 524045;
BA_ "SPN" SG_ 2432656775 Cruise__3_Accel 524048;
BA_ "SPN" SG_ 2432656775 Horn 524047;
BA_ "SPN" SG_ 2432656775 Turn__2_Right 524053;
BA_ "SPN" SG_ 2432656775 Cruise__1_On 524050;
BA_ "SPN" SG_ 2432656775 Turn__1_Left 524054;
BA_ "SPN" SG_ 2432656775 Throttle_Safety_Switch__1 524036;
BA_ "SPN" SG_ 2432656775 Headlamp__1_Low 524057;
BA_ "SPN" SG_ 2432656775 Chassis_Lock_Switch_Status 516131;
BA_ "SPN" SG_ 2432656775 Fuel_Door_Unlock_Button_Status 516191;
BA_ "SPN" SG_ 2566896519 pMeasured_Voltage_2_Right_Grip 516364;
BA_ "SPN" SG_ 2566896519 pMeasured_Current_1_Left_Grip 516366;
BA_ "SPN" SG_ 2566896519 pMeasured_Current_3_Thumb 516368;
BA_ "SPN" SG_ 2566896519 pMeasured_Voltage_1_Left_Grip 516363;
BA_ "SPN" SG_ 2566896519 pMeasured_Voltage_3_Thumb 516365;
BA_ "SPN" SG_ 2566896519 pMeasured_Current_2_Right_Grip 516367;
BA_ "SPN" SG_ 2633984647 pHeated_Grip_Enable 520366;
BA_ "SPN" SG_ 2633984647 pUser_PIN_Access_Status 516128;
BA_ "SPN" SG_ 2633984647 pActive_Descent_Control_ADC_Stat 524013;
BA_ "SPN" SG_ 2633984647 pCruise_Control_Set_Status 524097;
BA_ "SPN" SG_ 2633984647 pTether_Switch_Status 520600;
BA_ "SPN" SG_ 2633984647 pHigh_Beam_Indicator_Status 524084;
BA_ "SPN" SG_ 2633984647 pLow_Fuel_Indicator_Status 524087;
BA_ "SPN" SG_ 2633984647 pHeated_Grips_Percentage 524096;
BA_ "SPN" SG_ 2633984647 pSide_Stand_Status 524270;
BA_ "SPN" SG_ 2633984647 pTurf_Mode_Requested 524136;
BA_ "SPN" SG_ 2633984647 pEngine_Idle_Shutdown_Timer 516223;
BA_ "SPN" SG_ 2633984647 Operator_Not_in_Operating_Statio 520247;
BA_ "SPN" SG_ 2633984647 pAWD_Mode_Requested 524138;
BA_ "SPN" SG_ 2633984647 pHeated_Grips_Up_Switch_Status 516129;
BA_ "SPN" SG_ 2633984647 pTreadle_Neutral_Status 524017;
BA_ "SPN" SG_ 2633984647 pHeated_Grips_Down_Switch_Status 516130;
BA_ "SPN" SG_ 2633984647 pPark_Brake_Indicator_Status 524271;
BA_ "SPN" SG_ 2633984647 pRWD_Mode_Requested 524137;
BA_ "SPN" SG_ 2633984647 pSeat_Belt_Indicator_Status 524092;
BA_ "SPN" SG_ 2633984647 pSecurity_Light_Immobilizer_Stat 524019;
BA_ "SPN" SG_ 2633984647 ECU_Security_Status 516202;
BA_ "SPN" SG_ 2633984647 pActive_Decent_Control_ADC_Mode_ 524139;
BA_ "SPN" SG_ 2633984647 pTreadle_Reverse_Status 524018;
BA_ "SPN" SG_ 2566877831 pRight_Hand_Grip_Temperature 524110;
BA_ "SPN" SG_ 2566877831 pDriver_Seat_Temperature 516453;
BA_ "SPN" SG_ 2566877831 pPassenger_Seat_Temperature 516454;
BA_ "SPN" SG_ 2566877831 pLeft_Hand_Grip_Temperature 524109;
BA_ "SPN" SG_ 2566896263 pGrips_Duty_Cycle_Right_Hand 516358;
BA_ "SPN" SG_ 2566896263 pGrips_Temperature_Right_Hand 516361;
BA_ "SPN" SG_ 2566896263 pGrips_Temperature_Left_Hand 516360;
BA_ "SPN" SG_ 2566896263 pGrips_Temperature_Thumb 516362;
BA_ "SPN" SG_ 2566896263 pGrips_Duty_Cycle_Thumb 516359;
BA_ "SPN" SG_ 2566896263 pGrips_Duty_Cycle_Left_Hand 516357;
BA_ "SPN" SG_ 2365523591 pModule_Control_Applied_State 516096;
BA_ "SPN" SG_ 2365523591 pModule_Control_Command_Destinat 524185;
BA_ "SPN" SG_ 2365523591 pModule_Control_Command_State 524248;
BA_ "SPN" SG_ 2365523591 pModule_Control_Message_Checksum 516097;
BA_ "SPN" SG_ 2566878092 pEPS_Commanded_Var2 524113;
BA_ "SPN" SG_ 2566878092 pEPS_Commanded_Control_Mode 524111;
BA_ "SPN" SG_ 2566878092 pEPS_Commanded_Var1 524112;
BA_ "SPN" SG_ 2231334284 Normalized_Accelerator_Position_ 520354;
BA_ "SPN" SG_ 2231334284 Operation_Mode_Status 524120;
BA_ "SPN" SG_ 2231334284 StartStop_Vehicle_Command 520497;
BA_ "SPN" SG_ 2231334284 Message_Counter 524122;
BA_ "SPN" SG_ 2231334284 Checksum 524123;
BA_ "SPN" SG_ 2231313804 Radio_System_Status 516169;
BA_ "SPN" SG_ 2231313804 IOP_Discovery_Status 516170;
BA_ "SPN" SG_ 2231313804 IOP_Authentication_Status 516171;
BA_ "SPN" SG_ 2231313804 Remote_Control_System_Status 516172;
BA_ "SPN" SG_ 2231313804 Remote_EStop_Status 516173;
BA_ "SPN" SG_ 2231313804 Network_signal_strength 516177;
BA_ "SPN" SG_ 2231336332 pActual_Braking_Application 520401;
BA_ "SPN" SG_ 2231336332 pEBC_Mode_Status 516426;
BA_ "SPN" SG_ 2231336332 Message_Counter 520402;
BA_ "SPN" SG_ 2231336332 Message_Checksum 520403;
BA_ "SPN" SG_ 2365531276 pEPSReqMod 516147;
BA_ "SPN" SG_ 2365536141 pAcceleration_Sensor_Signal_2 516417;
BA_ "SPN" SG_ 2365536141 pIMU3_Checksum 516420;
BA_ "SPN" SG_ 2365536141 pIMU3_Rolling_Counter 516418;
BA_ "SPN" SG_ 2365536141 pAngular_Rate_Signal_3_Status 516416;
BA_ "SPN" SG_ 2365536141 pAcceleration_Sensor_Signal_2_St 516419;
BA_ "SPN" SG_ 2365536141 pAngular_Rate_Signal_3 516415;
BA_ "SPN" SG_ 2365536653 pAngular_Rate_Signal_1_Status 516403;
BA_ "SPN" SG_ 2365536653 pAngular_Rate_Signal_1 516401;
BA_ "SPN" SG_ 2365536653 pIMU_Address_Information 516402;
BA_ "SPN" SG_ 2365536653 pIMU_Information_Content 516404;
BA_ "SPN" SG_ 2365536653 pAcceleration_Sensor_Signal_1 516405;
BA_ "SPN" SG_ 2365536653 pAcceleration_Sensor_Signal_1_St 516421;
BA_ "SPN" SG_ 2365536653 pIMU1_Rolling_Counter 516406;
BA_ "SPN" SG_ 2365536653 pIMU1_Checksum 516407;
BA_ "SPN" SG_ 2365536397 IMU_HW_Index 516409;
BA_ "SPN" SG_ 2365536397 pAcceleration_Sensor_Signal_3 516411;
BA_ "SPN" SG_ 2365536397 pAcceleration_Sensor_Signal_3_St 516413;
BA_ "SPN" SG_ 2365536397 pIMU2_Checksum 516414;
BA_ "SPN" SG_ 2365536397 pAngular_Rate_Signal_2 516408;
BA_ "SPN" SG_ 2365536397 pAngular_Rate_Signal_2_Status 516410;
BA_ "SPN" SG_ 2365536397 pIMU2_Rolling_Counter 516412;
BA_ "SPN" SG_ 2432656784 Key_Fob_Unlock_Button_Status 524044;
BA_ "SPN" SG_ 2432656784 Homelink_2 524037;
BA_ "SPN" SG_ 2432656784 Side_Stand_Switch 524098;
BA_ "SPN" SG_ 2432656784 Key_Fob_Lock_Button_Status 524043;
BA_ "SPN" SG_ 2432656784 Windshield__2_Down 524034;
BA_ "SPN" SG_ 2432656784 Turn__3_Cancel 524052;
BA_ "SPN" SG_ 2432656784 Reverse 524039;
BA_ "SPN" SG_ 2432656784 Hazard 524051;
BA_ "SPN" SG_ 2432656784 Homelink_1 524038;
BA_ "SPN" SG_ 2432656784 Windshield__1_Up 524035;
BA_ "SPN" SG_ 2432656784 Front_Brake_Switch 520322;
BA_ "SPN" SG_ 2432656784 Instrument_Cluster_Control__2 524058;
BA_ "SPN" SG_ 2432656784 Chassis_Unlock_Button_Status 524042;
BA_ "SPN" SG_ 2432656784 Power_Button 520362;
BA_ "SPN" SG_ 2432656784 RunStop_Switch 524040;
BA_ "SPN" SG_ 2432656784 Headlamp__2_High 524056;
BA_ "SPN" SG_ 2432656784 Instrument_Cluster_Control__1 524059;
BA_ "SPN" SG_ 2432656784 Clutch_Switch 524032;
BA_ "SPN" SG_ 2432656784 Start 524046;
BA_ "SPN" SG_ 2432656784 Headlamp__3_Driving 524055;
BA_ "SPN" SG_ 2432656784 Cruise__2_Set 524049;
BA_ "SPN" SG_ 2432656784 Windshield_Wiper 524041;
BA_ "SPN" SG_ 2432656784 Fog 524045;
BA_ "SPN" SG_ 2432656784 Cruise__3_Accel 524048;
BA_ "SPN" SG_ 2432656784 Horn 524047;
BA_ "SPN" SG_ 2432656784 Turn__2_Right 524053;
BA_ "SPN" SG_ 2432656784 Cruise__1_On 524050;
BA_ "SPN" SG_ 2432656784 Turn__1_Left 524054;
BA_ "SPN" SG_ 2432656784 Throttle_Safety_Switch__1 524036;
BA_ "SPN" SG_ 2432656784 Headlamp__1_Low 524057;
BA_ "SPN" SG_ 2432656784 Chassis_Lock_Switch_Status 516131;
BA_ "SPN" SG_ 2432656784 Fuel_Door_Unlock_Button_Status 516191;
BA_ "SPN" SG_ 2365473169 Left_Turn_Signal_Lights_Command 2367;
BA_ "SPN" SG_ 2365473169 Alternate_Beam_Head_Light_Comman 2351;
BA_ "SPN" SG_ 2365473169 Right_Turn_Signal_Lights_Command 2369;
BA_ "SPN" SG_ 2365473169 Running_Light_Command 2403;
BA_ "SPN" SG_ 2563833767 Illumination_Brightness_Percent 1487;
BA_ "SPN" SG_ 2566847655 Fuel_Level_1 96;
BA_ "SPN" SG_ 2566834855 Flash_Malfunction_Indicator_Lamp 3038;
BA_ "SPN" SG_ 2566834855 Malfunction_Indicator_Lamp_Statu 1213;
BA_ "SPN" SG_ 2566834855 Red_Stop_Lamp_Status 623;
BA_ "SPN" SG_ 2566834855 Amber_Warning_Lamp_Status 624;
BA_ "SPN" SG_ 2566834855 Flash_Red_Stop_Lamp_RSL 3039;
BA_ "SPN" SG_ 2566834855 Flash_Amber_Warning_Lamp_AWL 3040;
BA_ "SPN" SG_ 2566834855 Flash_Protect_Lamp 3041;
BA_ "SPN" SG_ 2566834855 Protect_Lamp_Status 987;
BA_ "SPN" SG_ 2566834855 DTC_1 999990;
BA_ "SPN" SG_ 2566834855 DTC_2 999991;
BA_ "SPN" SG_ 2566834855 DTC_3 999992;
BA_ "SPN" SG_ 2566834855 DTC_4 999993;
BA_ "SPN" SG_ 2566834855 DTC_5 999994;
BA_ "SPN" SG_ 2566834855 DTC_6 999995;
BA_ "SPN" SG_ 2566834855 DTC_7 999996;
BA_ "SPN" SG_ 2566834855 DTC_8 999997;
BA_ "SPN" SG_ 2566834855 DTC_9 999998;
BA_ "SPN" SG_ 2566834855 DTC_10 999999;
BA_ "SPN" SG_ 2566844839 Cruise_Control_Set_Speed 86;
BA_ "SPN" SG_ 2566844839 Cruise_Control_Active 595;
BA_ "SPN" SG_ 2566844839 Clutch_Switch 598;
BA_ "SPN" SG_ 2566844839 Brake_Switch 597;
BA_ "SPN" SG_ 2566844839 pCC_Message_Counter 524080;
BA_ "SPN" SG_ 2566844839 Cruise_Control_Pause_Switch 1633;
BA_ "SPN" SG_ 2566844839 Cruise_Control_Set_Switch 599;
BA_ "SPN" SG_ 2566844839 Two_Speed_Axle_Switch 69;
BA_ "SPN" SG_ 2566844839 Cruise_Control_Enable_Switch 596;
BA_ "SPN" SG_ 2566844839 pOdometer_Drive_Bit 523994;
BA_ "SPN" SG_ 2566844839 pCC_Checksum 524079;
BA_ "SPN" SG_ 2566844839 WheelBased_Vehicle_Speed 84;
BA_ "SPN" SG_ 2566844839 Cruise_Control_Resume_Switch 601;
BA_ "SPN" SG_ 2566844839 Cruise_Control_Accelerate_Switch 602;
BA_ "SPN" SG_ 2566844839 pCruise_Enable_Status 524108;
BA_ "SPN" SG_ 2566844839 Parking_Brake_Switch 70;
BA_ "SPN" SG_ 2566844839 Cruise_Control_Coast_Decelerate_ 600;
BA_ "SPN" SG_ 2566877607 pTemperature_Units_Selected 524266;
BA_ "SPN" SG_ 2566877607 pTPMS_Learning_Status 524104;
BA_ "SPN" SG_ 2566877607 pPressure_Units_Selected 524269;
BA_ "SPN" SG_ 2566877607 pHigh_Res_Trip_2_Distance 524264;
BA_ "SPN" SG_ 2566877607 pVolume_Units_Selected 524267;
BA_ "SPN" SG_ 2566877607 pDisplay_Status 524105;
BA_ "SPN" SG_ 2566877607 pTime_Units_Selected 524268;
BA_ "SPN" SG_ 2566877607 pDistance_Units_Selected 524265;
BA_ "SPN" SG_ 2298415599 pJunction_Temp 524203;
BA_ "SPN" SG_ 2298415599 pCapacitor_Temp 524202;
BA_ "SPN" SG_ 2298415599 pMotor_Temp_Margin 524198;
BA_ "SPN" SG_ 2298415599 pBaseplate_Temp 524199;
BA_ "SPN" SG_ 2298415599 pBoard_Temp 524200;
BA_ "SPN" SG_ 2298415599 pController_Temp_Margin 524197;
BA_ "SPN" SG_ 2298415599 pTemperature_Message_Checksum 524251;
BA_ "SPN" SG_ 2298415599 pMotor_Temp 524201;
BA_ "SPN" SG_ 2298415087 pPerformance_Message_Checksum 524249;
BA_ "SPN" SG_ 2298415087 pLower_Available_Torque_Limit 524193;
BA_ "SPN" SG_ 2298415087 pPerformance_State 524190;
BA_ "SPN" SG_ 2298415087 pActual_Motor_Torque 524191;
BA_ "SPN" SG_ 2298415087 pUpper_Available_Torque_Limit 524192;
BA_ "SPN" SG_ 2298415087 pActual_Motor_Velocity 524194;
BA_ "SPN" SG_ 2298415087 pPer_Msg_Count 520606;
BA_ "SPN" SG_ 2298415343 pController_Thermal_Cutback_Stat 524259;
BA_ "SPN" SG_ 2298415343 pCapacitor_Voltage 524196;
BA_ "SPN" SG_ 2298415343 pMotor_Power_Cutback_Status 524240;
BA_ "SPN" SG_ 2298415343 pInput_Current 524195;
BA_ "SPN" SG_ 2298415343 pMotor_Thermal_Cutback_Status 524260;
BA_ "SPN" SG_ 2298415343 pInput_DC_Current_Cutback_Status 524257;
BA_ "SPN" SG_ 2298415343 pSpeed_Limit_Cutback_Status 524258;
BA_ "SPN" SG_ 2298415343 pPower_Message_Checksum 524250;
BA_ "SPN" SG_ 2298415600 pJunction_Temp 524203;
BA_ "SPN" SG_ 2298415600 pCapacitor_Temp 524202;
BA_ "SPN" SG_ 2298415600 pMotor_Temp_Margin 524198;
BA_ "SPN" SG_ 2298415600 pBaseplate_Temp 524199;
BA_ "SPN" SG_ 2298415600 pBoard_Temp 524200;
BA_ "SPN" SG_ 2298415600 pController_Temp_Margin 524197;
BA_ "SPN" SG_ 2298415600 pTemperature_Message_Checksum 524251;
BA_ "SPN" SG_ 2298415600 pMotor_Temp 524201;
BA_ "SPN" SG_ 2298415088 pPerformance_Message_Checksum 524249;
BA_ "SPN" SG_ 2298415088 pLower_Available_Torque_Limit 524193;
BA_ "SPN" SG_ 2298415088 pPerformance_State 524190;
BA_ "SPN" SG_ 2298415088 pActual_Motor_Torque 524191;
BA_ "SPN" SG_ 2298415088 pUpper_Available_Torque_Limit 524192;
BA_ "SPN" SG_ 2298415088 pActual_Motor_Velocity 524194;
BA_ "SPN" SG_ 2298415088 pPer_Msg_Count 520606;
BA_ "SPN" SG_ 2298415344 pController_Thermal_Cutback_Stat 524259;
BA_ "SPN" SG_ 2298415344 pCapacitor_Voltage 524196;
BA_ "SPN" SG_ 2298415344 pMotor_Power_Cutback_Status 524240;
BA_ "SPN" SG_ 2298415344 pInput_Current 524195;
BA_ "SPN" SG_ 2298415344 pMotor_Thermal_Cutback_Status 524260;
BA_ "SPN" SG_ 2298415344 pInput_DC_Current_Cutback_Status 524257;
BA_ "SPN" SG_ 2298415344 pSpeed_Limit_Cutback_Status 524258;
BA_ "SPN" SG_ 2298415344 pPower_Message_Checksum 524250;
BA_ "SPN" SG_ 2298415601 pJunction_Temp 524203;
BA_ "SPN" SG_ 2298415601 pCapacitor_Temp 524202;
BA_ "SPN" SG_ 2298415601 pMotor_Temp_Margin 524198;
BA_ "SPN" SG_ 2298415601 pBaseplate_Temp 524199;
BA_ "SPN" SG_ 2298415601 pBoard_Temp 524200;
BA_ "SPN" SG_ 2298415601 pController_Temp_Margin 524197;
BA_ "SPN" SG_ 2298415601 pTemperature_Message_Checksum 524251;
BA_ "SPN" SG_ 2298415601 pMotor_Temp 524201;
BA_ "SPN" SG_ 2298415089 pPerformance_Message_Checksum 524249;
BA_ "SPN" SG_ 2298415089 pLower_Available_Torque_Limit 524193;
BA_ "SPN" SG_ 2298415089 pPerformance_State 524190;
BA_ "SPN" SG_ 2298415089 pActual_Motor_Torque 524191;
BA_ "SPN" SG_ 2298415089 pUpper_Available_Torque_Limit 524192;
BA_ "SPN" SG_ 2298415089 pActual_Motor_Velocity 524194;
BA_ "SPN" SG_ 2298415089 pPer_Msg_Count 520606;
BA_ "SPN" SG_ 2298415345 pController_Thermal_Cutback_Stat 524259;
BA_ "SPN" SG_ 2298415345 pCapacitor_Voltage 524196;
BA_ "SPN" SG_ 2298415345 pMotor_Power_Cutback_Status 524240;
BA_ "SPN" SG_ 2298415345 pInput_Current 524195;
BA_ "SPN" SG_ 2298415345 pMotor_Thermal_Cutback_Status 524260;
BA_ "SPN" SG_ 2298415345 pInput_DC_Current_Cutback_Status 524257;
BA_ "SPN" SG_ 2298415345 pSpeed_Limit_Cutback_Status 524258;
BA_ "SPN" SG_ 2298415345 pPower_Message_Checksum 524250;
BA_ "SPN" SG_ 2298415602 pJunction_Temp 524203;
BA_ "SPN" SG_ 2298415602 pCapacitor_Temp 524202;
BA_ "SPN" SG_ 2298415602 pMotor_Temp_Margin 524198;
BA_ "SPN" SG_ 2298415602 pBaseplate_Temp 524199;
BA_ "SPN" SG_ 2298415602 pBoard_Temp 524200;
BA_ "SPN" SG_ 2298415602 pController_Temp_Margin 524197;
BA_ "SPN" SG_ 2298415602 pTemperature_Message_Checksum 524251;
BA_ "SPN" SG_ 2298415602 pMotor_Temp 524201;
BA_ "SPN" SG_ 2298415090 pPerformance_Message_Checksum 524249;
BA_ "SPN" SG_ 2298415090 pLower_Available_Torque_Limit 524193;
BA_ "SPN" SG_ 2298415090 pPerformance_State 524190;
BA_ "SPN" SG_ 2298415090 pActual_Motor_Torque 524191;
BA_ "SPN" SG_ 2298415090 pUpper_Available_Torque_Limit 524192;
BA_ "SPN" SG_ 2298415090 pActual_Motor_Velocity 524194;
BA_ "SPN" SG_ 2298415090 pPer_Msg_Count 520606;
BA_ "SPN" SG_ 2298415346 pController_Thermal_Cutback_Stat 524259;
BA_ "SPN" SG_ 2298415346 pCapacitor_Voltage 524196;
BA_ "SPN" SG_ 2298415346 pMotor_Power_Cutback_Status 524240;
BA_ "SPN" SG_ 2298415346 pInput_Current 524195;
BA_ "SPN" SG_ 2298415346 pMotor_Thermal_Cutback_Status 524260;
BA_ "SPN" SG_ 2298415346 pInput_DC_Current_Cutback_Status 524257;
BA_ "SPN" SG_ 2298415346 pSpeed_Limit_Cutback_Status 524258;
BA_ "SPN" SG_ 2298415346 pPower_Message_Checksum 524250;
BA_ "SPN" SG_ 2297441779 Vertical_Acceleration_Figure_of_ 5352;
BA_ "SPN" SG_ 2297441779 Lateral_Acceleration_Figure_of_M 5350;
BA_ "SPN" SG_ 2297441779 Longitudinal_Acceleration_Extend 5348;
BA_ "SPN" SG_ 2297441779 Lateral_Acceleration_Extended_Ra 5347;
BA_ "SPN" SG_ 2297441779 Longitudinal_Acceleration_Figure 5351;
BA_ "SPN" SG_ 2297441779 Vertical_Acceleration_Extended_R 5349;
BA_ "SPN" SG_ 2297441779 Support_Variable_Transmission_Re 5353;
BA_ "SPN" SG_ 2365525747 pPack_Voltage 524217;
BA_ "SPN" SG_ 2365525747 pDischarge_Limit 524218;
BA_ "SPN" SG_ 2365525747 pPack_Current 524216;
BA_ "SPN" SG_ 2365525747 pBMC_Power_Message_Checksum 524252;
BA_ "SPN" SG_ 2365525747 pCharge_Limit 524219;
BA_ "SPN" SG_ 2365526515 pBMC_Temp 524227;
BA_ "SPN" SG_ 2365526515 pDCDC_State 524233;
BA_ "SPN" SG_ 2365526515 pBattery_Type 520404;
BA_ "SPN" SG_ 2365526515 pBalance_Error 524228;
BA_ "SPN" SG_ 2365526515 pKEY_State 524232;
BA_ "SPN" SG_ 2365526515 pBMC_Status_Counter 524273;
BA_ "SPN" SG_ 2365526515 pBalance_State 524229;
BA_ "SPN" SG_ 2365526515 pWAKE_State 524230;
BA_ "SPN" SG_ 2365526515 pBMC_Status_Message_Checksum 524255;
BA_ "SPN" SG_ 2365526003 pSOC 524220;
BA_ "SPN" SG_ 2365526003 pAvailable_Wh 524221;
BA_ "SPN" SG_ 2365526003 pWh_in_Since_key_on 524222;
BA_ "SPN" SG_ 2365526003 pEnergy_Message_Checksum 524253;
BA_ "GenMsgCycleTime" BO_ 2566878847 1000;
BA_ "GenMsgCycleTime" BO_ 2566834815 1000;
BA_ "GenMsgCycleTimeFast" BO_ 2566842495 60000;
BA_ "GenMsgCycleTime" BO_ 2365531268 500;
BA_ "GenMsgCycleTimeFast" BO_ 2365531268 10;
BA_ "GenMsgCycleTime" BO_ 2365554944 100;
BA_ "GenMsgCycleTimeFast" BO_ 2365554944 10;
BA_ "GenMsgCycleTime" BO_ 2566834823 1000;
BA_ "GenMsgCycleTime" BO_ 2432656519 500;
BA_ "GenMsgCycleTimeFast" BO_ 2432656519 200;
BA_ "GenMsgCycleTime" BO_ 2566860167 1000;
BA_ "GenMsgCycleTimeFast" BO_ 2566860167 500;
BA_ "GenMsgCycleTime" BO_ 2365555079 100;
BA_ "GenMsgCycleTimeFast" BO_ 2365555079 10;
BA_ "GenMsgCycleTime" BO_ 2566896007 1000;
BA_ "GenMsgCycleTimeFast" BO_ 2566896007 100;
BA_ "GenMsgCycleTime" BO_ 2566844807 100;
BA_ "GenMsgCycleTime" BO_ 2432656775 200;
BA_ "GenMsgCycleTimeFast" BO_ 2432656775 100;
BA_ "GenMsgCycleTime" BO_ 2566896519 1000;
BA_ "GenMsgCycleTimeFast" BO_ 2566896519 100;
BA_ "GenMsgCycleTime" BO_ 2633984647 500;
BA_ "GenMsgCycleTimeFast" BO_ 2633984647 100;
BA_ "GenMsgCycleTime" BO_ 2566877831 1000;
BA_ "GenMsgCycleTime" BO_ 2566896263 1000;
BA_ "GenMsgCycleTimeFast" BO_ 2566896263 100;
BA_ "GenMsgCycleTime" BO_ 2365523591 5000;
BA_ "GenMsgCycleTimeFast" BO_ 2365523591 50;
BA_ "GenMsgCycleTime" BO_ 2566878092 200;
BA_ "GenMsgCycleTimeFast" BO_ 2566878092 10;
BA_ "GenMsgCycleTime" BO_ 2231334284 200;
BA_ "GenMsgCycleTimeFast" BO_ 2231334284 10;
BA_ "GenMsgCycleTime" BO_ 2231313804 1000;
BA_ "GenMsgCycleTime" BO_ 2231336332 100;
BA_ "GenMsgCycleTimeFast" BO_ 2231336332 10;
BA_ "GenMsgCycleTime" BO_ 2365531276 500;
BA_ "GenMsgCycleTimeFast" BO_ 2365531276 10;
BA_ "GenMsgCycleTime" BO_ 2365536141 10;
BA_ "GenMsgCycleTime" BO_ 2365536653 10;
BA_ "GenMsgCycleTime" BO_ 2365536397 10;
BA_ "GenMsgCycleTime" BO_ 2432656784 200;
BA_ "GenMsgCycleTimeFast" BO_ 2432656784 100;
BA_ "GenMsgCycleTime" BO_ 2365473169 1000;
BA_ "GenMsgCycleTimeFast" BO_ 2365473169 100;
BA_ "GenMsgCycleTime" BO_ 2563833767 5000;
BA_ "GenMsgCycleTimeFast" BO_ 2563833767 100;
BA_ "GenMsgCycleTime" BO_ 2566847655 1000;
BA_ "GenMsgCycleTime" BO_ 2566834855 1000;
BA_ "GenMsgCycleTime" BO_ 2566844839 100;
BA_ "GenMsgCycleTime" BO_ 2566877607 1000;
BA_ "GenMsgCycleTime" BO_ 2298415599 100;
BA_ "GenMsgCycleTime" BO_ 2298415087 10;
BA_ "GenMsgCycleTime" BO_ 2298415343 100;
BA_ "GenMsgCycleTime" BO_ 2298415600 100;
BA_ "GenMsgCycleTime" BO_ 2298415088 10;
BA_ "GenMsgCycleTime" BO_ 2298415344 100;
BA_ "GenMsgCycleTime" BO_ 2298415601 100;
BA_ "GenMsgCycleTime" BO_ 2298415089 10;
BA_ "GenMsgCycleTime" BO_ 2298415345 100;
BA_ "GenMsgCycleTime" BO_ 2298415602 100;
BA_ "GenMsgCycleTime" BO_ 2298415090 10;
BA_ "GenMsgCycleTime" BO_ 2298415346 100;
BA_ "GenMsgCycleTime" BO_ 2297441779 20;
BA_ "GenMsgCycleTimeFast" BO_ 2297441779 10;
BA_ "GenMsgCycleTime" BO_ 2365525747 10;
BA_ "GenMsgCycleTime" BO_ 2365526515 100;
BA_ "GenMsgCycleTime" BO_ 2365526003 100;
VAL_ 2566878847 pDevice_1_Battery_Strength 0 "0 Bars of Battery Strength" 7 "Not Available " 6 "Error" ;
VAL_ 2566878847 pDevice_2_Bluetooth_Connection_S 2 "Error" 0 "Off" 1 "On" 3 "Not-Available" ;
VAL_ 2566878847 pDevice_2_Device_Battery_Strengt 0 "0 Bars of Battery Strength" 7 "Not Available " 6 "Error" ;
VAL_ 2566878847 pDevice_2_Cell_Signal_Strength 0 "0 Bars of Cell Signal" 7 "Not Available " 6 "Error" ;
VAL_ 2566878847 pDevice_Headset_1_Connection_Sta 2 "Error" 0 "Off" 1 "On" 3 "Not-Available" ;
VAL_ 2566878847 pDevice_1_Bluetooth_Connection_S 2 "Error" 0 "Off" 1 "On" 3 "Not-Available" ;
VAL_ 2566878847 pDevice_Headset_2_Connection_Sta 2 "Error" 0 "Off" 1 "On" 3 "Not-Available" ;
VAL_ 2365531268 pEPSReqMod 13 "13(0x0D) – EPS Assist Mode 4" 0 "0 (0x00) – Assist Off: all mosfet drivers are off, control motor is freely back driven." 11 "11(0x0B) – EPS Assist Mode 2" 10 "10(0x0A) – EPS Assist Mode 1" 12 "12(0x0C) – EPS Assist Mode 3" ;
VAL_ 2365554944 pOperator_Switch_Status_3 2 "Error" 0 "Off" 1 "On" 3 "Not-Available" ;
VAL_ 2365554944 pUpPaddleStatus 2 "Error" 0 "Off" 1 "On" 3 "Not-Available" ;
VAL_ 2365554944 pOperator_Switch_Status_2 2 "Error" 0 "Off" 1 "On" 3 "Not-Available" ;
VAL_ 2365554944 pDwPaddleStatus 2 "Error" 0 "Off" 1 "On" 3 "Not-Available" ;
VAL_ 2365554944 pOperator_Button_50_Pucker 2 "Error" 0 "Off" 1 "On" 3 "Not-Available" ;
VAL_ 2432656519 Source 2 "Error" 0 "Off" 1 "On" 3 "Not-Available" ;
VAL_ 2432656519 Squelch_SQ_Up 2 "Error" 0 "Off" 1 "On" 3 "Not-Available" ;
VAL_ 2432656519 MutePreset 2 "Error" 0 "Off" 1 "On" 3 "Not-Available" ;
VAL_ 2432656519 Volume_Down 2 "Error" 0 "Off" 1 "On" 3 "Not-Available" ;
VAL_ 2432656519 Volume_Up 2 "Error" 0 "Off" 1 "On" 3 "Not-Available" ;
VAL_ 2432656519 Tune_Up 2 "Error" 0 "Off" 1 "On" 3 "Not-Available" ;
VAL_ 2432656519 Seek_Up 2 "Error" 0 "Off" 1 "On" 3 "Not-Available" ;
VAL_ 2432656519 Tune_Down 2 "Error" 0 "Off" 1 "On" 3 "Not-Available" ;
VAL_ 2432656519 Squelch_SQ_Down 2 "Error" 0 "Off" 1 "On" 3 "Not-Available" ;
VAL_ 2432656519 pInfotainment_Joystick_1 5 "Center" 3 "Left" 0 "Neutral" 2 "Down" 1 "Up" 4 "Right" ;
VAL_ 2432656519 Preset 2 "Error" 0 "Off" 1 "On" 3 "Not-Available" ;
VAL_ 2432656519 Seek_Down 2 "Error" 0 "Off" 1 "On" 3 "Not-Available" ;
VAL_ 2432656519 pInfotainment_Joystick_2 5 "Center" 3 "Left" 0 "Neutral" 2 "Down" 1 "Up" 4 "Right" ;
VAL_ 2432656519 ICOM 2 "Error" 0 "Off" 1 "On" 3 "Not-Available" ;
VAL_ 2432656519 Push_To_Talk_PTT 2 "Error" 0 "Off" 1 "On" 3 "Not-Available" ;
VAL_ 2432656519 pMultifunction_Infotainment_Inte 2 "Error" 0 "Off" 1 "On" 3 "Not-Available" ;
VAL_ 2432656519 COM 2 "Error" 0 "Off" 1 "On" 3 "Not-Available" ;
VAL_ 2432656519 PlayPause 2 "Error" 0 "Off" 1 "On" 3 "Not-Available" ;
VAL_ 2566860167 pSpecial_Msg_12 2 "Error" 0 "Off" 1 "On" 3 "Not-Available" ;
VAL_ 2566860167 pSpecial_Msg_28 2 "Error" 0 "Off" 1 "On" 3 "Not-Available" ;
VAL_ 2566860167 pSpecial_Msg_11 2 "Error" 0 "Off" 1 "On" 3 "Not-Available" ;
VAL_ 2566860167 pSpecial_Msg_26 2 "Error" 0 "Off" 1 "On" 3 "Not-Available" ;
VAL_ 2566860167 pSpecial_Msg_24 2 "Error" 0 "Off" 1 "On" 3 "Not-Available" ;
VAL_ 2566860167 pSpecial_Msg_21 2 "Error" 0 "Off" 1 "On" 3 "Not-Available" ;
VAL_ 2566860167 pSpecial_Msg_18 2 "Error" 0 "Off" 1 "On" 3 "Not-Available" ;
VAL_ 2566860167 pSpecial_Msg_19 2 "Error" 0 "Off" 1 "On" 3 "Not-Available" ;
VAL_ 2566860167 pSpecial_Msg_1_Riding_with_Brake 2 "Error" 0 "Off" 1 "On" 3 "Not-Available" ;
VAL_ 2566860167 pSpecial_Msg_2_Regulator_Overhea 2 "Error" 0 "Off" 1 "On" 3 "Not-Available" ;
VAL_ 2566860167 pSpecial_Msg_3_Regulator_Overhea 2 "Error" 0 "Off" 1 "On" 3 "Not-Available" ;
VAL_ 2566860167 pSpecial_Msg_4_Regulator_Overhea 2 "Error" 0 "Off" 1 "On" 3 "Not-Available" ;
VAL_ 2566860167 pSpecial_Msg_5_Engine_Warmup_Com 2 "Error" 0 "Off" 1 "On" 3 "Not-Available" ;
VAL_ 2566860167 pSpecial_Msg_6_Engine_Knock__Mod 2 "Error" 0 "Off" 1 "On" 3 "Not-Available" ;
VAL_ 2566860167 pSpecial_Msg_8_Low_Coolant_Warni 2 "Error" 0 "Off" 1 "On" 3 "Not-Available" ;
VAL_ 2566860167 pSpecial_Msg_7_Engine_Knock__Mos 2 "Error" 0 "Off" 1 "On" 3 "Not-Available" ;
VAL_ 2566860167 pSpecial_Msg_9_Transmission_Temp 2 "Error" 0 "Off" 1 "On" 3 "Not-Available" ;
VAL_ 2566860167 pSpecial_Msg_10_Reverse_Speed_Li 2 "Error" 0 "Off" 1 "On" 3 "Not-Available" ;
VAL_ 2566860167 pSpecial_Msg_13_Belt_Burn_Warnin 2 "Error" 0 "Off" 1 "On" 3 "Not-Available" ;
VAL_ 2566860167 pSpecial_Msg_14_Park_Brake_Warni 2 "Error" 0 "Off" 1 "On" 3 "Not-Available" ;
VAL_ 2566860167 pSpecial_Msg_15_TCM_Comm_Loss 2 "Error" 0 "Off" 1 "On" 3 "Not-Available" ;
VAL_ 2566860167 pSpecial_Msg_16_TCM_Pump_Priming 2 "Error" 0 "Off" 1 "On" 3 "Not-Available" ;
VAL_ 2566860167 pSpecial_Msg_17_Request_User_to_ 2 "Error" 0 "Off" 1 "On" 3 "Not-Available" ;
VAL_ 2566860167 pSpecial_MSG_20_Fuel_Door_Open_E 2 "Error" 0 "Off" 1 "On" 3 "Not-Available" ;
VAL_ 2566860167 pSpecial_MSG_22_Clutch_Overtemp 2 "Error" 0 "Off" 1 "On" 3 "Not-Available" ;
VAL_ 2566860167 pSpecial_MSG_23_Exhaust_Valve_Ch 2 "Error" 0 "Off" 1 "On" 3 "Not-Available" ;
VAL_ 2566860167 pSpecial_MSG_25_Engine_Idle_Shut 2 "Error" 0 "Off" 1 "On" 3 "Not-Available" ;
VAL_ 2566860167 pSpecial_MSG_27_Overboost_Condit 2 "Error" 0 "Off" 1 "On" 3 "Not-Available" ;
VAL_ 2566860167 pSpecial_Msg_31_Engine_Tip_Over_ 2 "Error" 0 "Off" 1 "On" 3 "Not-Available" ;
VAL_ 2566860167 pSpecial_Msg_32_Engine_Tip_Over_ 2 "Error" 0 "Off" 1 "On" 3 "Not-Available" ;
VAL_ 2365555079 pOperator_Switch_Status_3 2 "Error" 0 "Off" 1 "On" 3 "Not-Available" ;
VAL_ 2365555079 pUpPaddleStatus 2 "Error" 0 "Off" 1 "On" 3 "Not-Available" ;
VAL_ 2365555079 pOperator_Switch_Status_2 2 "Error" 0 "Off" 1 "On" 3 "Not-Available" ;
VAL_ 2365555079 pDwPaddleStatus 2 "Error" 0 "Off" 1 "On" 3 "Not-Available" ;
VAL_ 2365555079 pOperator_Button_50_Pucker 2 "Error" 0 "Off" 1 "On" 3 "Not-Available" ;
VAL_ 2566896007 pAccessory_Control_Operation 0 "pAccessory Command" 255 "Not Available" 1 "pAccessory Status" ;
VAL_ 2566896007 pAccessory_Control_Mode 0 "pAccessory Off" 3 "pAccessory Setpoint 3" 2 "pAccessory Setpoint 2" 1 "pAccessory Setpoint 1" 255 "Not Available" ;
VAL_ 2566844807 pOdometer_Drive_Bit 3 "Not Available " 2 "Error" 0 "State A" 1 "State B" ;
VAL_ 2566844807 pCruise_Enable_Status 14 "Error" 15 "Not Available " 0 "Not enabled. System must be enabled before it is set" 1 "Enable. System is ready to be set by operator. Only change state when system is enabled/disabled with on/off switch" ;
VAL_ 2432656775 Key_Fob_Unlock_Button_Status 2 "Error" 0 "Off" 1 "On" 3 "Not-Available" ;
VAL_ 2432656775 Homelink_2 2 "Error" 0 "Off" 1 "On" 3 "Not-Available" ;
VAL_ 2432656775 Side_Stand_Switch 2 "Error" 0 "Off" 1 "On" 3 "Not-Available" ;
VAL_ 2432656775 Key_Fob_Lock_Button_Status 2 "Error" 0 "Off" 1 "On" 3 "Not-Available" ;
VAL_ 2432656775 Windshield__2_Down 2 "Error" 0 "Off" 1 "On" 3 "Not-Available" ;
VAL_ 2432656775 Turn__3_Cancel 2 "Error" 0 "Off" 1 "On" 3 "Not-Available" ;
VAL_ 2432656775 Reverse 2 "Error" 0 "Off" 1 "On" 3 "Not-Available" ;
VAL_ 2432656775 Hazard 2 "Error" 0 "Off" 1 "On" 3 "Not-Available" ;
VAL_ 2432656775 Homelink_1 2 "Error" 0 "Off" 1 "On" 3 "Not-Available" ;
VAL_ 2432656775 Windshield__1_Up 2 "Error" 0 "Off" 1 "On" 3 "Not-Available" ;
VAL_ 2432656775 Front_Brake_Switch 2 "Error" 0 "Off" 1 "On" 3 "Not-Available" ;
VAL_ 2432656775 Instrument_Cluster_Control__2 2 "Error" 0 "Off" 1 "On" 3 "Not-Available" ;
VAL_ 2432656775 Chassis_Unlock_Button_Status 2 "Error" 0 "Off" 1 "On" 3 "Not-Available" ;
VAL_ 2432656775 Power_Button 2 "Error" 0 "Off" 1 "On" 3 "Not-Available" ;
VAL_ 2432656775 RunStop_Switch 2 "Error" 0 "Off" 1 "On" 3 "Not-Available" ;
VAL_ 2432656775 Headlamp__2_High 2 "Error" 0 "Off" 1 "On" 3 "Not-Available" ;
VAL_ 2432656775 Instrument_Cluster_Control__1 2 "Error" 0 "Off" 1 "On" 3 "Not-Available" ;
VAL_ 2432656775 Clutch_Switch 2 "Error" 0 "Off" 1 "On" 3 "Not-Available" ;
VAL_ 2432656775 Start 2 "Error" 0 "Off" 1 "On" 3 "Not-Available" ;
VAL_ 2432656775 Headlamp__3_Driving 2 "Error" 0 "Off" 1 "On" 3 "Not-Available" ;
VAL_ 2432656775 Cruise__2_Set 2 "Error" 0 "Off" 1 "On" 3 "Not-Available" ;
VAL_ 2432656775 Windshield_Wiper 2 "Error" 0 "Off" 1 "On" 3 "Not-Available" ;
VAL_ 2432656775 Fog 2 "Error" 0 "Off" 1 "On" 3 "Not-Available" ;
VAL_ 2432656775 Cruise__3_Accel 2 "Error" 0 "Off" 1 "On" 3 "Not-Available" ;
VAL_ 2432656775 Horn 2 "Error" 0 "Off" 1 "On" 3 "Not-Available" ;
VAL_ 2432656775 Turn__2_Right 2 "Error" 0 "Off" 1 "On" 3 "Not-Available" ;
VAL_ 2432656775 Cruise__1_On 2 "Error" 0 "Off" 1 "On" 3 "Not-Available" ;
VAL_ 2432656775 Turn__1_Left 2 "Error" 0 "Off" 1 "On" 3 "Not-Available" ;
VAL_ 2432656775 Throttle_Safety_Switch__1 2 "Error" 0 "Off" 1 "On" 3 "Not-Available" ;
VAL_ 2432656775 Headlamp__1_Low 2 "Error" 0 "Off" 1 "On" 3 "Not-Available" ;
VAL_ 2432656775 Fuel_Door_Unlock_Button_Status 2 "Error Indicator" 3 "Not Available" 1 "Button pressed" 0 "Button not pressed" ;
VAL_ 2633984647 pHeated_Grip_Enable 2 "Error" 0 "Off" 1 "On" 3 "Not-Available" ;
VAL_ 2633984647 pUser_PIN_Access_Status 2 "Error" 0 "Off" 1 "On" 3 "Not-Available" ;
VAL_ 2633984647 pActive_Descent_Control_ADC_Stat 2 "Error" 0 "Off" 1 "On" 3 "Not-Available" ;
VAL_ 2633984647 pCruise_Control_Set_Status 2 "Error" 0 "Off" 1 "On" 3 "Not-Available" ;
VAL_ 2633984647 pTether_Switch_Status 2 "Error" 0 "Off" 1 "On" 3 "Not-Available" ;
VAL_ 2633984647 pHigh_Beam_Indicator_Status 2 "Error" 0 "Off" 1 "On" 3 "Not-Available" ;
VAL_ 2633984647 pLow_Fuel_Indicator_Status 2 "Error" 0 "Off" 1 "On" 3 "Not-Available" ;
VAL_ 2633984647 pSide_Stand_Status 2 "Error" 1 "Side Stand Extended" 0 "Side Stand Retracted" 3 "Not Available" ;
VAL_ 2633984647 pTurf_Mode_Requested 2 "Error" 0 "Off" 1 "On" 3 "Not-Available" ;
VAL_ 2633984647 Operator_Not_in_Operating_Statio 2 "Error" 0 "Off" 1 "On" 3 "Not-Available" ;
VAL_ 2633984647 pAWD_Mode_Requested 2 "Error" 0 "Off" 1 "On" 3 "Not-Available" ;
VAL_ 2633984647 pHeated_Grips_Up_Switch_Status 2 "Error" 0 "Off" 1 "On" 3 "Not-Available" ;
VAL_ 2633984647 pTreadle_Neutral_Status 2 "Error" 0 "Off" 1 "On" 3 "Not-Available" ;
VAL_ 2633984647 pHeated_Grips_Down_Switch_Status 2 "Error" 0 "Off" 1 "On" 3 "Not-Available" ;
VAL_ 2633984647 pPark_Brake_Indicator_Status 2 "Slow Flash (1 Hz, 50% duty cycle)" 7 "Not Available" 1 "On" 3 "Fast Flash (2 HZ or faster, 50% Duty Cycle)" 0 "Off" 6 "Error" ;
VAL_ 2633984647 pRWD_Mode_Requested 2 "Error" 0 "Off" 1 "On" 3 "Not-Available" ;
VAL_ 2633984647 pSeat_Belt_Indicator_Status 2 "Slow Flash (1 Hz, 50% duty cycle)" 7 "Not Available" 1 "On" 3 "Fast Flash (2 HZ or faster, 50% Duty Cycle)" 0 "Off" 6 "Error" ;
VAL_ 2633984647 pSecurity_Light_Immobilizer_Stat 2 "Error" 0 "Off" 1 "On" 3 "Not-Available" ;
VAL_ 2633984647 ECU_Security_Status 1 "Locked, Awaiting Unlock" 3 " Locked, system will shut down" 0 "Unlocked" 7 "Not Available" 2 "Locked, System will not shut down" 6 "Error" ;
VAL_ 2633984647 pActive_Decent_Control_ADC_Mode_ 2 "Error" 0 "Off" 1 "On" 3 "Not-Available" ;
VAL_ 2633984647 pTreadle_Reverse_Status 2 "Error" 0 "Off" 1 "On" 3 "Not-Available" ;
VAL_ 2365523591 pModule_Control_Applied_State 1 "Partial Wakeup Applied " 0 "No Change Applied" 2 "Full Wakeup Applied" 3 "Power Down Applied " 13 "No Change - Checksum Error " 4 "Stay Awake Applied " 14 "Error State" 15 "Not Available" 5 "Alarm Activation Applied " ;
VAL_ 2365523591 pModule_Control_Command_State 3 "Power Down Requested" 2 "Full Wakeup Requested" 15 "Not Available" 14 "Error" 5 "Alarm Activation Requested" 1 "Partial Wakeup Requested" 4 "Stay Awake Requested" 0 "No Change Requested" ;
VAL_ 2566878092 pEPS_Commanded_Control_Mode 3 "Speed: mosfets powered, unit responds to hold or attain a given speed and direction." 0 "Off: all mosfet drivers are off, control motor is freely back driven." 5 "Position w/ Speed: mosfets powered, unit responds to hold or attain a given angular position without exceeding a given angular speed." 2 "Torque Assist: mosfets powered, unit responds to torque input, current command is generated using the programmed assist curve." 16 "Set Position: all Mosfets drivers are off, sets the unit current position to the given value then transfers to off mode." 4 "Position: mosfets powered, unit responds to hold or attain a given angular position." ;
VAL_ 2231336332 pEBC_Mode_Status 4 "Reserved" 5 "Reserved" 6 "Error" 1 "Manned NonAssist" 2 "Remote Mode" 3 "Reserved" 0 "Manned Assist Mode" 7 "NA" ;
VAL_ 2365531276 pEPSReqMod 13 "13(0x0D) – EPS Assist Mode 4" 0 "0 (0x00) – Assist Off: all mosfet drivers are off, control motor is freely back driven." 11 "11(0x0B) – EPS Assist Mode 2" 10 "10(0x0A) – EPS Assist Mode 1" 12 "12(0x0C) – EPS Assist Mode 3" ;
VAL_ 2365536141 pAngular_Rate_Signal_3_Status 6 " Initalization is Running and Signal Error" 1 "Signal Not Available" 4 "Initialization is Running" 5 " Initalization is Running and Signal N/A" 3 "Signal Error Set and N/A" 2 "Signal Error Set" 0 "Signal OK + Initialization is ready + Signal Available" ;
VAL_ 2365536141 pAcceleration_Sensor_Signal_2_St 6 " Initalization is Running and Signal Error" 1 "Signal Not Available" 4 "Initialization is Running" 5 " Initalization is Running and Signal N/A" 3 "Signal Error Set and N/A" 2 "Signal Error Set" 0 "Signal OK + Initialization is ready + Signal Available" ;
VAL_ 2365536653 pAngular_Rate_Signal_1_Status 6 " Initalization is Running and Signal Error" 1 "Signal Not Available" 4 "Initialization is Running" 5 " Initalization is Running and Signal N/A" 3 "Signal Error Set and N/A" 2 "Signal Error Set" 0 "Signal OK + Initialization is ready + Signal Available" ;
VAL_ 2365536653 pAcceleration_Sensor_Signal_1_St 6 " Initalization is Running and Signal Error" 1 "Signal Not Available" 4 "Initialization is Running" 5 " Initalization is Running and Signal N/A" 3 "Signal Error Set and N/A" 2 "Signal Error Set" 0 "Signal OK + Initialization is ready + Signal Available" ;
VAL_ 2365536397 pAcceleration_Sensor_Signal_3_St 6 " Initalization is Running and Signal Error" 1 "Signal Not Available" 4 "Initialization is Running" 5 " Initalization is Running and Signal N/A" 3 "Signal Error Set and N/A" 2 "Signal Error Set" 0 "Signal OK + Initialization is ready + Signal Available" ;
VAL_ 2365536397 pAngular_Rate_Signal_2_Status 6 " Initalization is Running and Signal Error" 1 "Signal Not Available" 4 "Initialization is Running" 5 " Initalization is Running and Signal N/A" 3 "Signal Error Set and N/A" 2 "Signal Error Set" 0 "Signal OK + Initialization is ready + Signal Available" ;
VAL_ 2432656784 Key_Fob_Unlock_Button_Status 2 "Error" 0 "Off" 1 "On" 3 "Not-Available" ;
VAL_ 2432656784 Homelink_2 2 "Error" 0 "Off" 1 "On" 3 "Not-Available" ;
VAL_ 2432656784 Side_Stand_Switch 2 "Error" 0 "Off" 1 "On" 3 "Not-Available" ;
VAL_ 2432656784 Key_Fob_Lock_Button_Status 2 "Error" 0 "Off" 1 "On" 3 "Not-Available" ;
VAL_ 2432656784 Windshield__2_Down 2 "Error" 0 "Off" 1 "On" 3 "Not-Available" ;
VAL_ 2432656784 Turn__3_Cancel 2 "Error" 0 "Off" 1 "On" 3 "Not-Available" ;
VAL_ 2432656784 Reverse 2 "Error" 0 "Off" 1 "On" 3 "Not-Available" ;
VAL_ 2432656784 Hazard 2 "Error" 0 "Off" 1 "On" 3 "Not-Available" ;
VAL_ 2432656784 Homelink_1 2 "Error" 0 "Off" 1 "On" 3 "Not-Available" ;
VAL_ 2432656784 Windshield__1_Up 2 "Error" 0 "Off" 1 "On" 3 "Not-Available" ;
VAL_ 2432656784 Front_Brake_Switch 2 "Error" 0 "Off" 1 "On" 3 "Not-Available" ;
VAL_ 2432656784 Instrument_Cluster_Control__2 2 "Error" 0 "Off" 1 "On" 3 "Not-Available" ;
VAL_ 2432656784 Chassis_Unlock_Button_Status 2 "Error" 0 "Off" 1 "On" 3 "Not-Available" ;
VAL_ 2432656784 Power_Button 2 "Error" 0 "Off" 1 "On" 3 "Not-Available" ;
VAL_ 2432656784 RunStop_Switch 2 "Error" 0 "Off" 1 "On" 3 "Not-Available" ;
VAL_ 2432656784 Headlamp__2_High 2 "Error" 0 "Off" 1 "On" 3 "Not-Available" ;
VAL_ 2432656784 Instrument_Cluster_Control__1 2 "Error" 0 "Off" 1 "On" 3 "Not-Available" ;
VAL_ 2432656784 Clutch_Switch 2 "Error" 0 "Off" 1 "On" 3 "Not-Available" ;
VAL_ 2432656784 Start 2 "Error" 0 "Off" 1 "On" 3 "Not-Available" ;
VAL_ 2432656784 Headlamp__3_Driving 2 "Error" 0 "Off" 1 "On" 3 "Not-Available" ;
VAL_ 2432656784 Cruise__2_Set 2 "Error" 0 "Off" 1 "On" 3 "Not-Available" ;
VAL_ 2432656784 Windshield_Wiper 2 "Error" 0 "Off" 1 "On" 3 "Not-Available" ;
VAL_ 2432656784 Fog 2 "Error" 0 "Off" 1 "On" 3 "Not-Available" ;
VAL_ 2432656784 Cruise__3_Accel 2 "Error" 0 "Off" 1 "On" 3 "Not-Available" ;
VAL_ 2432656784 Horn 2 "Error" 0 "Off" 1 "On" 3 "Not-Available" ;
VAL_ 2432656784 Turn__2_Right 2 "Error" 0 "Off" 1 "On" 3 "Not-Available" ;
VAL_ 2432656784 Cruise__1_On 2 "Error" 0 "Off" 1 "On" 3 "Not-Available" ;
VAL_ 2432656784 Turn__1_Left 2 "Error" 0 "Off" 1 "On" 3 "Not-Available" ;
VAL_ 2432656784 Throttle_Safety_Switch__1 2 "Error" 0 "Off" 1 "On" 3 "Not-Available" ;
VAL_ 2432656784 Headlamp__1_Low 2 "Error" 0 "Off" 1 "On" 3 "Not-Available" ;
VAL_ 2432656784 Fuel_Door_Unlock_Button_Status 2 "Error Indicator" 3 "Not Available" 1 "Button pressed" 0 "Button not pressed" ;
VAL_ 2566844839 pOdometer_Drive_Bit 3 "Not Available " 2 "Error" 0 "State A" 1 "State B" ;
VAL_ 2566844839 pCruise_Enable_Status 14 "Error" 15 "Not Available " 0 "Not enabled. System must be enabled before it is set" 1 "Enable. System is ready to be set by operator. Only change state when system is enabled/disabled with on/off switch" ;
VAL_ 2566877607 pTemperature_Units_Selected 0 "Fahrenheit" 1 "Celsius" 3 "Not Available" 2 "Error" ;
VAL_ 2566877607 pTPMS_Learning_Status 7 "Learning Spare Tire" 3 "Learning right front" 1 "Request to start" 13 "Request to end learning process" 14 "Error failed to complete learning process" 2 "Learning left front" 0 "Not started" 5 "Learning right rear" 4 "Learning left rear" 6 "Learning processes successfully completed" 12 "Erase TPMS Sensors" 15 "Not Available" ;
VAL_ 2566877607 pPressure_Units_Selected 3 "Not Available" 1 "Kilopascal (KPa)" 2 "Error" 0 "Pounds Per Square Inch (PSI)" ;
VAL_ 2566877607 pVolume_Units_Selected 6 "Error" 1 "Liters" 0 "Gallons" 7 "Not Avialable" 2 "Imperial Gallons" ;
VAL_ 2566877607 pDisplay_Status 2 "Infotainment can override to full screen" 1 "User has requested full screen" 0 "Infotainment cannot override to full screen" 14 "Infotainment data not being shown" 15 "Not Available" ;
VAL_ 2566877607 pTime_Units_Selected 1 "24 Hour" 3 "Not Available" 0 "12 Hour" 2 "Error" ;
VAL_ 2566877607 pDistance_Units_Selected 1 "Kilometers" 0 "Miles" 3 "Not Available " 2 "Error" ;
VAL_ 2298415087 pPerformance_State 1 "Shutdown" 2 "Precharge" 0 "Initialize" 3 "Energized" 15 "Not Available" 5 "Fault Off" 4 "Enabled" 6 "Fault Reaction" ;
VAL_ 2298415343 pController_Thermal_Cutback_Stat 0 "Inactive" 1 "Active" ;
VAL_ 2298415343 pMotor_Power_Cutback_Status 0 "Inactive" 1 "Active" ;
VAL_ 2298415343 pMotor_Thermal_Cutback_Status 0 "Inactive" 1 "Active" ;
VAL_ 2298415343 pInput_DC_Current_Cutback_Status 0 "Inactive" 1 "Active" ;
VAL_ 2298415343 pSpeed_Limit_Cutback_Status 0 "Inactive" 1 "Active" ;
VAL_ 2298415088 pPerformance_State 1 "Shutdown" 2 "Precharge" 0 "Initialize" 3 "Energized" 15 "Not Available" 5 "Fault Off" 4 "Enabled" 6 "Fault Reaction" ;
VAL_ 2298415344 pController_Thermal_Cutback_Stat 0 "Inactive" 1 "Active" ;
VAL_ 2298415344 pMotor_Power_Cutback_Status 0 "Inactive" 1 "Active" ;
VAL_ 2298415344 pMotor_Thermal_Cutback_Status 0 "Inactive" 1 "Active" ;
VAL_ 2298415344 pInput_DC_Current_Cutback_Status 0 "Inactive" 1 "Active" ;
VAL_ 2298415344 pSpeed_Limit_Cutback_Status 0 "Inactive" 1 "Active" ;
VAL_ 2298415089 pPerformance_State 1 "Shutdown" 2 "Precharge" 0 "Initialize" 3 "Energized" 15 "Not Available" 5 "Fault Off" 4 "Enabled" 6 "Fault Reaction" ;
VAL_ 2298415345 pController_Thermal_Cutback_Stat 0 "Inactive" 1 "Active" ;
VAL_ 2298415345 pMotor_Power_Cutback_Status 0 "Inactive" 1 "Active" ;
VAL_ 2298415345 pMotor_Thermal_Cutback_Status 0 "Inactive" 1 "Active" ;
VAL_ 2298415345 pInput_DC_Current_Cutback_Status 0 "Inactive" 1 "Active" ;
VAL_ 2298415345 pSpeed_Limit_Cutback_Status 0 "Inactive" 1 "Active" ;
VAL_ 2298415090 pPerformance_State 1 "Shutdown" 2 "Precharge" 0 "Initialize" 3 "Energized" 15 "Not Available" 5 "Fault Off" 4 "Enabled" 6 "Fault Reaction" ;
VAL_ 2298415346 pController_Thermal_Cutback_Stat 0 "Inactive" 1 "Active" ;
VAL_ 2298415346 pMotor_Power_Cutback_Status 0 "Inactive" 1 "Active" ;
VAL_ 2298415346 pMotor_Thermal_Cutback_Status 0 "Inactive" 1 "Active" ;
VAL_ 2298415346 pInput_DC_Current_Cutback_Status 0 "Inactive" 1 "Active" ;
VAL_ 2298415346 pSpeed_Limit_Cutback_Status 0 "Inactive" 1 "Active" ;
VAL_ 2365526515 pDCDC_State 6 "Error" 0 "Off" 7 "Not Available" 4 "Powered, Disabled" 5 "Powered, Enabled" ;
VAL_ 2365526515 pKEY_State 2 "Error" 0 "Off" 1 "On" 3 "Not-Available" ;
VAL_ 2365526515 pBalance_State 4 "Charging" 8 "Relaxing" 15 "Not Available" 2 "Resting" 1 "Driving" 0 "Power Up" ;
VAL_ 2365526515 pWAKE_State 2 "Error" 0 "Off" 1 "On" 3 "Not-Available" ;
